VERSION ""

NS_ :

BS_:

BU_:

BO_ 2364626430 ECCP17: 8 Vector__XXX
 SG_ EngineCylinder17Timing1Pressure : 0|16@1+ (0.0009765625,0) [0|62.7490234375] "MPa" Vector__XXX
 SG_ EngineCylinder17Timing2Pressure : 16|16@1+ (0.0009765625,0) [0|62.7490234375] "MPa" Vector__XXX
 SG_ EngineCylinder17Timing3Pressure : 32|16@1+ (0.0009765625,0) [0|62.7490234375] "MPa" Vector__XXX
 SG_ EngineCylinder17Timing4Pressure : 48|16@1+ (0.0009765625,0) [0|62.7490234375] "MPa" Vector__XXX

BO_ 2364626686 ECCP18: 8 Vector__XXX
 SG_ EngineCylinder18Timing1Pressure : 0|16@1+ (0.0009765625,0) [0|62.7490234375] "MPa" Vector__XXX
 SG_ EngineCylinder18Timing2Pressure : 16|16@1+ (0.0009765625,0) [0|62.7490234375] "MPa" Vector__XXX
 SG_ EngineCylinder18Timing3Pressure : 32|16@1+ (0.0009765625,0) [0|62.7490234375] "MPa" Vector__XXX
 SG_ EngineCylinder18Timing4Pressure : 48|16@1+ (0.0009765625,0) [0|62.7490234375] "MPa" Vector__XXX

BO_ 2364626942 ECCP19: 8 Vector__XXX
 SG_ EngineCylinder19Timing1Pressure : 0|16@1+ (0.0009765625,0) [0|62.7490234375] "MPa" Vector__XXX
 SG_ EngineCylinder19Timing2Pressure : 16|16@1+ (0.0009765625,0) [0|62.7490234375] "MPa" Vector__XXX
 SG_ EngineCylinder19Timing3Pressure : 32|16@1+ (0.0009765625,0) [0|62.7490234375] "MPa" Vector__XXX
 SG_ EngineCylinder19Timing4Pressure : 48|16@1+ (0.0009765625,0) [0|62.7490234375] "MPa" Vector__XXX

BO_ 2364627198 ECCP20: 8 Vector__XXX
 SG_ EngineCylinder20Timing1Pressure : 0|16@1+ (0.0009765625,0) [0|62.7490234375] "MPa" Vector__XXX
 SG_ EngineCylinder20Timing2Pressure : 16|16@1+ (0.0009765625,0) [0|62.7490234375] "MPa" Vector__XXX
 SG_ EngineCylinder20Timing3Pressure : 32|16@1+ (0.0009765625,0) [0|62.7490234375] "MPa" Vector__XXX
 SG_ EngineCylinder20Timing4Pressure : 48|16@1+ (0.0009765625,0) [0|62.7490234375] "MPa" Vector__XXX

BO_ 2364627454 ECCT1: 8 Vector__XXX
 SG_ EngnClndr1InstntnsCmstnTmngPnt1 : 32|16@1+ (0.00390625,-125) [-125|125.99609375] "deg" Vector__XXX
 SG_ EngnClndr1InstntnsCmstnTmngPnt2 : 48|16@1+ (0.00390625,-125) [-125|125.99609375] "deg" Vector__XXX
 SG_ ECd1IsttsSttOCstT : 0|16@1+ (0.00390625,-125) [-125|125.99609375] "deg" Vector__XXX
 SG_ ECd1IsttsCtOCstT : 16|16@1+ (0.00390625,-125) [-125|125.99609375] "deg" Vector__XXX

BO_ 2364627710 ECCT2: 8 Vector__XXX
 SG_ EngnClndr2InstntnsCmstnTmngPnt1 : 32|16@1+ (0.00390625,-125) [-125|125.99609375] "deg" Vector__XXX
 SG_ EngnClndr2InstntnsCmstnTmngPnt2 : 48|16@1+ (0.00390625,-125) [-125|125.99609375] "deg" Vector__XXX
 SG_ ECd2IsttsSttOCstT : 0|16@1+ (0.00390625,-125) [-125|125.99609375] "deg" Vector__XXX
 SG_ ECd2IsttsCtOCstT : 16|16@1+ (0.00390625,-125) [-125|125.99609375] "deg" Vector__XXX

BO_ 2364627966 ECCT3: 8 Vector__XXX
 SG_ EngnClndr3InstntnsCmstnTmngPnt1 : 32|16@1+ (0.00390625,-125) [-125|125.99609375] "deg" Vector__XXX
 SG_ EngnClndr3InstntnsCmstnTmngPnt2 : 48|16@1+ (0.00390625,-125) [-125|125.99609375] "deg" Vector__XXX
 SG_ ECd3IsttsSttOCstT : 0|16@1+ (0.00390625,-125) [-125|125.99609375] "deg" Vector__XXX
 SG_ ECd3IsttsCtOCstT : 16|16@1+ (0.00390625,-125) [-125|125.99609375] "deg" Vector__XXX

BO_ 2364628222 ECCT4: 8 Vector__XXX
 SG_ EngnClndr4InstntnsCmstnTmngPnt1 : 32|16@1+ (0.00390625,-125) [-125|125.99609375] "deg" Vector__XXX
 SG_ EngnClndr4InstntnsCmstnTmngPnt2 : 48|16@1+ (0.00390625,-125) [-125|125.99609375] "deg" Vector__XXX
 SG_ ECd4IsttsSttOCstT : 0|16@1+ (0.00390625,-125) [-125|125.99609375] "deg" Vector__XXX
 SG_ ECd4IsttsCtOCstT : 16|16@1+ (0.00390625,-125) [-125|125.99609375] "deg" Vector__XXX

BO_ 2364628478 ECCT5: 8 Vector__XXX
 SG_ EngnClndr5InstntnsCmstnTmngPnt1 : 32|16@1+ (0.00390625,-125) [-125|125.99609375] "deg" Vector__XXX
 SG_ EngnClndr5InstntnsCmstnTmngPnt2 : 48|16@1+ (0.00390625,-125) [-125|125.99609375] "deg" Vector__XXX
 SG_ ECd5IsttsSttOCstT : 0|16@1+ (0.00390625,-125) [-125|125.99609375] "deg" Vector__XXX
 SG_ ECd5IsttsCtOCstT : 16|16@1+ (0.00390625,-125) [-125|125.99609375] "deg" Vector__XXX

BO_ 2364628734 ECCT6: 8 Vector__XXX
 SG_ EngnClndr6InstntnsCmstnTmngPnt1 : 32|16@1+ (0.00390625,-125) [-125|125.99609375] "deg" Vector__XXX
 SG_ EngnClndr6InstntnsCmstnTmngPnt2 : 48|16@1+ (0.00390625,-125) [-125|125.99609375] "deg" Vector__XXX
 SG_ ECd6IsttsSttOCstT : 0|16@1+ (0.00390625,-125) [-125|125.99609375] "deg" Vector__XXX
 SG_ ECd6IsttsCtOCstT : 16|16@1+ (0.00390625,-125) [-125|125.99609375] "deg" Vector__XXX

BO_ 2364628990 ECCT7: 8 Vector__XXX
 SG_ EngnClndr7InstntnsCmstnTmngPnt1 : 32|16@1+ (0.00390625,-125) [-125|125.99609375] "deg" Vector__XXX
 SG_ EngnClndr7InstntnsCmstnTmngPnt2 : 48|16@1+ (0.00390625,-125) [-125|125.99609375] "deg" Vector__XXX
 SG_ ECd7IsttsSttOCstT : 0|16@1+ (0.00390625,-125) [-125|125.99609375] "deg" Vector__XXX
 SG_ ECd7IsttsCtOCstT : 16|16@1+ (0.00390625,-125) [-125|125.99609375] "deg" Vector__XXX

BO_ 2364629246 ECCT8: 8 Vector__XXX
 SG_ EngnClndr8InstntnsCmstnTmngPnt1 : 32|16@1+ (0.00390625,-125) [-125|125.99609375] "deg" Vector__XXX
 SG_ EngnClndr8InstntnsCmstnTmngPnt2 : 48|16@1+ (0.00390625,-125) [-125|125.99609375] "deg" Vector__XXX
 SG_ ECd8IsttsSttOCstT : 0|16@1+ (0.00390625,-125) [-125|125.99609375] "deg" Vector__XXX
 SG_ ECd8IsttsCtOCstT : 16|16@1+ (0.00390625,-125) [-125|125.99609375] "deg" Vector__XXX

BO_ 2364629502 ECCT9: 8 Vector__XXX
 SG_ EngnClndr9InstntnsCmstnTmngPnt1 : 32|16@1+ (0.00390625,-125) [-125|125.99609375] "deg" Vector__XXX
 SG_ EngnClndr9InstntnsCmstnTmngPnt2 : 48|16@1+ (0.00390625,-125) [-125|125.99609375] "deg" Vector__XXX
 SG_ ECd9IsttsSttOCstT : 0|16@1+ (0.00390625,-125) [-125|125.99609375] "deg" Vector__XXX
 SG_ ECd9IsttsCtOCstT : 16|16@1+ (0.00390625,-125) [-125|125.99609375] "deg" Vector__XXX

BO_ 2364629758 ECCT10: 8 Vector__XXX
 SG_ ECd10IsttsCstTPt1 : 32|16@1+ (0.00390625,-125) [-125|125.99609375] "deg" Vector__XXX
 SG_ ECd10IsttsCstTPt2 : 48|16@1+ (0.00390625,-125) [-125|125.99609375] "deg" Vector__XXX
 SG_ ECd10IsttsSttOCstT : 0|16@1+ (0.00390625,-125) [-125|125.99609375] "deg" Vector__XXX
 SG_ ECd10IsttsCtOCstT : 16|16@1+ (0.00390625,-125) [-125|125.99609375] "deg" Vector__XXX

BO_ 2364630014 ECCT11: 8 Vector__XXX
 SG_ ECd11IsttsCstTPt1 : 32|16@1+ (0.00390625,-125) [-125|125.99609375] "deg" Vector__XXX
 SG_ ECd11IsttsCstTPt2 : 48|16@1+ (0.00390625,-125) [-125|125.99609375] "deg" Vector__XXX
 SG_ ECd11IsttsSttOCstT : 0|16@1+ (0.00390625,-125) [-125|125.99609375] "deg" Vector__XXX
 SG_ ECd11IsttsCtOCstT : 16|16@1+ (0.00390625,-125) [-125|125.99609375] "deg" Vector__XXX

BO_ 2364630270 ECCT12: 8 Vector__XXX
 SG_ ECd12IsttsCstTPt1 : 32|16@1+ (0.00390625,-125) [-125|125.99609375] "deg" Vector__XXX
 SG_ ECd12IsttsCstTPt2 : 48|16@1+ (0.00390625,-125) [-125|125.99609375] "deg" Vector__XXX
 SG_ ECd12IsttsSttOCstT : 0|16@1+ (0.00390625,-125) [-125|125.99609375] "deg" Vector__XXX
 SG_ ECd12IsttsCtOCstT : 16|16@1+ (0.00390625,-125) [-125|125.99609375] "deg" Vector__XXX

BO_ 2364630526 ECCT13: 8 Vector__XXX
 SG_ ECd13IsttsCstTPt1 : 32|16@1+ (0.00390625,-125) [-125|125.99609375] "deg" Vector__XXX
 SG_ ECd13IsttsCstTPt2 : 48|16@1+ (0.00390625,-125) [-125|125.99609375] "deg" Vector__XXX
 SG_ ECd13IsttsSttOCstT : 0|16@1+ (0.00390625,-125) [-125|125.99609375] "deg" Vector__XXX
 SG_ ECd13IsttsCtOCstT : 16|16@1+ (0.00390625,-125) [-125|125.99609375] "deg" Vector__XXX

BO_ 2364630782 ECCT14: 8 Vector__XXX
 SG_ ECd14IsttsCstTPt1 : 32|16@1+ (0.00390625,-125) [-125|125.99609375] "deg" Vector__XXX
 SG_ ECd14IsttsCstTPt2 : 48|16@1+ (0.00390625,-125) [-125|125.99609375] "deg" Vector__XXX
 SG_ ECd14IsttsSttOCstT : 0|16@1+ (0.00390625,-125) [-125|125.99609375] "deg" Vector__XXX
 SG_ ECd14IsttsCtOCstT : 16|16@1+ (0.00390625,-125) [-125|125.99609375] "deg" Vector__XXX

BO_ 2364631038 ECCT15: 8 Vector__XXX
 SG_ ECd15IsttsCstTPt1 : 32|16@1+ (0.00390625,-125) [-125|125.99609375] "deg" Vector__XXX
 SG_ ECd15IsttsCstTPt2 : 48|16@1+ (0.00390625,-125) [-125|125.99609375] "deg" Vector__XXX
 SG_ ECd15IsttsSttOCstT : 0|16@1+ (0.00390625,-125) [-125|125.99609375] "deg" Vector__XXX
 SG_ ECd15IsttsCtOCstT : 16|16@1+ (0.00390625,-125) [-125|125.99609375] "deg" Vector__XXX

BO_ 2364631294 ECCT16: 8 Vector__XXX
 SG_ ECd16IsttsCstTPt1 : 32|16@1+ (0.00390625,-125) [-125|125.99609375] "deg" Vector__XXX
 SG_ ECd16IsttsCstTPt2 : 48|16@1+ (0.00390625,-125) [-125|125.99609375] "deg" Vector__XXX
 SG_ ECd16IsttsSttOCstT : 0|16@1+ (0.00390625,-125) [-125|125.99609375] "deg" Vector__XXX
 SG_ ECd16IsttsCtOCstT : 16|16@1+ (0.00390625,-125) [-125|125.99609375] "deg" Vector__XXX

BO_ 2364631550 ECCT17: 8 Vector__XXX
 SG_ ECd17IsttsCstTPt1 : 32|16@1+ (0.00390625,-125) [-125|125.99609375] "deg" Vector__XXX
 SG_ ECd17IsttsCstTPt2 : 48|16@1+ (0.00390625,-125) [-125|125.99609375] "deg" Vector__XXX
 SG_ ECd17IsttsSttOCstT : 0|16@1+ (0.00390625,-125) [-125|125.99609375] "deg" Vector__XXX
 SG_ ECd17IsttsCtOCstT : 16|16@1+ (0.00390625,-125) [-125|125.99609375] "deg" Vector__XXX

BO_ 2364631806 ECCT18: 8 Vector__XXX
 SG_ ECd18IsttsCstTPt1 : 32|16@1+ (0.00390625,-125) [-125|125.99609375] "deg" Vector__XXX
 SG_ ECd18IsttsCstTPt2 : 48|16@1+ (0.00390625,-125) [-125|125.99609375] "deg" Vector__XXX
 SG_ ECd18IsttsSttOCstT : 0|16@1+ (0.00390625,-125) [-125|125.99609375] "deg" Vector__XXX
 SG_ ECd18IsttsCtOCstT : 16|16@1+ (0.00390625,-125) [-125|125.99609375] "deg" Vector__XXX

BO_ 2364632062 ECCT19: 8 Vector__XXX
 SG_ ECd19IsttsCstTPt1 : 32|16@1+ (0.00390625,-125) [-125|125.99609375] "deg" Vector__XXX
 SG_ ECd19IsttsCstTPt2 : 48|16@1+ (0.00390625,-125) [-125|125.99609375] "deg" Vector__XXX
 SG_ ECd19IsttsSttOCstT : 0|16@1+ (0.00390625,-125) [-125|125.99609375] "deg" Vector__XXX
 SG_ ECd19IsttsCtOCstT : 16|16@1+ (0.00390625,-125) [-125|125.99609375] "deg" Vector__XXX

BO_ 2364632318 ECCT20: 8 Vector__XXX
 SG_ ECd20IsttsCstTPt1 : 32|16@1+ (0.00390625,-125) [-125|125.99609375] "deg" Vector__XXX
 SG_ ECd20IsttsCstTPt2 : 48|16@1+ (0.00390625,-125) [-125|125.99609375] "deg" Vector__XXX
 SG_ ECd20IsttsSttOCstT : 0|16@1+ (0.00390625,-125) [-125|125.99609375] "deg" Vector__XXX
 SG_ ECd20IsttsCtOCstT : 16|16@1+ (0.00390625,-125) [-125|125.99609375] "deg" Vector__XXX

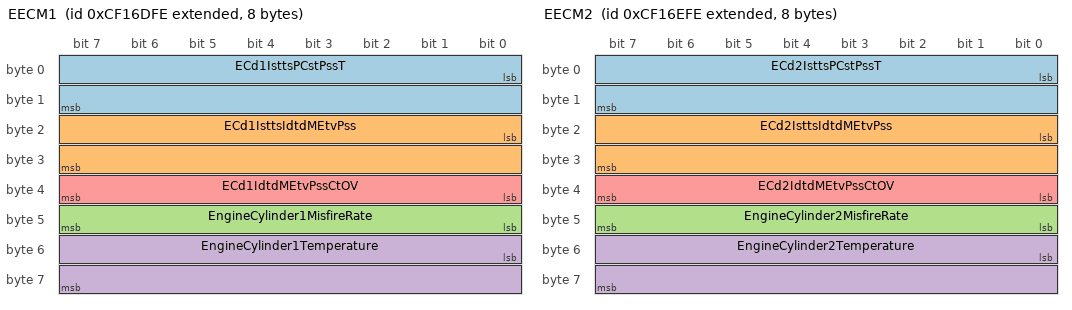
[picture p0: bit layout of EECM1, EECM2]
BO_ 2364632574 EECM1: 8 Vector__XXX
 SG_ ECd1IsttsPCstPssT : 0|16@1+ (0.00390625,-125) [-125|125.99609375] "deg" Vector__XXX
 SG_ ECd1IsttsIdtdMEtvPss : 16|16@1+ (0.0001220703125,-1) [-1|6.8436279296875] "MPa" Vector__XXX
 SG_ EngineCylinder1MisfireRate : 40|8@1+ (0.4,0) [0|100] "%" Vector__XXX
 SG_ EngineCylinder1Temperature : 48|16@1+ (0.03125,-273) [-273|1734.96875] "degC" Vector__XXX
 SG_ ECd1IdtdMEtvPssCtOV : 32|8@1+ (0.04,0) [0|10] "%" Vector__XXX

BO_ 2364632830 EECM2: 8 Vector__XXX
 SG_ ECd2IsttsPCstPssT : 0|16@1+ (0.00390625,-125) [-125|125.99609375] "deg" Vector__XXX
 SG_ ECd2IsttsIdtdMEtvPss : 16|16@1+ (0.0001220703125,-1) [-1|6.8436279296875] "MPa" Vector__XXX
 SG_ EngineCylinder2MisfireRate : 40|8@1+ (0.4,0) [0|100] "%" Vector__XXX
 SG_ EngineCylinder2Temperature : 48|16@1+ (0.03125,-273) [-273|1734.96875] "degC" Vector__XXX
 SG_ ECd2IdtdMEtvPssCtOV : 32|8@1+ (0.04,0) [0|10] "%" Vector__XXX

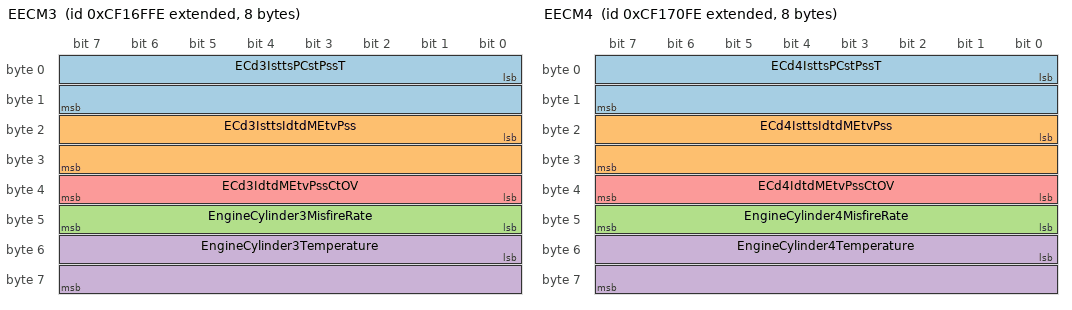
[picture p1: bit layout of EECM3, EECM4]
BO_ 2364633086 EECM3: 8 Vector__XXX
 SG_ ECd3IsttsPCstPssT : 0|16@1+ (0.00390625,-125) [-125|125.99609375] "deg" Vector__XXX
 SG_ ECd3IsttsIdtdMEtvPss : 16|16@1+ (0.0001220703125,-1) [-1|6.8436279296875] "MPa" Vector__XXX
 SG_ EngineCylinder3MisfireRate : 40|8@1+ (0.4,0) [0|100] "%" Vector__XXX
 SG_ EngineCylinder3Temperature : 48|16@1+ (0.03125,-273) [-273|1734.96875] "degC" Vector__XXX
 SG_ ECd3IdtdMEtvPssCtOV : 32|8@1+ (0.04,0) [0|10] "%" Vector__XXX

BO_ 2364633342 EECM4: 8 Vector__XXX
 SG_ ECd4IsttsPCstPssT : 0|16@1+ (0.00390625,-125) [-125|125.99609375] "deg" Vector__XXX
 SG_ ECd4IsttsIdtdMEtvPss : 16|16@1+ (0.0001220703125,-1) [-1|6.8436279296875] "MPa" Vector__XXX
 SG_ EngineCylinder4MisfireRate : 40|8@1+ (0.4,0) [0|100] "%" Vector__XXX
 SG_ EngineCylinder4Temperature : 48|16@1+ (0.03125,-273) [-273|1734.96875] "degC" Vector__XXX
 SG_ ECd4IdtdMEtvPssCtOV : 32|8@1+ (0.04,0) [0|10] "%" Vector__XXX

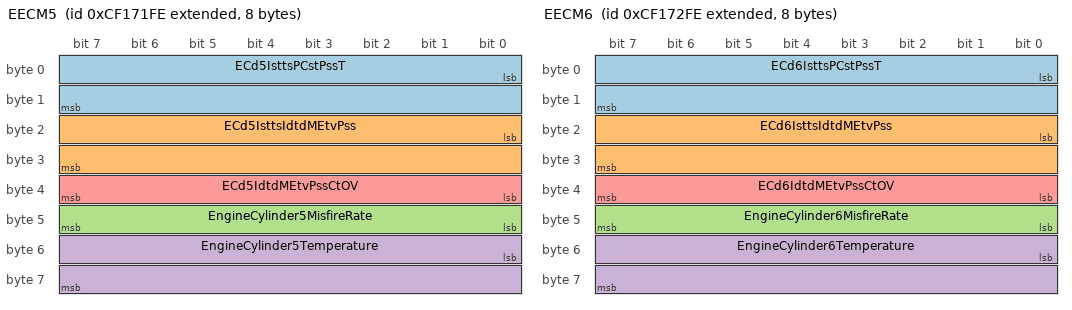
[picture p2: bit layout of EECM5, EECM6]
BO_ 2364633598 EECM5: 8 Vector__XXX
 SG_ ECd5IsttsPCstPssT : 0|16@1+ (0.00390625,-125) [-125|125.99609375] "deg" Vector__XXX
 SG_ ECd5IsttsIdtdMEtvPss : 16|16@1+ (0.0001220703125,-1) [-1|6.8436279296875] "MPa" Vector__XXX
 SG_ EngineCylinder5MisfireRate : 40|8@1+ (0.4,0) [0|100] "%" Vector__XXX
 SG_ EngineCylinder5Temperature : 48|16@1+ (0.03125,-273) [-273|1734.96875] "degC" Vector__XXX
 SG_ ECd5IdtdMEtvPssCtOV : 32|8@1+ (0.04,0) [0|10] "%" Vector__XXX

BO_ 2364633854 EECM6: 8 Vector__XXX
 SG_ ECd6IsttsPCstPssT : 0|16@1+ (0.00390625,-125) [-125|125.99609375] "deg" Vector__XXX
 SG_ ECd6IsttsIdtdMEtvPss : 16|16@1+ (0.0001220703125,-1) [-1|6.8436279296875] "MPa" Vector__XXX
 SG_ EngineCylinder6MisfireRate : 40|8@1+ (0.4,0) [0|100] "%" Vector__XXX
 SG_ EngineCylinder6Temperature : 48|16@1+ (0.03125,-273) [-273|1734.96875] "degC" Vector__XXX
 SG_ ECd6IdtdMEtvPssCtOV : 32|8@1+ (0.04,0) [0|10] "%" Vector__XXX

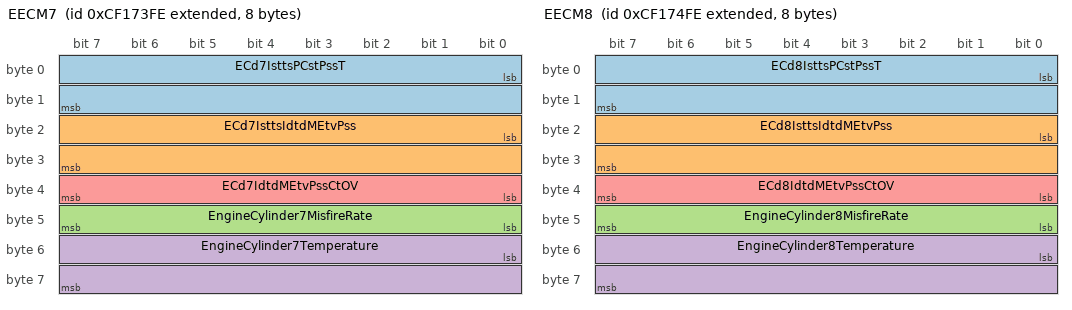
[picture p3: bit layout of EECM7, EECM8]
BO_ 2364634110 EECM7: 8 Vector__XXX
 SG_ ECd7IsttsPCstPssT : 0|16@1+ (0.00390625,-125) [-125|125.99609375] "deg" Vector__XXX
 SG_ ECd7IsttsIdtdMEtvPss : 16|16@1+ (0.0001220703125,-1) [-1|6.8436279296875] "MPa" Vector__XXX
 SG_ EngineCylinder7MisfireRate : 40|8@1+ (0.4,0) [0|100] "%" Vector__XXX
 SG_ EngineCylinder7Temperature : 48|16@1+ (0.03125,-273) [-273|1734.96875] "degC" Vector__XXX
 SG_ ECd7IdtdMEtvPssCtOV : 32|8@1+ (0.04,0) [0|10] "%" Vector__XXX

BO_ 2364634366 EECM8: 8 Vector__XXX
 SG_ ECd8IsttsPCstPssT : 0|16@1+ (0.00390625,-125) [-125|125.99609375] "deg" Vector__XXX
 SG_ ECd8IsttsIdtdMEtvPss : 16|16@1+ (0.0001220703125,-1) [-1|6.8436279296875] "MPa" Vector__XXX
 SG_ EngineCylinder8MisfireRate : 40|8@1+ (0.4,0) [0|100] "%" Vector__XXX
 SG_ EngineCylinder8Temperature : 48|16@1+ (0.03125,-273) [-273|1734.96875] "degC" Vector__XXX
 SG_ ECd8IdtdMEtvPssCtOV : 32|8@1+ (0.04,0) [0|10] "%" Vector__XXX

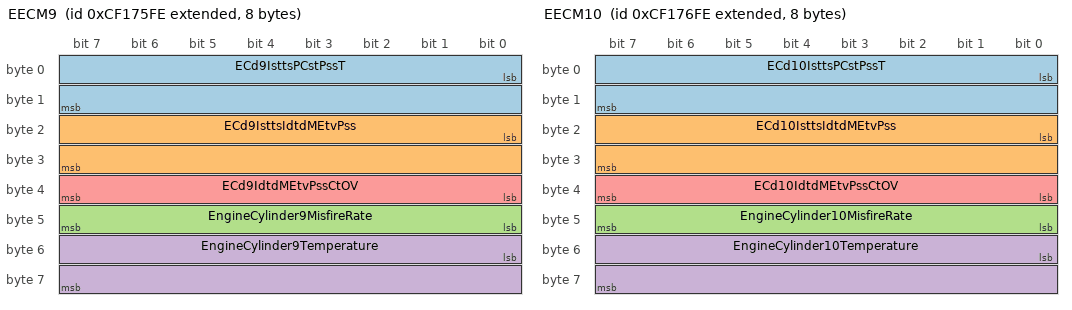
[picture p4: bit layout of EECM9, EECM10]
BO_ 2364634622 EECM9: 8 Vector__XXX
 SG_ ECd9IsttsPCstPssT : 0|16@1+ (0.00390625,-125) [-125|125.99609375] "deg" Vector__XXX
 SG_ ECd9IsttsIdtdMEtvPss : 16|16@1+ (0.0001220703125,-1) [-1|6.8436279296875] "MPa" Vector__XXX
 SG_ EngineCylinder9MisfireRate : 40|8@1+ (0.4,0) [0|100] "%" Vector__XXX
 SG_ EngineCylinder9Temperature : 48|16@1+ (0.03125,-273) [-273|1734.96875] "degC" Vector__XXX
 SG_ ECd9IdtdMEtvPssCtOV : 32|8@1+ (0.04,0) [0|10] "%" Vector__XXX

BO_ 2364634878 EECM10: 8 Vector__XXX
 SG_ ECd10IsttsPCstPssT : 0|16@1+ (0.00390625,-125) [-125|125.99609375] "deg" Vector__XXX
 SG_ ECd10IsttsIdtdMEtvPss : 16|16@1+ (0.0001220703125,-1) [-1|6.8436279296875] "MPa" Vector__XXX
 SG_ EngineCylinder10MisfireRate : 40|8@1+ (0.4,0) [0|100] "%" Vector__XXX
 SG_ EngineCylinder10Temperature : 48|16@1+ (0.03125,-273) [-273|1734.96875] "degC" Vector__XXX
 SG_ ECd10IdtdMEtvPssCtOV : 32|8@1+ (0.04,0) [0|10] "%" Vector__XXX

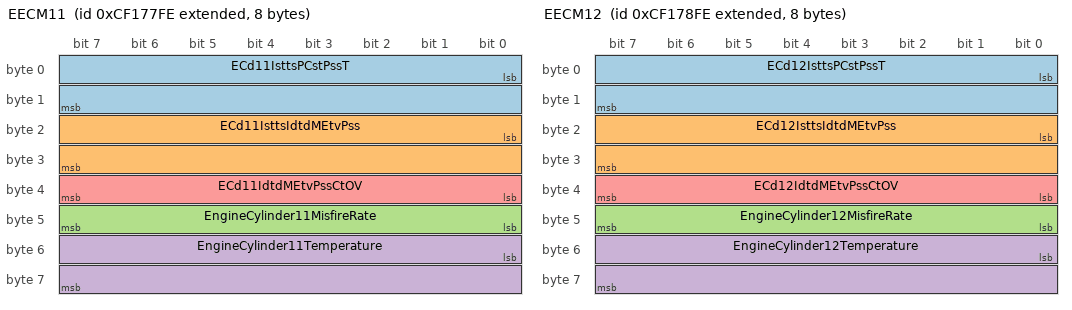
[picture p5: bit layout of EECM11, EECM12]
BO_ 2364635134 EECM11: 8 Vector__XXX
 SG_ ECd11IsttsPCstPssT : 0|16@1+ (0.00390625,-125) [-125|125.99609375] "deg" Vector__XXX
 SG_ ECd11IsttsIdtdMEtvPss : 16|16@1+ (0.0001220703125,-1) [-1|6.8436279296875] "MPa" Vector__XXX
 SG_ EngineCylinder11MisfireRate : 40|8@1+ (0.4,0) [0|100] "%" Vector__XXX
 SG_ EngineCylinder11Temperature : 48|16@1+ (0.03125,-273) [-273|1734.96875] "degC" Vector__XXX
 SG_ ECd11IdtdMEtvPssCtOV : 32|8@1+ (0.04,0) [0|10] "%" Vector__XXX

BO_ 2364635390 EECM12: 8 Vector__XXX
 SG_ ECd12IsttsPCstPssT : 0|16@1+ (0.00390625,-125) [-125|125.99609375] "deg" Vector__XXX
 SG_ ECd12IsttsIdtdMEtvPss : 16|16@1+ (0.0001220703125,-1) [-1|6.8436279296875] "MPa" Vector__XXX
 SG_ EngineCylinder12MisfireRate : 40|8@1+ (0.4,0) [0|100] "%" Vector__XXX
 SG_ EngineCylinder12Temperature : 48|16@1+ (0.03125,-273) [-273|1734.96875] "degC" Vector__XXX
 SG_ ECd12IdtdMEtvPssCtOV : 32|8@1+ (0.04,0) [0|10] "%" Vector__XXX

BO_ 2364635646 EECM13: 8 Vector__XXX
 SG_ ECd13IsttsPCstPssT : 0|16@1+ (0.00390625,-125) [-125|125.99609375] "deg" Vector__XXX
 SG_ ECd13IsttsIdtdMEtvPss : 16|16@1+ (0.0001220703125,-1) [-1|6.8436279296875] "MPa" Vector__XXX
 SG_ EngineCylinder13MisfireRate : 40|8@1+ (0.4,0) [0|100] "%" Vector__XXX
 SG_ EngineCylinder13Temperature : 48|16@1+ (0.03125,-273) [-273|1734.96875] "degC" Vector__XXX
 SG_ ECd13IdtdMEtvPssCtOV : 32|8@1+ (0.04,0) [0|10] "%" Vector__XXX

BO_ 2364635902 EECM14: 8 Vector__XXX
 SG_ ECd14IsttsPCstPssT : 0|16@1+ (0.00390625,-125) [-125|125.99609375] "deg" Vector__XXX
 SG_ ECd14IsttsIdtdMEtvPss : 16|16@1+ (0.0001220703125,-1) [-1|6.8436279296875] "MPa" Vector__XXX
 SG_ EngineCylinder14MisfireRate : 40|8@1+ (0.4,0) [0|100] "%" Vector__XXX
 SG_ EngineCylinder14Temperature : 48|16@1+ (0.03125,-273) [-273|1734.96875] "degC" Vector__XXX
 SG_ ECd14IdtdMEtvPssCtOV : 32|8@1+ (0.04,0) [0|10] "%" Vector__XXX

BO_ 2364636158 EECM15: 8 Vector__XXX
 SG_ ECd15IsttsPCstPssT : 0|16@1+ (0.00390625,-125) [-125|125.99609375] "deg" Vector__XXX
 SG_ ECd15IsttsIdtdMEtvPss : 16|16@1+ (0.0001220703125,-1) [-1|6.8436279296875] "MPa" Vector__XXX
 SG_ EngineCylinder15MisfireRate : 40|8@1+ (0.4,0) [0|100] "%" Vector__XXX
 SG_ EngineCylinder15Temperature : 48|16@1+ (0.03125,-273) [-273|1734.96875] "degC" Vector__XXX
 SG_ ECd15IdtdMEtvPssCtOV : 32|8@1+ (0.04,0) [0|10] "%" Vector__XXX

BO_ 2364636414 EECM16: 8 Vector__XXX
 SG_ ECd16IsttsPCstPssT : 0|16@1+ (0.00390625,-125) [-125|125.99609375] "deg" Vector__XXX
 SG_ ECd16IsttsIdtdMEtvPss : 16|16@1+ (0.0001220703125,-1) [-1|6.8436279296875] "MPa" Vector__XXX
 SG_ EngineCylinder16MisfireRate : 40|8@1+ (0.4,0) [0|100] "%" Vector__XXX
 SG_ EngineCylinder16Temperature : 48|16@1+ (0.03125,-273) [-273|1734.96875] "degC" Vector__XXX
 SG_ ECd16IdtdMEtvPssCtOV : 32|8@1+ (0.04,0) [0|10] "%" Vector__XXX

BO_ 2364636670 EECM17: 8 Vector__XXX
 SG_ ECd17IsttsPCstPssT : 0|16@1+ (0.00390625,-125) [-125|125.99609375] "deg" Vector__XXX
 SG_ ECd17IsttsIdtdMEtvPss : 16|16@1+ (0.0001220703125,-1) [-1|6.8436279296875] "MPa" Vector__XXX
 SG_ EngineCylinder17MisfireRate : 40|8@1+ (0.4,0) [0|100] "%" Vector__XXX
 SG_ EngineCylinder17Temperature : 48|16@1+ (0.03125,-273) [-273|1734.96875] "degC" Vector__XXX
 SG_ ECd17IdtdMEtvPssCtOV : 32|8@1+ (0.04,0) [0|10] "%" Vector__XXX

BO_ 2364636926 EECM18: 8 Vector__XXX
 SG_ ECd18IsttsPCstPssT : 0|16@1+ (0.00390625,-125) [-125|125.99609375] "deg" Vector__XXX
 SG_ ECd18IsttsIdtdMEtvPss : 16|16@1+ (0.0001220703125,-1) [-1|6.8436279296875] "MPa" Vector__XXX
 SG_ EngineCylinder18MisfireRate : 40|8@1+ (0.4,0) [0|100] "%" Vector__XXX
 SG_ EngineCylinder18Temperature : 48|16@1+ (0.03125,-273) [-273|1734.96875] "degC" Vector__XXX
 SG_ ECd18IdtdMEtvPssCtOV : 32|8@1+ (0.04,0) [0|10] "%" Vector__XXX

BO_ 2364637182 EECM19: 8 Vector__XXX
 SG_ ECd19IsttsPCstPssT : 0|16@1+ (0.00390625,-125) [-125|125.99609375] "deg" Vector__XXX
 SG_ ECd19IsttsIdtdMEtvPss : 16|16@1+ (0.0001220703125,-1) [-1|6.8436279296875] "MPa" Vector__XXX
 SG_ EngineCylinder19MisfireRate : 40|8@1+ (0.4,0) [0|100] "%" Vector__XXX
 SG_ EngineCylinder19Temperature : 48|16@1+ (0.03125,-273) [-273|1734.96875] "degC" Vector__XXX
 SG_ ECd19IdtdMEtvPssCtOV : 32|8@1+ (0.04,0) [0|10] "%" Vector__XXX

BO_ 2364637438 EECM20: 8 Vector__XXX
 SG_ ECd20IsttsPCstPssT : 0|16@1+ (0.00390625,-125) [-125|125.99609375] "deg" Vector__XXX
 SG_ ECd20IsttsIdtdMEtvPss : 16|16@1+ (0.0001220703125,-1) [-1|6.8436279296875] "MPa" Vector__XXX
 SG_ EngineCylinder20MisfireRate : 40|8@1+ (0.4,0) [0|100] "%" Vector__XXX
 SG_ EngineCylinder20Temperature : 48|16@1+ (0.03125,-273) [-273|1734.96875] "degC" Vector__XXX
 SG_ ECd20IdtdMEtvPssCtOV : 32|8@1+ (0.04,0) [0|10] "%" Vector__XXX

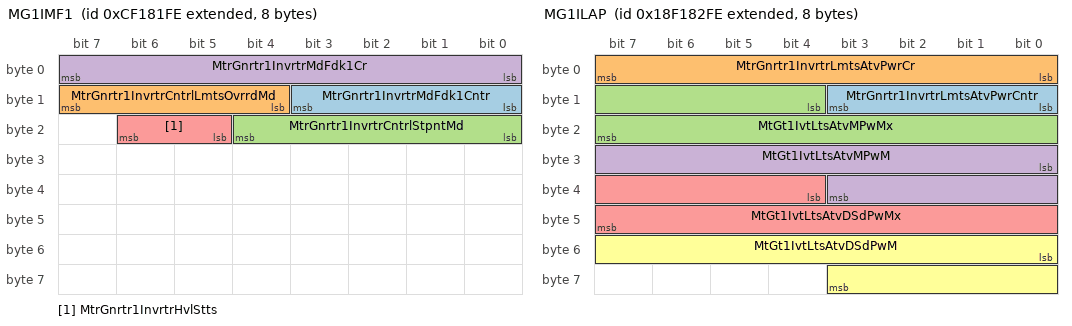
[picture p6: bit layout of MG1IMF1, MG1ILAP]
BO_ 2364637694 MG1IMF1: 8 Vector__XXX
 SG_ MtrGnrtr1InvrtrMdFdk1Cntr : 8|4@1+ (1,0) [0|15] "" Vector__XXX
 SG_ MtrGnrtr1InvrtrCntrlLmtsOvrrdMd : 12|4@1+ (1,0) [0|15] "" Vector__XXX
 SG_ MtrGnrtr1InvrtrCntrlStpntMd : 16|5@1+ (1,0) [0|31] "" Vector__XXX
 SG_ MtrGnrtr1InvrtrMdFdk1Cr : 0|8@1+ (1,0) [0|250] "count" Vector__XXX
 SG_ MtrGnrtr1InvrtrHvlStts : 21|2@1+ (1,0) [0|3] "" Vector__XXX

BO_ 2565964542 MG1ILAP: 8 Vector__XXX
 SG_ MtrGnrtr1InvrtrLmtsAtvPwrCntr : 8|4@1+ (1,0) [0|15] "" Vector__XXX
 SG_ MtrGnrtr1InvrtrLmtsAtvPwrCr : 0|8@1+ (1,0) [0|250] "count" Vector__XXX
 SG_ MtGt1IvtLtsAtvMPwMx : 12|12@1+ (0.0625,-125) [-125|125.9375] "%" Vector__XXX
 SG_ MtGt1IvtLtsAtvMPwM : 24|12@1+ (0.0625,-125) [-125|125.9375] "%" Vector__XXX
 SG_ MtGt1IvtLtsAtvDSdPwMx : 36|12@1+ (0.0625,-125) [-125|125.9375] "%" Vector__XXX
 SG_ MtGt1IvtLtsAtvDSdPwM : 48|12@1+ (0.0625,-125) [-125|125.9375] "%" Vector__XXX

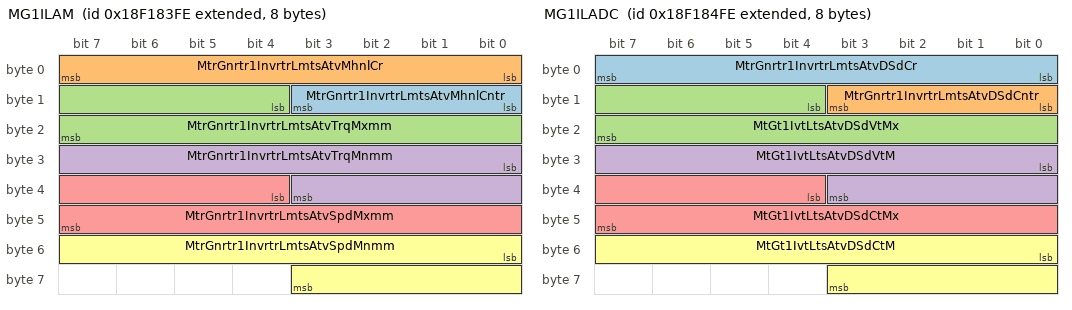
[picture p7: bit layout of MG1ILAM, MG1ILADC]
BO_ 2565964798 MG1ILAM: 8 Vector__XXX
 SG_ MtrGnrtr1InvrtrLmtsAtvMhnlCntr : 8|4@1+ (1,0) [0|15] "" Vector__XXX
 SG_ MtrGnrtr1InvrtrLmtsAtvMhnlCr : 0|8@1+ (1,0) [0|250] "count" Vector__XXX
 SG_ MtrGnrtr1InvrtrLmtsAtvTrqMxmm : 12|12@1+ (0.0625,-125) [-125|125.9375] "%" Vector__XXX
 SG_ MtrGnrtr1InvrtrLmtsAtvTrqMnmm : 24|12@1+ (0.0625,-125) [-125|125.9375] "%" Vector__XXX
 SG_ MtrGnrtr1InvrtrLmtsAtvSpdMxmm : 36|12@1+ (0.0625,-125) [-125|125.9375] "%" Vector__XXX
 SG_ MtrGnrtr1InvrtrLmtsAtvSpdMnmm : 48|12@1+ (0.0625,-125) [-125|125.9375] "%" Vector__XXX

BO_ 2565965054 MG1ILADC: 8 Vector__XXX
 SG_ MtrGnrtr1InvrtrLmtsAtvDSdCr : 0|8@1+ (1,0) [0|250] "count" Vector__XXX
 SG_ MtrGnrtr1InvrtrLmtsAtvDSdCntr : 8|4@1+ (1,0) [0|15] "" Vector__XXX
 SG_ MtGt1IvtLtsAtvDSdVtMx : 12|12@1+ (0.0625,-125) [-125|125.9375] "%" Vector__XXX
 SG_ MtGt1IvtLtsAtvDSdVtM : 24|12@1+ (0.0625,-125) [-125|125.9375] "%" Vector__XXX
 SG_ MtGt1IvtLtsAtvDSdCtMx : 36|12@1+ (0.0625,-125) [-125|125.9375] "%" Vector__XXX
 SG_ MtGt1IvtLtsAtvDSdCtM : 48|12@1+ (0.0625,-125) [-125|125.9375] "%" Vector__XXX

BO_ 2565965310 MG1ILV: 8 Vector__XXX
 SG_ MtrGnrtr1InvrtrSwthdIgntnVltg : 0|16@1+ (0.05,0) [0|3212.75] "V" Vector__XXX
 SG_ MtrGnrtr1InvrtrUnswthdSlVltg : 16|16@1+ (0.05,0) [0|3212.75] "V" Vector__XXX

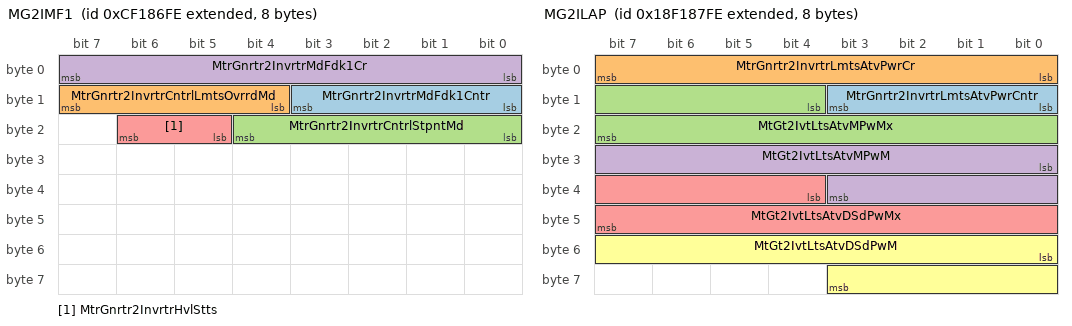
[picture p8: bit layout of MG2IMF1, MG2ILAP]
BO_ 2364638974 MG2IMF1: 8 Vector__XXX
 SG_ MtrGnrtr2InvrtrMdFdk1Cntr : 8|4@1+ (1,0) [0|15] "" Vector__XXX
 SG_ MtrGnrtr2InvrtrCntrlLmtsOvrrdMd : 12|4@1+ (1,0) [0|15] "" Vector__XXX
 SG_ MtrGnrtr2InvrtrCntrlStpntMd : 16|5@1+ (1,0) [0|31] "" Vector__XXX
 SG_ MtrGnrtr2InvrtrMdFdk1Cr : 0|8@1+ (1,0) [0|250] "count" Vector__XXX
 SG_ MtrGnrtr2InvrtrHvlStts : 21|2@1+ (1,0) [0|3] "" Vector__XXX

BO_ 2565965822 MG2ILAP: 8 Vector__XXX
 SG_ MtrGnrtr2InvrtrLmtsAtvPwrCntr : 8|4@1+ (1,0) [0|15] "" Vector__XXX
 SG_ MtrGnrtr2InvrtrLmtsAtvPwrCr : 0|8@1+ (1,0) [0|250] "count" Vector__XXX
 SG_ MtGt2IvtLtsAtvMPwMx : 12|12@1+ (0.0625,-125) [-125|125.9375] "%" Vector__XXX
 SG_ MtGt2IvtLtsAtvMPwM : 24|12@1+ (0.0625,-125) [-125|125.9375] "%" Vector__XXX
 SG_ MtGt2IvtLtsAtvDSdPwMx : 36|12@1+ (0.0625,-125) [-125|125.9375] "%" Vector__XXX
 SG_ MtGt2IvtLtsAtvDSdPwM : 48|12@1+ (0.0625,-125) [-125|125.9375] "%" Vector__XXX

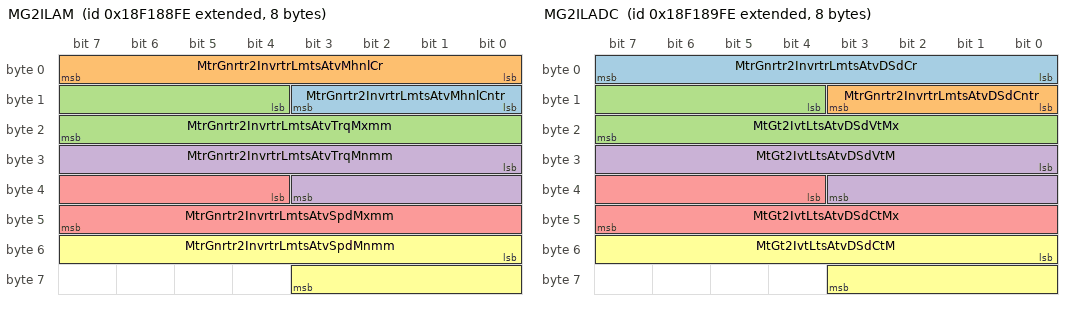
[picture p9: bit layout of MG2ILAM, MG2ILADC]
BO_ 2565966078 MG2ILAM: 8 Vector__XXX
 SG_ MtrGnrtr2InvrtrLmtsAtvMhnlCntr : 8|4@1+ (1,0) [0|15] "" Vector__XXX
 SG_ MtrGnrtr2InvrtrLmtsAtvMhnlCr : 0|8@1+ (1,0) [0|250] "count" Vector__XXX
 SG_ MtrGnrtr2InvrtrLmtsAtvTrqMxmm : 12|12@1+ (0.0625,-125) [-125|125.9375] "%" Vector__XXX
 SG_ MtrGnrtr2InvrtrLmtsAtvTrqMnmm : 24|12@1+ (0.0625,-125) [-125|125.9375] "%" Vector__XXX
 SG_ MtrGnrtr2InvrtrLmtsAtvSpdMxmm : 36|12@1+ (0.0625,-125) [-125|125.9375] "%" Vector__XXX
 SG_ MtrGnrtr2InvrtrLmtsAtvSpdMnmm : 48|12@1+ (0.0625,-125) [-125|125.9375] "%" Vector__XXX

BO_ 2565966334 MG2ILADC: 8 Vector__XXX
 SG_ MtrGnrtr2InvrtrLmtsAtvDSdCr : 0|8@1+ (1,0) [0|250] "count" Vector__XXX
 SG_ MtrGnrtr2InvrtrLmtsAtvDSdCntr : 8|4@1+ (1,0) [0|15] "" Vector__XXX
 SG_ MtGt2IvtLtsAtvDSdVtMx : 12|12@1+ (0.0625,-125) [-125|125.9375] "%" Vector__XXX
 SG_ MtGt2IvtLtsAtvDSdVtM : 24|12@1+ (0.0625,-125) [-125|125.9375] "%" Vector__XXX
 SG_ MtGt2IvtLtsAtvDSdCtMx : 36|12@1+ (0.0625,-125) [-125|125.9375] "%" Vector__XXX
 SG_ MtGt2IvtLtsAtvDSdCtM : 48|12@1+ (0.0625,-125) [-125|125.9375] "%" Vector__XXX

BO_ 2565966590 MG2ILV: 8 Vector__XXX
 SG_ MtrGnrtr2InvrtrSwthdIgntnVltg : 0|16@1+ (0.05,0) [0|3212.75] "V" Vector__XXX
 SG_ MtrGnrtr2InvrtrUnswthdSlVltg : 16|16@1+ (0.05,0) [0|3212.75] "V" Vector__XXX

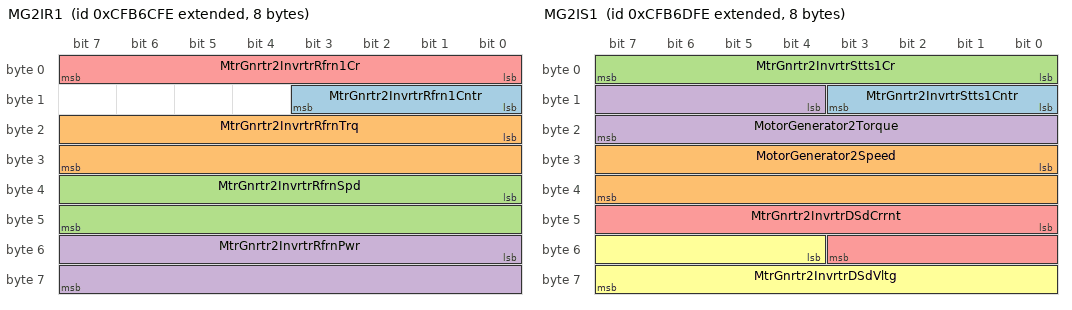
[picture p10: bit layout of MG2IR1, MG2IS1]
BO_ 2365287678 MG2IR1: 8 Vector__XXX
 SG_ MtrGnrtr2InvrtrRfrn1Cntr : 8|4@1+ (1,0) [0|15] "" Vector__XXX
 SG_ MtrGnrtr2InvrtrRfrnTrq : 16|16@1+ (0.5,0) [0|32127.5] "Nm" Vector__XXX
 SG_ MtrGnrtr2InvrtrRfrnSpd : 32|16@1+ (4,0) [0|257020] "rpm" Vector__XXX
 SG_ MtrGnrtr2InvrtrRfrnPwr : 48|16@1+ (0.0625,0) [0|4015.9375] "kW" Vector__XXX
 SG_ MtrGnrtr2InvrtrRfrn1Cr : 0|8@1+ (1,0) [0|250] "count" Vector__XXX

BO_ 2365287934 MG2IS1: 8 Vector__XXX
 SG_ MtrGnrtr2InvrtrStts1Cntr : 8|4@1+ (1,0) [0|15] "" Vector__XXX
 SG_ MotorGenerator2Speed : 24|16@1+ (0.00390625,-125) [-125|125.99609375] "%" Vector__XXX
 SG_ MtrGnrtr2InvrtrStts1Cr : 0|8@1+ (1,0) [0|250] "count" Vector__XXX
 SG_ MotorGenerator2Torque : 12|12@1+ (0.0625,-125) [-125|125.9375] "%" Vector__XXX
 SG_ MtrGnrtr2InvrtrDSdCrrnt : 40|12@1+ (0.0625,-125) [-125|125.9375] "%" Vector__XXX
 SG_ MtrGnrtr2InvrtrDSdVltg : 52|12@1+ (0.0625,-125) [-125|125.9375] "%" Vector__XXX

BO_ 2365288190 MG2IR2: 8 Vector__XXX
 SG_ MtrGnrtr2InvrtrRfrn2Cntr : 8|4@1+ (1,0) [0|15] "" Vector__XXX
 SG_ MtrGnrtr2InvrtrRfrnCrrnt : 32|16@1+ (0.125,0) [0|8031.875] "A" Vector__XXX
 SG_ MtrGnrtr2InvrtrRfrnVltg : 48|16@1+ (0.125,0) [0|8031.875] "V" Vector__XXX
 SG_ MtrGnrtr2InvrtrRfrn2Cr : 0|8@1+ (1,0) [0|250] "count" Vector__XXX

BO_ 2566615038 MG2IT: 8 Vector__XXX
 SG_ MtrGnrtr2InvrtrTmprtr1 : 0|8@1+ (1,-40) [-40|210] "degC" Vector__XXX
 SG_ MtrGnrtr2InvrtrTmprtr2 : 8|8@1+ (1,-40) [-40|210] "degC" Vector__XXX
 SG_ MtrGnrtr2InvrtrTmprtr3 : 16|8@1+ (1,-40) [-40|210] "degC" Vector__XXX
 SG_ MtrGnrtr2InvrtrTmprtr4 : 24|8@1+ (1,-40) [-40|210] "degC" Vector__XXX
 SG_ MtrGnrtr2InvrtrTmprtr5 : 32|8@1+ (1,-40) [-40|210] "degC" Vector__XXX

BO_ 2566615294 MG2IMT: 8 Vector__XXX
 SG_ MotorGenerator2Temperature1 : 0|8@1+ (1,-40) [-40|210] "degC" Vector__XXX
 SG_ MotorGenerator2Temperature2 : 8|8@1+ (1,-40) [-40|210] "degC" Vector__XXX
 SG_ MotorGenerator2Temperature3 : 16|8@1+ (1,-40) [-40|210] "degC" Vector__XXX
 SG_ MotorGenerator2Temperature4 : 24|8@1+ (1,-40) [-40|210] "degC" Vector__XXX

BO_ 2566615550 MG1IMT: 8 Vector__XXX
 SG_ MotorGenerator1Temperature1 : 0|8@1+ (1,-40) [-40|210] "degC" Vector__XXX
 SG_ MotorGenerator1Temperature2 : 8|8@1+ (1,-40) [-40|210] "degC" Vector__XXX
 SG_ MotorGenerator1Temperature3 : 16|8@1+ (1,-40) [-40|210] "degC" Vector__XXX
 SG_ MotorGenerator1Temperature4 : 24|8@1+ (1,-40) [-40|210] "degC" Vector__XXX

BO_ 2566615806 MG1IT: 8 Vector__XXX
 SG_ MtrGnrtr1InvrtrTmprtr1 : 0|8@1+ (1,-40) [-40|210] "degC" Vector__XXX
 SG_ MtrGnrtr1InvrtrTmprtr2 : 8|8@1+ (1,-40) [-40|210] "degC" Vector__XXX
 SG_ MtrGnrtr1InvrtrTmprtr3 : 16|8@1+ (1,-40) [-40|210] "degC" Vector__XXX
 SG_ MtrGnrtr1InvrtrTmprtr4 : 24|8@1+ (1,-40) [-40|210] "degC" Vector__XXX
 SG_ MtrGnrtr1InvrtrTmprtr5 : 32|8@1+ (1,-40) [-40|210] "degC" Vector__XXX

BO_ 2365289470 MG1IR2: 8 Vector__XXX
 SG_ MtrGnrtr1InvrtrRfrn2Cntr : 8|4@1+ (1,0) [0|15] "" Vector__XXX
 SG_ MtrGnrtr1InvrtrRfrnCrrnt : 32|16@1+ (0.125,0) [0|8031.875] "A" Vector__XXX
 SG_ MtrGnrtr1InvrtrRfrnVltg : 48|16@1+ (0.125,0) [0|8031.875] "V" Vector__XXX
 SG_ MtrGnrtr1InvrtrRfrn2Cr : 0|8@1+ (1,0) [0|250] "count" Vector__XXX

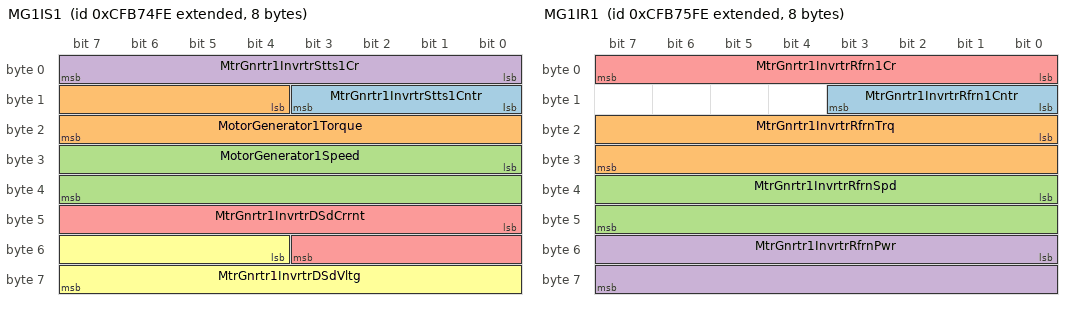
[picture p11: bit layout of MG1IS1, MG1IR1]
BO_ 2365289726 MG1IS1: 8 Vector__XXX
 SG_ MtrGnrtr1InvrtrStts1Cntr : 8|4@1+ (1,0) [0|15] "" Vector__XXX
 SG_ MotorGenerator1Torque : 12|12@1+ (0.0625,-125) [-125|125.9375] "%" Vector__XXX
 SG_ MotorGenerator1Speed : 24|16@1+ (0.00390625,-125) [-125|125.99609375] "%" Vector__XXX
 SG_ MtrGnrtr1InvrtrStts1Cr : 0|8@1+ (1,0) [0|250] "count" Vector__XXX
 SG_ MtrGnrtr1InvrtrDSdCrrnt : 40|12@1+ (0.0625,-125) [-125|125.9375] "%" Vector__XXX
 SG_ MtrGnrtr1InvrtrDSdVltg : 52|12@1+ (0.0625,-125) [-125|125.9375] "%" Vector__XXX

BO_ 2365289982 MG1IR1: 8 Vector__XXX
 SG_ MtrGnrtr1InvrtrRfrn1Cntr : 8|4@1+ (1,0) [0|15] "" Vector__XXX
 SG_ MtrGnrtr1InvrtrRfrnTrq : 16|16@1+ (0.5,0) [0|32127.5] "Nm" Vector__XXX
 SG_ MtrGnrtr1InvrtrRfrnSpd : 32|16@1+ (4,0) [0|257020] "rpm" Vector__XXX
 SG_ MtrGnrtr1InvrtrRfrnPwr : 48|16@1+ (0.0625,0) [0|4015.9375] "kW" Vector__XXX
 SG_ MtrGnrtr1InvrtrRfrn1Cr : 0|8@1+ (1,0) [0|250] "count" Vector__XXX

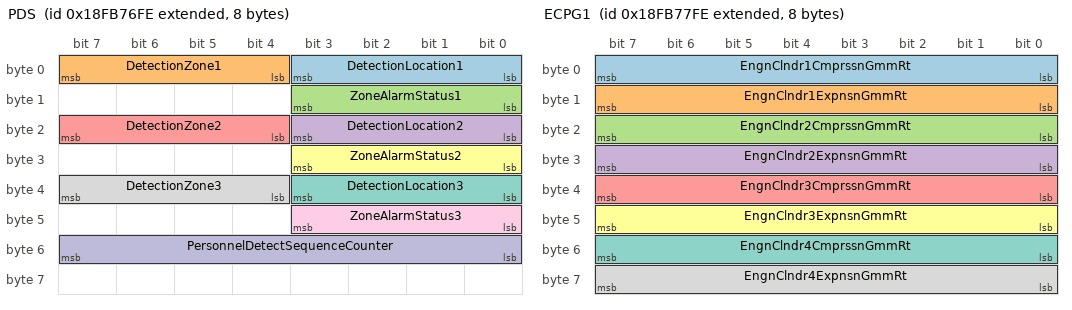
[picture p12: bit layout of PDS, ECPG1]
BO_ 2566616830 PDS: 8 Vector__XXX
 SG_ DetectionLocation1 : 0|4@1+ (1,0) [0|13] "count" Vector__XXX
 SG_ DetectionZone1 : 4|4@1+ (1,0) [0|13] "count" Vector__XXX
 SG_ ZoneAlarmStatus1 : 8|4@1+ (1,0) [0|15] "" Vector__XXX
 SG_ DetectionLocation2 : 16|4@1+ (1,0) [0|13] "count" Vector__XXX
 SG_ DetectionZone2 : 20|4@1+ (1,0) [0|13] "count" Vector__XXX
 SG_ ZoneAlarmStatus2 : 24|4@1+ (1,0) [0|15] "" Vector__XXX
 SG_ DetectionLocation3 : 32|4@1+ (1,0) [0|13] "count" Vector__XXX
 SG_ DetectionZone3 : 36|4@1+ (1,0) [0|13] "count" Vector__XXX
 SG_ ZoneAlarmStatus3 : 40|4@1+ (1,0) [0|15] "" Vector__XXX
 SG_ PersonnelDetectSequenceCounter : 48|8@1+ (1,0) [0|250] "count" Vector__XXX

BO_ 2566617086 ECPG1: 8 Vector__XXX
 SG_ EngnClndr1CmprssnGmmRt : 0|8@1+ (0.004,1) [1|2] "" Vector__XXX
 SG_ EngnClndr1ExpnsnGmmRt : 8|8@1+ (0.004,1) [1|2] "" Vector__XXX
 SG_ EngnClndr2CmprssnGmmRt : 16|8@1+ (0.004,1) [1|2] "" Vector__XXX
 SG_ EngnClndr2ExpnsnGmmRt : 24|8@1+ (0.004,1) [1|2] "" Vector__XXX
 SG_ EngnClndr3CmprssnGmmRt : 32|8@1+ (0.004,1) [1|2] "" Vector__XXX
 SG_ EngnClndr3ExpnsnGmmRt : 40|8@1+ (0.004,1) [1|2] "" Vector__XXX
 SG_ EngnClndr4CmprssnGmmRt : 48|8@1+ (0.004,1) [1|2] "" Vector__XXX
 SG_ EngnClndr4ExpnsnGmmRt : 56|8@1+ (0.004,1) [1|2] "" Vector__XXX

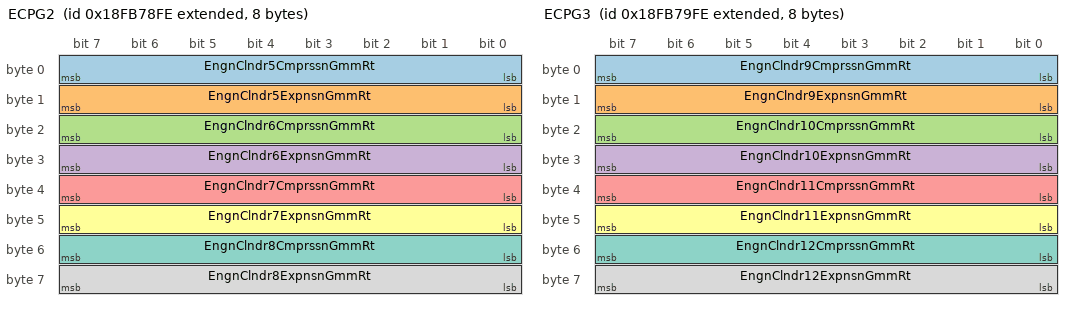
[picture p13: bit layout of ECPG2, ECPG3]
BO_ 2566617342 ECPG2: 8 Vector__XXX
 SG_ EngnClndr5CmprssnGmmRt : 0|8@1+ (0.004,1) [1|2] "" Vector__XXX
 SG_ EngnClndr5ExpnsnGmmRt : 8|8@1+ (0.004,1) [1|2] "" Vector__XXX
 SG_ EngnClndr6CmprssnGmmRt : 16|8@1+ (0.004,1) [1|2] "" Vector__XXX
 SG_ EngnClndr6ExpnsnGmmRt : 24|8@1+ (0.004,1) [1|2] "" Vector__XXX
 SG_ EngnClndr7CmprssnGmmRt : 32|8@1+ (0.004,1) [1|2] "" Vector__XXX
 SG_ EngnClndr7ExpnsnGmmRt : 40|8@1+ (0.004,1) [1|2] "" Vector__XXX
 SG_ EngnClndr8CmprssnGmmRt : 48|8@1+ (0.004,1) [1|2] "" Vector__XXX
 SG_ EngnClndr8ExpnsnGmmRt : 56|8@1+ (0.004,1) [1|2] "" Vector__XXX

BO_ 2566617598 ECPG3: 8 Vector__XXX
 SG_ EngnClndr9CmprssnGmmRt : 0|8@1+ (0.004,1) [1|2] "" Vector__XXX
 SG_ EngnClndr9ExpnsnGmmRt : 8|8@1+ (0.004,1) [1|2] "" Vector__XXX
 SG_ EngnClndr10CmprssnGmmRt : 16|8@1+ (0.004,1) [1|2] "" Vector__XXX
 SG_ EngnClndr10ExpnsnGmmRt : 24|8@1+ (0.004,1) [1|2] "" Vector__XXX
 SG_ EngnClndr11CmprssnGmmRt : 32|8@1+ (0.004,1) [1|2] "" Vector__XXX
 SG_ EngnClndr11ExpnsnGmmRt : 40|8@1+ (0.004,1) [1|2] "" Vector__XXX
 SG_ EngnClndr12CmprssnGmmRt : 48|8@1+ (0.004,1) [1|2] "" Vector__XXX
 SG_ EngnClndr12ExpnsnGmmRt : 56|8@1+ (0.004,1) [1|2] "" Vector__XXX

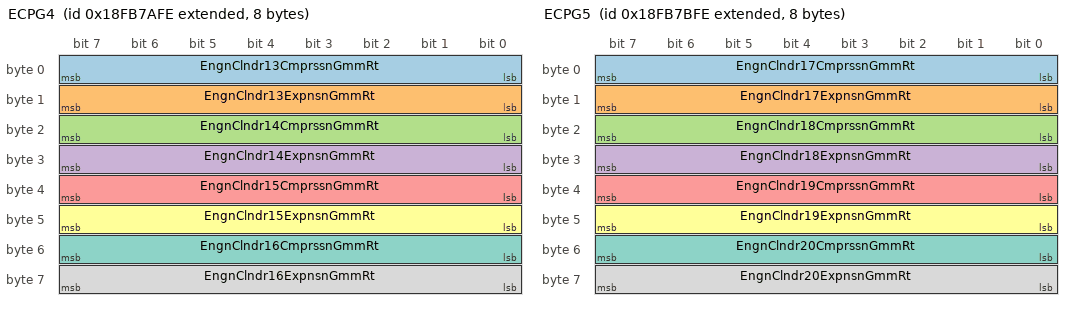
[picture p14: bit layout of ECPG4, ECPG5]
BO_ 2566617854 ECPG4: 8 Vector__XXX
 SG_ EngnClndr13CmprssnGmmRt : 0|8@1+ (0.004,1) [1|2] "" Vector__XXX
 SG_ EngnClndr13ExpnsnGmmRt : 8|8@1+ (0.004,1) [1|2] "" Vector__XXX
 SG_ EngnClndr14CmprssnGmmRt : 16|8@1+ (0.004,1) [1|2] "" Vector__XXX
 SG_ EngnClndr14ExpnsnGmmRt : 24|8@1+ (0.004,1) [1|2] "" Vector__XXX
 SG_ EngnClndr15CmprssnGmmRt : 32|8@1+ (0.004,1) [1|2] "" Vector__XXX
 SG_ EngnClndr15ExpnsnGmmRt : 40|8@1+ (0.004,1) [1|2] "" Vector__XXX
 SG_ EngnClndr16CmprssnGmmRt : 48|8@1+ (0.004,1) [1|2] "" Vector__XXX
 SG_ EngnClndr16ExpnsnGmmRt : 56|8@1+ (0.004,1) [1|2] "" Vector__XXX

BO_ 2566618110 ECPG5: 8 Vector__XXX
 SG_ EngnClndr17CmprssnGmmRt : 0|8@1+ (0.004,1) [1|2] "" Vector__XXX
 SG_ EngnClndr17ExpnsnGmmRt : 8|8@1+ (0.004,1) [1|2] "" Vector__XXX
 SG_ EngnClndr18CmprssnGmmRt : 16|8@1+ (0.004,1) [1|2] "" Vector__XXX
 SG_ EngnClndr18ExpnsnGmmRt : 24|8@1+ (0.004,1) [1|2] "" Vector__XXX
 SG_ EngnClndr19CmprssnGmmRt : 32|8@1+ (0.004,1) [1|2] "" Vector__XXX
 SG_ EngnClndr19ExpnsnGmmRt : 40|8@1+ (0.004,1) [1|2] "" Vector__XXX
 SG_ EngnClndr20CmprssnGmmRt : 48|8@1+ (0.004,1) [1|2] "" Vector__XXX
 SG_ EngnClndr20ExpnsnGmmRt : 56|8@1+ (0.004,1) [1|2] "" Vector__XXX

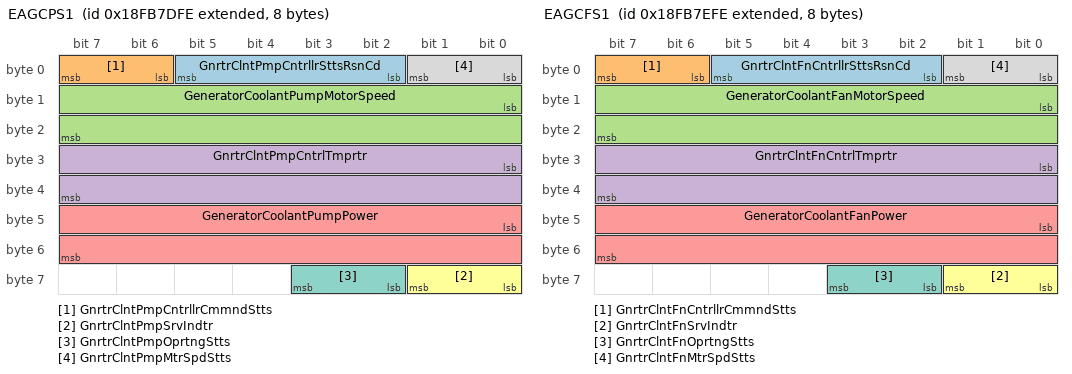
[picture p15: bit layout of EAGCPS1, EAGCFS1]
BO_ 2566618622 EAGCPS1: 8 Vector__XXX
 SG_ GnrtrClntPmpCntrllrSttsRsnCd : 2|4@1+ (1,0) [0|15] "" Vector__XXX
 SG_ GnrtrClntPmpCntrllrCmmndStts : 6|2@1+ (1,0) [0|3] "" Vector__XXX
 SG_ GeneratorCoolantPumpMotorSpeed : 8|16@1+ (0.5,0) [0|32127.5] "rpm" Vector__XXX
 SG_ GnrtrClntPmpCntrlTmprtr : 24|16@1+ (0.03125,-273) [-273|1734.96875] "degC" Vector__XXX
 SG_ GeneratorCoolantPumpPower : 40|16@1+ (0.5,0) [0|32127.5] "W" Vector__XXX
 SG_ GnrtrClntPmpSrvIndtr : 56|2@1+ (1,0) [0|3] "" Vector__XXX
 SG_ GnrtrClntPmpOprtngStts : 58|2@1+ (1,0) [0|3] "" Vector__XXX
 SG_ GnrtrClntPmpMtrSpdStts : 0|2@1+ (1,0) [0|3] "" Vector__XXX

BO_ 2566618878 EAGCFS1: 8 Vector__XXX
 SG_ GnrtrClntFnCntrllrSttsRsnCd : 2|4@1+ (1,0) [0|15] "" Vector__XXX
 SG_ GnrtrClntFnCntrllrCmmndStts : 6|2@1+ (1,0) [0|3] "" Vector__XXX
 SG_ GeneratorCoolantFanMotorSpeed : 8|16@1+ (0.5,0) [0|32127.5] "rpm" Vector__XXX
 SG_ GnrtrClntFnCntrlTmprtr : 24|16@1+ (0.03125,-273) [-273|1734.96875] "degC" Vector__XXX
 SG_ GeneratorCoolantFanPower : 40|16@1+ (0.5,0) [0|32127.5] "W" Vector__XXX
 SG_ GnrtrClntFnSrvIndtr : 56|2@1+ (1,0) [0|3] "" Vector__XXX
 SG_ GnrtrClntFnOprtngStts : 58|2@1+ (1,0) [0|3] "" Vector__XXX
 SG_ GnrtrClntFnMtrSpdStts : 0|2@1+ (1,0) [0|3] "" Vector__XXX

BO_ 2566619134 WSPF: 8 Vector__XXX
 SG_ WllStmltnPmpOlFltrDffrntlPrssr : 0|8@1+ (4,0) [0|1000] "kPa" Vector__XXX
 SG_ WllStmltnPmpOlFltrBpssSwthStts : 24|2@1+ (1,0) [0|3] "" Vector__XXX
 SG_ WllStmltnPmpGrBxOtltOlPrssr : 8|16@1+ (0.1,0) [0|6425.5] "kPa" Vector__XXX

BO_ 2566619390 PTOGC: 22 Vector__XXX
 SG_ MinimumPtoGovernorSetSpeed : 128|16@1+ (0.125,0) [0|8031.875] "rpm" Vector__XXX
 SG_ MaximumPtoGovernorSetSpeed : 144|16@1+ (0.125,0) [0|8031.875] "rpm" Vector__XXX
 SG_ PrprgrmmdPtGvrnrStSpd1 : 0|16@1+ (0.125,0) [0|8031.875] "rpm" Vector__XXX
 SG_ PrprgrmmdPtGvrnrStSpd2 : 16|16@1+ (0.125,0) [0|8031.875] "rpm" Vector__XXX
 SG_ PrprgrmmdPtGvrnrStSpd3 : 32|16@1+ (0.125,0) [0|8031.875] "rpm" Vector__XXX
 SG_ PrprgrmmdPtGvrnrStSpd4 : 48|16@1+ (0.125,0) [0|8031.875] "rpm" Vector__XXX
 SG_ PrprgrmmdPtGvrnrStSpd5 : 64|16@1+ (0.125,0) [0|8031.875] "rpm" Vector__XXX
 SG_ PrprgrmmdPtGvrnrStSpd6 : 80|16@1+ (0.125,0) [0|8031.875] "rpm" Vector__XXX
 SG_ PrprgrmmdPtGvrnrStSpd7 : 96|16@1+ (0.125,0) [0|8031.875] "rpm" Vector__XXX
 SG_ PrprgrmmdPtGvrnrStSpd8 : 112|16@1+ (0.125,0) [0|8031.875] "rpm" Vector__XXX
 SG_ PtGvrnrAlrtrOvrrdMxmmSpd : 160|16@1+ (0.125,0) [0|8031.875] "rpm" Vector__XXX

BO_ 2566619646 OBP2: 8 Vector__XXX
 SG_ OnBrdPrgrmmngInttRqst : 8|2@1+ (1,0) [0|3] "" Vector__XXX
 SG_ OnBrdPrgrmmngInttInht : 10|2@1+ (1,0) [0|3] "" Vector__XXX
 SG_ OnBrdPrgrmmngInttEAddrss : 0|8@1+ (1,0) [0|250] "sourceadr" Vector__XXX

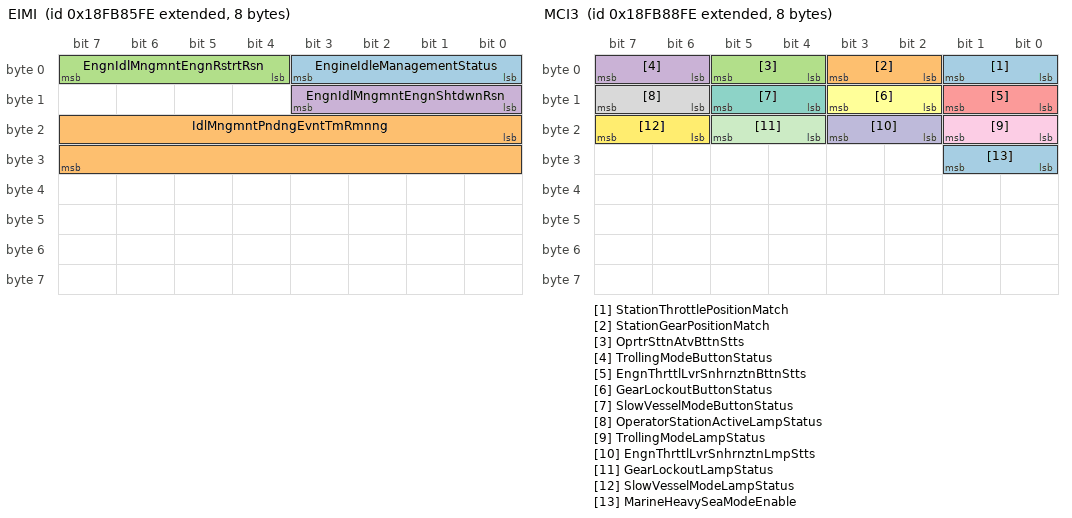
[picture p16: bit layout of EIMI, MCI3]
BO_ 2566620670 EIMI: 8 Vector__XXX
 SG_ EngineIdleManagementStatus : 0|4@1+ (1,0) [0|15] "" Vector__XXX
 SG_ IdlMngmntPndngEvntTmRmnng : 16|16@1+ (1,0) [0|64255] "s" Vector__XXX
 SG_ EngnIdlMngmntEngnRstrtRsn : 4|4@1+ (1,0) [0|15] "" Vector__XXX
 SG_ EngnIdlMngmntEngnShtdwnRsn : 8|4@1+ (1,0) [0|15] "" Vector__XXX

BO_ 2566621438 MCI3: 8 Vector__XXX
 SG_ StationThrottlePositionMatch : 0|2@1+ (1,0) [0|3] "" Vector__XXX
 SG_ StationGearPositionMatch : 2|2@1+ (1,0) [0|3] "" Vector__XXX
 SG_ OprtrSttnAtvBttnStts : 4|2@1+ (1,0) [0|3] "" Vector__XXX
 SG_ TrollingModeButtonStatus : 6|2@1+ (1,0) [0|3] "" Vector__XXX
 SG_ EngnThrttlLvrSnhrnztnBttnStts : 8|2@1+ (1,0) [0|3] "" Vector__XXX
 SG_ GearLockoutButtonStatus : 10|2@1+ (1,0) [0|3] "" Vector__XXX
 SG_ SlowVesselModeButtonStatus : 12|2@1+ (1,0) [0|3] "" Vector__XXX
 SG_ OperatorStationActiveLampStatus : 14|2@1+ (1,0) [0|3] "" Vector__XXX
 SG_ TrollingModeLampStatus : 16|2@1+ (1,0) [0|3] "" Vector__XXX
 SG_ EngnThrttlLvrSnhrnztnLmpStts : 18|2@1+ (1,0) [0|3] "" Vector__XXX
 SG_ GearLockoutLampStatus : 20|2@1+ (1,0) [0|3] "" Vector__XXX
 SG_ SlowVesselModeLampStatus : 22|2@1+ (1,0) [0|3] "" Vector__XXX
 SG_ MarineHeavySeaModeEnable : 24|2@1+ (1,0) [0|3] "" Vector__XXX

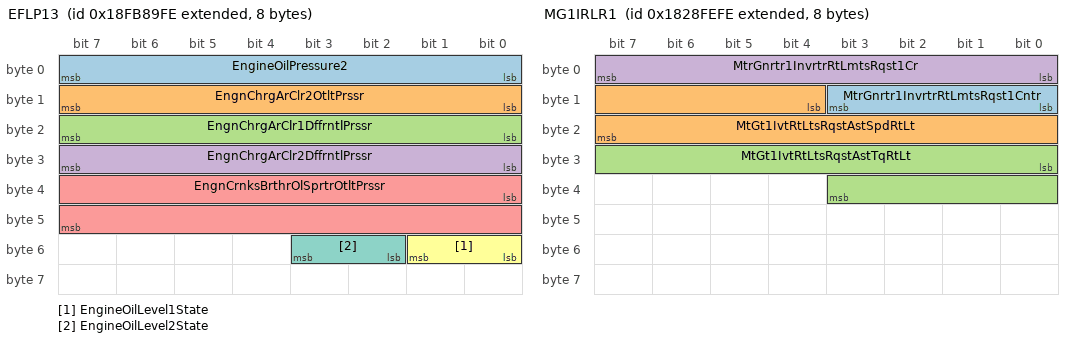
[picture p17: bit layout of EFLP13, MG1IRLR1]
BO_ 2566621694 EFLP13: 8 Vector__XXX
 SG_ EngineOilPressure2 : 0|8@1+ (4,0) [0|1000] "kPa" Vector__XXX
 SG_ EngnChrgArClr2OtltPrssr : 8|8@1+ (2,0) [0|500] "kPa" Vector__XXX
 SG_ EngnChrgArClr1DffrntlPrssr : 16|8@1+ (0.5,0) [0|125] "kPa" Vector__XXX
 SG_ EngnChrgArClr2DffrntlPrssr : 24|8@1+ (0.5,0) [0|125] "kPa" Vector__XXX
 SG_ EngnCrnksBrthrOlSprtrOtltPrssr : 32|16@1+ (0.0078125,-250) [-250|251.9921875] "kPa" Vector__XXX
 SG_ EngineOilLevel1State : 48|2@1+ (1,0) [0|3] "" Vector__XXX
 SG_ EngineOilLevel2State : 50|2@1+ (1,0) [0|3] "" Vector__XXX

BO_ 2365295358 HVESSD11: 8 Vector__XXX
 SG_ HvessActualChargeRate : 32|16@1+ (0.05,0) [0|3212.75] "kW" Vector__XXX
 SG_ HvssBsVltgNgtvTChsssGrndVltg : 0|16@1+ (0.05,0) [0|3212.75] "V" Vector__XXX
 SG_ HvssVltgLvlNgtvTChsssGrndVltg : 16|16@1+ (0.05,0) [0|3212.75] "V" Vector__XXX
 SG_ HvssTtlStrdEnrgSrLvl : 48|8@1+ (0.4,0) [0|100] "%" Vector__XXX
 SG_ HvssPwrMdlEltrnsTmprtr : 56|8@1+ (1,-40) [-40|210] "degC" Vector__XXX

BO_ 2566622206 EMIH: 8 Vector__XXX
 SG_ EconomyModeTotalHoursInactive : 0|32@1+ (0.05,0) [0|210554060.75] "h" Vector__XXX
 SG_ EconomyModeTripHoursInactive : 32|32@1+ (0.05,0) [0|210554060.75] "h" Vector__XXX

BO_ 2566622462 EMEIFSR: 8 Vector__XXX
 SG_ EnmMdEstmtdInstntnsFlSvngsRt : 0|16@1+ (0.05,0) [0|3212.75] "l/h" Vector__XXX
 SG_ EMdEsttdIsttsFSvsRtPt : 16|16@1+ (0.0025,0) [0|160.6375] "%" Vector__XXX

BO_ 2566622718 EMAH: 8 Vector__XXX
 SG_ EconomyModeTotalHoursActive : 0|32@1+ (0.05,0) [0|210554060.75] "h" Vector__XXX
 SG_ EconomyModeTripHoursActive : 32|32@1+ (0.05,0) [0|210554060.75] "h" Vector__XXX

BO_ 2566622974 EMFU: 8 Vector__XXX
 SG_ EconomyModeTotalFuelUsed : 0|32@1+ (0.5,0) [0|2105540607.5] "l" Vector__XXX
 SG_ EconomyModeTripFuelUsed : 32|32@1+ (0.5,0) [0|2105540607.5] "l" Vector__XXX

BO_ 2566623230 EMEFS: 8 Vector__XXX
 SG_ EnmMdTtlEstmtdFlSvd : 0|32@1+ (0.5,0) [0|2105540607.5] "l" Vector__XXX
 SG_ EnmMdTrpEstmtdFlSvd : 32|32@1+ (0.5,0) [0|2105540607.5] "l" Vector__XXX

BO_ 2552823550 MG1IRLR1: 8 Vector__XXX
 SG_ MtrGnrtr1InvrtrRtLmtsRqst1Cntr : 8|4@1+ (1,0) [0|15] "" Vector__XXX
 SG_ MtGt1IvtRtLtsRqstAstSpdRtLt : 12|12@1+ (0.25,0) [0|1003.75] "%/s" Vector__XXX
 SG_ MtGt1IvtRtLtsRqstAstTqRtLt : 24|12@1+ (2,0) [0|8030] "%/s" Vector__XXX
 SG_ MtrGnrtr1InvrtrRtLmtsRqst1Cr : 0|8@1+ (1,0) [0|250] "count" Vector__XXX

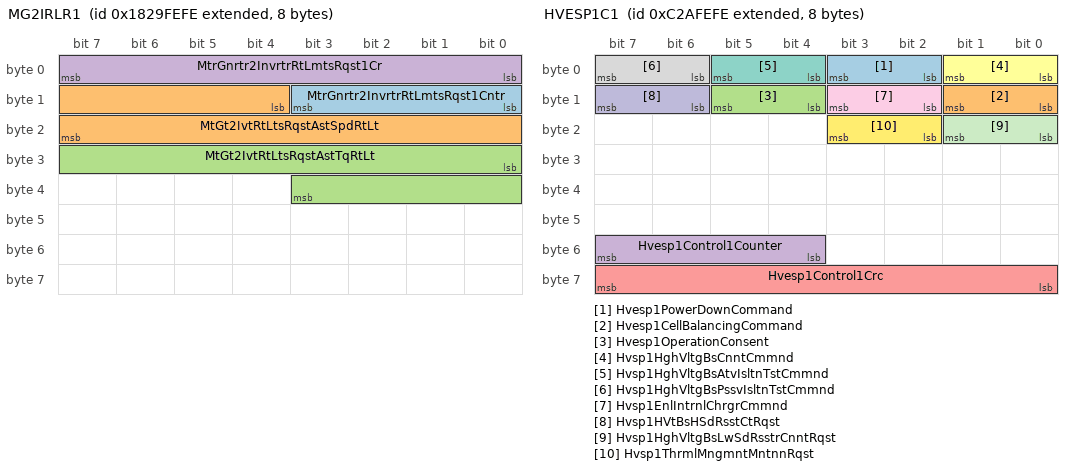
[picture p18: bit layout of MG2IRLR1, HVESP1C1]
BO_ 2552889086 MG2IRLR1: 8 Vector__XXX
 SG_ MtrGnrtr2InvrtrRtLmtsRqst1Cntr : 8|4@1+ (1,0) [0|15] "" Vector__XXX
 SG_ MtGt2IvtRtLtsRqstAstSpdRtLt : 12|12@1+ (0.25,0) [0|1003.75] "%/s" Vector__XXX
 SG_ MtGt2IvtRtLtsRqstAstTqRtLt : 24|12@1+ (2,0) [0|8030] "%/s" Vector__XXX
 SG_ MtrGnrtr2InvrtrRtLmtsRqst1Cr : 0|8@1+ (1,0) [0|250] "count" Vector__XXX

BO_ 2351628030 HVESP1C1: 8 Vector__XXX
 SG_ Hvesp1PowerDownCommand : 2|2@1+ (1,0) [0|3] "" Vector__XXX
 SG_ Hvesp1CellBalancingCommand : 8|2@1+ (1,0) [0|3] "" Vector__XXX
 SG_ Hvesp1OperationConsent : 12|2@1+ (1,0) [0|3] "" Vector__XXX
 SG_ Hvesp1Control1Counter : 52|4@1+ (1,0) [0|15] "" Vector__XXX
 SG_ Hvesp1Control1Crc : 56|8@1+ (1,0) [0|250] "count" Vector__XXX
 SG_ Hvsp1HghVltgBsCnntCmmnd : 0|2@1+ (1,0) [0|3] "" Vector__XXX
 SG_ Hvsp1HghVltgBsAtvIsltnTstCmmnd : 4|2@1+ (1,0) [0|3] "" Vector__XXX
 SG_ Hvsp1HghVltgBsPssvIsltnTstCmmnd : 6|2@1+ (1,0) [0|3] "" Vector__XXX
 SG_ Hvsp1EnlIntrnlChrgrCmmnd : 10|2@1+ (1,0) [0|3] "" Vector__XXX
 SG_ Hvsp1HVtBsHSdRsstCtRqst : 14|2@1+ (1,0) [0|3] "" Vector__XXX
 SG_ Hvsp1HghVltgBsLwSdRsstrCnntRqst : 16|2@1+ (1,0) [0|3] "" Vector__XXX
 SG_ Hvsp1ThrmlMngmntMntnnRqst : 18|2@1+ (1,0) [0|3] "" Vector__XXX

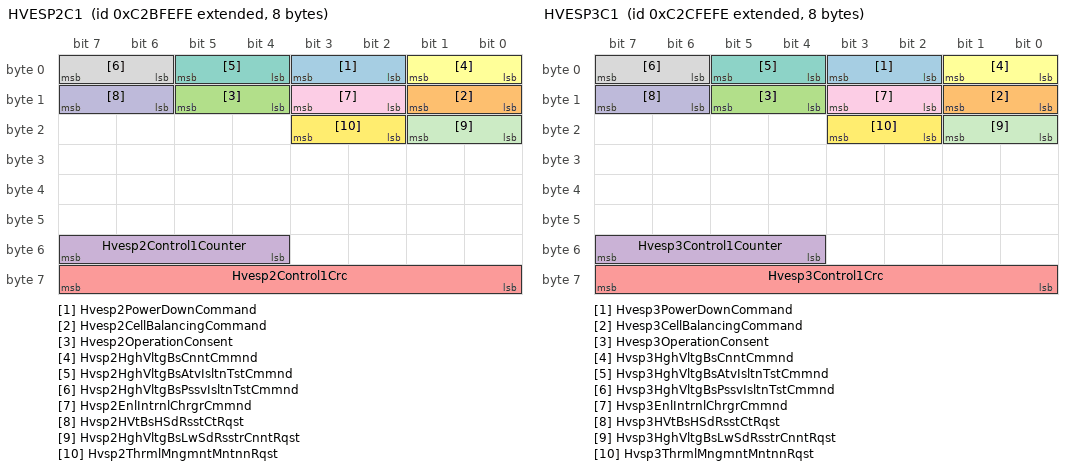
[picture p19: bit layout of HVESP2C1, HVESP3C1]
BO_ 2351693566 HVESP2C1: 8 Vector__XXX
 SG_ Hvesp2PowerDownCommand : 2|2@1+ (1,0) [0|3] "" Vector__XXX
 SG_ Hvesp2CellBalancingCommand : 8|2@1+ (1,0) [0|3] "" Vector__XXX
 SG_ Hvesp2OperationConsent : 12|2@1+ (1,0) [0|3] "" Vector__XXX
 SG_ Hvesp2Control1Counter : 52|4@1+ (1,0) [0|15] "" Vector__XXX
 SG_ Hvesp2Control1Crc : 56|8@1+ (1,0) [0|250] "count" Vector__XXX
 SG_ Hvsp2HghVltgBsCnntCmmnd : 0|2@1+ (1,0) [0|3] "" Vector__XXX
 SG_ Hvsp2HghVltgBsAtvIsltnTstCmmnd : 4|2@1+ (1,0) [0|3] "" Vector__XXX
 SG_ Hvsp2HghVltgBsPssvIsltnTstCmmnd : 6|2@1+ (1,0) [0|3] "" Vector__XXX
 SG_ Hvsp2EnlIntrnlChrgrCmmnd : 10|2@1+ (1,0) [0|3] "" Vector__XXX
 SG_ Hvsp2HVtBsHSdRsstCtRqst : 14|2@1+ (1,0) [0|3] "" Vector__XXX
 SG_ Hvsp2HghVltgBsLwSdRsstrCnntRqst : 16|2@1+ (1,0) [0|3] "" Vector__XXX
 SG_ Hvsp2ThrmlMngmntMntnnRqst : 18|2@1+ (1,0) [0|3] "" Vector__XXX

BO_ 2351759102 HVESP3C1: 8 Vector__XXX
 SG_ Hvesp3PowerDownCommand : 2|2@1+ (1,0) [0|3] "" Vector__XXX
 SG_ Hvesp3CellBalancingCommand : 8|2@1+ (1,0) [0|3] "" Vector__XXX
 SG_ Hvesp3OperationConsent : 12|2@1+ (1,0) [0|3] "" Vector__XXX
 SG_ Hvesp3Control1Counter : 52|4@1+ (1,0) [0|15] "" Vector__XXX
 SG_ Hvesp3Control1Crc : 56|8@1+ (1,0) [0|250] "count" Vector__XXX
 SG_ Hvsp3HghVltgBsCnntCmmnd : 0|2@1+ (1,0) [0|3] "" Vector__XXX
 SG_ Hvsp3HghVltgBsAtvIsltnTstCmmnd : 4|2@1+ (1,0) [0|3] "" Vector__XXX
 SG_ Hvsp3HghVltgBsPssvIsltnTstCmmnd : 6|2@1+ (1,0) [0|3] "" Vector__XXX
 SG_ Hvsp3EnlIntrnlChrgrCmmnd : 10|2@1+ (1,0) [0|3] "" Vector__XXX
 SG_ Hvsp3HVtBsHSdRsstCtRqst : 14|2@1+ (1,0) [0|3] "" Vector__XXX
 SG_ Hvsp3HghVltgBsLwSdRsstrCnntRqst : 16|2@1+ (1,0) [0|3] "" Vector__XXX
 SG_ Hvsp3ThrmlMngmntMntnnRqst : 18|2@1+ (1,0) [0|3] "" Vector__XXX

CM_ BO_ 2364626430 "Engine Cylinder 17 Combustion Pressures";
CM_ SG_ 2364626430 EngineCylinder17Timing1Pressure "Engine Cylinder 17 Timing 1 Pressure: In-cylinder pressure for Cylinder #17 at user-defined timing location #1 as per SPN 9845.  Will report FB00h (64256) when engine is not running.";
CM_ SG_ 2364626430 EngineCylinder17Timing2Pressure "Engine Cylinder 17 Timing 2 Pressure: In-cylinder pressure for Cylinder #17 at user-defined timing location #2 as per SPN 9846.  Will report FB00h (64256) when engine is not running.";
CM_ SG_ 2364626430 EngineCylinder17Timing3Pressure "Engine Cylinder 17 Timing 3 Pressure: In-cylinder pressure for Cylinder #17 at user-defined timing location #3 as per SPN 9847.  Will report FB00h (64256) when engine is not running.";
CM_ SG_ 2364626430 EngineCylinder17Timing4Pressure "Engine Cylinder 17 Timing 4 Pressure: In-cylinder pressure for Cylinder #17 at user-defined timing location #4 as per SPN 9848.  Will report FB00h (64256) when engine is not running.";
CM_ BO_ 2364626686 "Engine Cylinder 18 Combustion Pressures";
CM_ SG_ 2364626686 EngineCylinder18Timing1Pressure "Engine Cylinder 18 Timing 1 Pressure: In-cylinder pressure for Cylinder #18 at user-defined timing location #1 as per SPN 9845.  Will report FB00h (64256) when engine is not running.";
CM_ SG_ 2364626686 EngineCylinder18Timing2Pressure "Engine Cylinder 18 Timing 2 Pressure: In-cylinder pressure for Cylinder #18 at user-defined timing location #2 as per SPN 9846.  Will report FB00h (64256) when engine is not running.";
CM_ SG_ 2364626686 EngineCylinder18Timing3Pressure "Engine Cylinder 18 Timing 3 Pressure: In-cylinder pressure for Cylinder #18 at user-defined timing location #3 as per SPN 9847.  Will report FB00h (64256) when engine is not running.";
CM_ SG_ 2364626686 EngineCylinder18Timing4Pressure "Engine Cylinder 18 Timing 4 Pressure: In-cylinder pressure for Cylinder #18 at user-defined timing location #4 as per SPN 9848.  Will report FB00h (64256) when engine is not running.";
CM_ BO_ 2364626942 "Engine Cylinder 19 Combustion Pressures";
CM_ SG_ 2364626942 EngineCylinder19Timing1Pressure "Engine Cylinder 19 Timing 1 Pressure: In-cylinder pressure for Cylinder #19 at user-defined timing location #1 as per SPN 9845.  Will report FB00h (64256) when engine is not running.";
CM_ SG_ 2364626942 EngineCylinder19Timing2Pressure "Engine Cylinder 19 Timing 2 Pressure: In-cylinder pressure for Cylinder #19 at user-defined timing location #2 as per SPN 9846.  Will report FB00h (64256) when engine is not running.";
CM_ SG_ 2364626942 EngineCylinder19Timing3Pressure "Engine Cylinder 19 Timing 3 Pressure: In-cylinder pressure for Cylinder #19 at user-defined timing location #3 as per SPN 9847.  Will report FB00h (64256) when engine is not running.";
CM_ SG_ 2364626942 EngineCylinder19Timing4Pressure "Engine Cylinder 19 Timing 4 Pressure: In-cylinder pressure for Cylinder #19 at user-defined timing location #4 as per SPN 9848.  Will report FB00h (64256) when engine is not running.";
CM_ BO_ 2364627198 "Engine Cylinder 20 Combustion Pressures";
CM_ SG_ 2364627198 EngineCylinder20Timing1Pressure "Engine Cylinder 20 Timing 1 Pressure: In-cylinder pressure for Cylinder #20 at user-defined timing location #1 as per SPN 9845.  Will report FB00h (64256) when engine is not running.";
CM_ SG_ 2364627198 EngineCylinder20Timing2Pressure "Engine Cylinder 20 Timing 2 Pressure: In-cylinder pressure for Cylinder #20 at user-defined timing location #2 as per SPN 9846.  Will report FB00h (64256) when engine is not running.";
CM_ SG_ 2364627198 EngineCylinder20Timing3Pressure "Engine Cylinder 20 Timing 3 Pressure: In-cylinder pressure for Cylinder #20 at user-defined timing location #3 as per SPN 9847.  Will report FB00h (64256) when engine is not running.";
CM_ SG_ 2364627198 EngineCylinder20Timing4Pressure "Engine Cylinder 20 Timing 4 Pressure: In-cylinder pressure for Cylinder #20 at user-defined timing location #4 as per SPN 9848.  Will report FB00h (64256) when engine is not running.";
CM_ BO_ 2364627454 "Engine Cylinder 1 Combustion Timing";
CM_ SG_ 2364627454 EngnClndr1InstntnsCmstnTmngPnt1 "Engine Cylinder 1 Instantaneous Combustion Timing, Point 1: Engine Cylinder 1 Instantaneous Combustion Timing, Point 1 is defined as the crank angle for which x% of the fuel mass has been burned by Cylinder 1 in the present engine cycle.  x% is defin...";
CM_ SG_ 2364627454 EngnClndr1InstntnsCmstnTmngPnt2 "Engine Cylinder 1 Instantaneous Combustion Timing, Point 2: Engine Cylinder 1 Instantaneous Combustion Timing, Point 2 is defined as the crank angle for which y% of the fuel mass has been burned by Cylinder 1 in the present engine cycle.  y% is defin...";
CM_ SG_ 2364627454 ECd1IsttsSttOCstT "Engine Cylinder 1 Instantaneous Start of Combustion Timing: Instantaneous Start of Combustion timing is defined as the crank angle for which less than 5% of the fuel mass has been burned in the present engine cycle.  The data will report FB00h (64256...";
CM_ SG_ 2364627454 ECd1IsttsCtOCstT "Engine Cylinder 1 Instantaneous Center of Combustion Timing: Instantaneous Center of Combustion timing is defined as the crank angle for which 50% of the fuel mass has been burned in the present engine cycle.  The data will report FB00h (64256) when ...";
CM_ BO_ 2364627710 "Engine Cylinder 2 Combustion Timing";
CM_ SG_ 2364627710 EngnClndr2InstntnsCmstnTmngPnt1 "Engine Cylinder 2 Instantaneous Combustion Timing, Point 1: Engine Cylinder 2 Instantaneous Combustion Timing, Point 1 is defined as the crank angle for which x% of the fuel mass has been burned by Cylinder 2 in the present engine cycle.  x% is defin...";
CM_ SG_ 2364627710 EngnClndr2InstntnsCmstnTmngPnt2 "Engine Cylinder 2 Instantaneous Combustion Timing, Point 2: Engine Cylinder 2 Instantaneous Combustion Timing, Point 2 is defined as the crank angle for which y% of the fuel mass has been burned by Cylinder 2 in the present engine cycle.  y% is defin...";
CM_ SG_ 2364627710 ECd2IsttsSttOCstT "Engine Cylinder 2 Instantaneous Start of Combustion Timing: Instantaneous Start of Combustion timing is defined as the crank angle for which less than 5% of the fuel mass has been burned in the present engine cycle.  The data will report FB00h (64256...";
CM_ SG_ 2364627710 ECd2IsttsCtOCstT "Engine Cylinder 2 Instantaneous Center of Combustion Timing: Instantaneous Center of Combustion timing is defined as the crank angle for which 50% of the fuel mass has been burned in the present engine cycle.  The data will report FB00h (64256) when ...";
CM_ BO_ 2364627966 "Engine Cylinder 3 Combustion Timing";
CM_ SG_ 2364627966 EngnClndr3InstntnsCmstnTmngPnt1 "Engine Cylinder 3 Instantaneous Combustion Timing, Point 1: Engine Cylinder 3 Instantaneous Combustion Timing, Point 1 is defined as the crank angle for which x% of the fuel mass has been burned by Cylinder 3 in the present engine cycle.  x% is defin...";
CM_ SG_ 2364627966 EngnClndr3InstntnsCmstnTmngPnt2 "Engine Cylinder 3 Instantaneous Combustion Timing, Point 2: Engine Cylinder 3 Instantaneous Combustion Timing, Point 2 is defined as the crank angle for which y% of the fuel mass has been burned by Cylinder 3 in the present engine cycle.  y% is defin...";
CM_ SG_ 2364627966 ECd3IsttsSttOCstT "Engine Cylinder 3 Instantaneous Start of Combustion Timing: Instantaneous Start of Combustion timing is defined as the crank angle for which less than 5% of the fuel mass has been burned in the present engine cycle.  The data will report FB00h (64256...";
CM_ SG_ 2364627966 ECd3IsttsCtOCstT "Engine Cylinder 3 Instantaneous Center of Combustion Timing: Instantaneous Center of Combustion timing is defined as the crank angle for which 50% of the fuel mass has been burned in the present engine cycle.  The data will report FB00h (64256) when ...";
CM_ BO_ 2364628222 "Engine Cylinder 4 Combustion Timing";
CM_ SG_ 2364628222 EngnClndr4InstntnsCmstnTmngPnt1 "Engine Cylinder 4 Instantaneous Combustion Timing, Point 1: Engine Cylinder 4 Instantaneous Combustion Timing, Point 1 is defined as the crank angle for which x% of the fuel mass has been burned by Cylinder 4 in the present engine cycle.  x% is defin...";
CM_ SG_ 2364628222 EngnClndr4InstntnsCmstnTmngPnt2 "Engine Cylinder 4 Instantaneous Combustion Timing, Point 2: Engine Cylinder 4 Instantaneous Combustion Timing, Point 2 is defined as the crank angle for which y% of the fuel mass has been burned by Cylinder 4 in the present engine cycle.  y% is defin...";
CM_ SG_ 2364628222 ECd4IsttsSttOCstT "Engine Cylinder 4 Instantaneous Start of Combustion Timing: Instantaneous Start of Combustion timing is defined as the crank angle for which less than 5% of the fuel mass has been burned in the present engine cycle.  The data will report FB00h (64256...";
CM_ SG_ 2364628222 ECd4IsttsCtOCstT "Engine Cylinder 4 Instantaneous Center of Combustion Timing: Instantaneous Center of Combustion timing is defined as the crank angle for which 50% of the fuel mass has been burned in the present engine cycle.  The data will report FB00h (64256) when ...";
CM_ BO_ 2364628478 "Engine Cylinder 5 Combustion Timing";
CM_ SG_ 2364628478 EngnClndr5InstntnsCmstnTmngPnt1 "Engine Cylinder 5 Instantaneous Combustion Timing, Point 1: Engine Cylinder 5 Instantaneous Combustion Timing, Point 1 is defined as the crank angle for which x% of the fuel mass has been burned by Cylinder 5 in the present engine cycle.  x% is defin...";
CM_ SG_ 2364628478 EngnClndr5InstntnsCmstnTmngPnt2 "Engine Cylinder 5 Instantaneous Combustion Timing, Point 2: Engine Cylinder 5 Instantaneous Combustion Timing, Point 2 is defined as the crank angle for which y% of the fuel mass has been burned by Cylinder 5 in the present engine cycle.  y% is defin...";
CM_ SG_ 2364628478 ECd5IsttsSttOCstT "Engine Cylinder 5 Instantaneous Start of Combustion Timing: Instantaneous Start of Combustion timing is defined as the crank angle for which less than 5% of the fuel mass has been burned in the present engine cycle.  The data will report FB00h (64256...";
CM_ SG_ 2364628478 ECd5IsttsCtOCstT "Engine Cylinder 5 Instantaneous Center of Combustion Timing: Instantaneous Center of Combustion timing is defined as the crank angle for which 50% of the fuel mass has been burned in the present engine cycle.  The data will report FB00h (64256) when ...";
CM_ BO_ 2364628734 "Engine Cylinder 6 Combustion Timing";
CM_ SG_ 2364628734 EngnClndr6InstntnsCmstnTmngPnt1 "Engine Cylinder 6 Instantaneous Combustion Timing, Point 1: Engine Cylinder 6 Instantaneous Combustion Timing, Point 1 is defined as the crank angle for which x% of the fuel mass has been burned by Cylinder 6 in the present engine cycle.  x% is defin...";
CM_ SG_ 2364628734 EngnClndr6InstntnsCmstnTmngPnt2 "Engine Cylinder 6 Instantaneous Combustion Timing, Point 2: Engine Cylinder 6 Instantaneous Combustion Timing, Point 2 is defined as the crank angle for which y% of the fuel mass has been burned by Cylinder 6 in the present engine cycle.  y% is defin...";
CM_ SG_ 2364628734 ECd6IsttsSttOCstT "Engine Cylinder 6 Instantaneous Start of Combustion Timing: Instantaneous Start of Combustion timing is defined as the crank angle for which less than 5% of the fuel mass has been burned in the present engine cycle.  The data will report FB00h (64256...";
CM_ SG_ 2364628734 ECd6IsttsCtOCstT "Engine Cylinder 6 Instantaneous Center of Combustion Timing: Instantaneous Center of Combustion timing is defined as the crank angle for which 50% of the fuel mass has been burned in the present engine cycle.  The data will report FB00h (64256) when ...";
CM_ BO_ 2364628990 "Engine Cylinder 7 Combustion Timing";
CM_ SG_ 2364628990 EngnClndr7InstntnsCmstnTmngPnt1 "Engine Cylinder 7 Instantaneous Combustion Timing, Point 1: Engine Cylinder 7 Instantaneous Combustion Timing, Point 1 is defined as the crank angle for which x% of the fuel mass has been burned by Cylinder 7 in the present engine cycle.  x% is defin...";
CM_ SG_ 2364628990 EngnClndr7InstntnsCmstnTmngPnt2 "Engine Cylinder 7 Instantaneous Combustion Timing, Point 2: Engine Cylinder 7 Instantaneous Combustion Timing, Point 2 is defined as the crank angle for which y% of the fuel mass has been burned by Cylinder 7 in the present engine cycle.  y% is defin...";
CM_ SG_ 2364628990 ECd7IsttsSttOCstT "Engine Cylinder 7 Instantaneous Start of Combustion Timing: Instantaneous Start of Combustion timing is defined as the crank angle for which less than 5% of the fuel mass has been burned in the present engine cycle.  The data will report FB00h (64256...";
CM_ SG_ 2364628990 ECd7IsttsCtOCstT "Engine Cylinder 7 Instantaneous Center of Combustion Timing: Instantaneous Center of Combustion timing is defined as the crank angle for which 50% of the fuel mass has been burned in the present engine cycle.  The data will report FB00h (64256) when ...";
CM_ BO_ 2364629246 "Engine Cylinder 8 Combustion Timing";
CM_ SG_ 2364629246 EngnClndr8InstntnsCmstnTmngPnt1 "Engine Cylinder 8 Instantaneous Combustion Timing, Point 1: Engine Cylinder 8 Instantaneous Combustion Timing, Point 1 is defined as the crank angle for which x% of the fuel mass has been burned by Cylinder 8 in the present engine cycle.  x% is defin...";
CM_ SG_ 2364629246 EngnClndr8InstntnsCmstnTmngPnt2 "Engine Cylinder 8 Instantaneous Combustion Timing, Point 2: Engine Cylinder 8 Instantaneous Combustion Timing, Point 2 is defined as the crank angle for which y% of the fuel mass has been burned by Cylinder 8 in the present engine cycle.  y% is defin...";
CM_ SG_ 2364629246 ECd8IsttsSttOCstT "Engine Cylinder 8 Instantaneous Start of Combustion Timing: Instantaneous Start of Combustion timing is defined as the crank angle for which less than 5% of the fuel mass has been burned in the present engine cycle.  The data will report FB00h (64256...";
CM_ SG_ 2364629246 ECd8IsttsCtOCstT "Engine Cylinder 8 Instantaneous Center of Combustion Timing: Instantaneous Center of Combustion timing is defined as the crank angle for which 50% of the fuel mass has been burned in the present engine cycle.  The data will report FB00h (64256) when ...";
CM_ BO_ 2364629502 "Engine Cylinder 9 Combustion Timing";
CM_ SG_ 2364629502 EngnClndr9InstntnsCmstnTmngPnt1 "Engine Cylinder 9 Instantaneous Combustion Timing, Point 1: Engine Cylinder 9 Instantaneous Combustion Timing, Point 1 is defined as the crank angle for which x% of the fuel mass has been burned by Cylinder 9 in the present engine cycle.  x% is defin...";
CM_ SG_ 2364629502 EngnClndr9InstntnsCmstnTmngPnt2 "Engine Cylinder 9 Instantaneous Combustion Timing, Point 2: Engine Cylinder 9 Instantaneous Combustion Timing, Point 2 is defined as the crank angle for which y% of the fuel mass has been burned by Cylinder 9 in the present engine cycle.  y% is defin...";
CM_ SG_ 2364629502 ECd9IsttsSttOCstT "Engine Cylinder 9 Instantaneous Start of Combustion Timing: Instantaneous Start of Combustion timing is defined as the crank angle for which less than 5% of the fuel mass has been burned in the present engine cycle.  The data will report FB00h (64256...";
CM_ SG_ 2364629502 ECd9IsttsCtOCstT "Engine Cylinder 9 Instantaneous Center of Combustion Timing: Instantaneous Center of Combustion timing is defined as the crank angle for which 50% of the fuel mass has been burned in the present engine cycle.  The data will report FB00h (64256) when ...";
CM_ BO_ 2364629758 "Engine Cylinder 10 Combustion Timing";
CM_ SG_ 2364629758 ECd10IsttsCstTPt1 "Engine Cylinder 10 Instantaneous Combustion Timing, Point 1: Engine Cylinder 10 Instantaneous Combustion Timing, Point 1 is defined as the crank angle for which x% of the fuel mass has been burned by Cylinder 10 in the present engine cycle.  x% is de...";
CM_ SG_ 2364629758 ECd10IsttsCstTPt2 "Engine Cylinder 10 Instantaneous Combustion Timing, Point 2: Engine Cylinder 10 Instantaneous Combustion Timing, Point 2 is defined as the crank angle for which y% of the fuel mass has been burned by Cylinder 10 in the present engine cycle.  y% is de...";
CM_ SG_ 2364629758 ECd10IsttsSttOCstT "Engine Cylinder 10 Instantaneous Start of Combustion Timing: Instantaneous Start of Combustion timing is defined as the crank angle for which less than 5% of the fuel mass has been burned in the present engine cycle.  The data will report FB00h (6425...";
CM_ SG_ 2364629758 ECd10IsttsCtOCstT "Engine Cylinder 10 Instantaneous Center of Combustion Timing: Instantaneous Center of Combustion timing is defined as the crank angle for which 50% of the fuel mass has been burned in the present engine cycle.  The data will report FB00h (64256) when...";
CM_ BO_ 2364630014 "Engine Cylinder 11 Combustion Timing";
CM_ SG_ 2364630014 ECd11IsttsCstTPt1 "Engine Cylinder 11 Instantaneous Combustion Timing, Point 1: Engine Cylinder 11 Instantaneous Combustion Timing, Point 1 is defined as the crank angle for which x% of the fuel mass has been burned by Cylinder 11 in the present engine cycle.  x% is de...";
CM_ SG_ 2364630014 ECd11IsttsCstTPt2 "Engine Cylinder 11 Instantaneous Combustion Timing, Point 2: Engine Cylinder 11 Instantaneous Combustion Timing, Point 2 is defined as the crank angle for which y% of the fuel mass has been burned by Cylinder 11 in the present engine cycle.  y% is de...";
CM_ SG_ 2364630014 ECd11IsttsSttOCstT "Engine Cylinder 11 Instantaneous Start of Combustion Timing: Instantaneous Start of Combustion timing is defined as the crank angle for which less than 5% of the fuel mass has been burned in the present engine cycle.  The data will report FB00h (6425...";
CM_ SG_ 2364630014 ECd11IsttsCtOCstT "Engine Cylinder 11 Instantaneous Center of Combustion Timing: Instantaneous Center of Combustion timing is defined as the crank angle for which 50% of the fuel mass has been burned in the present engine cycle.  The data will report FB00h (64256) when...";
CM_ BO_ 2364630270 "Engine Cylinder 12 Combustion Timing";
CM_ SG_ 2364630270 ECd12IsttsCstTPt1 "Engine Cylinder 12 Instantaneous Combustion Timing, Point 1: Engine Cylinder 12 Instantaneous Combustion Timing, Point 1 is defined as the crank angle for which x% of the fuel mass has been burned by Cylinder 12 in the present engine cycle.  x% is de...";
CM_ SG_ 2364630270 ECd12IsttsCstTPt2 "Engine Cylinder 12 Instantaneous Combustion Timing, Point 2: Engine Cylinder 12 Instantaneous Combustion Timing, Point 2 is defined as the crank angle for which y% of the fuel mass has been burned by Cylinder 12 in the present engine cycle.  y% is de...";
CM_ SG_ 2364630270 ECd12IsttsSttOCstT "Engine Cylinder 12 Instantaneous Start of Combustion Timing: Instantaneous Start of Combustion timing is defined as the crank angle for which less than 5% of the fuel mass has been burned in the present engine cycle.  The data will report FB00h (6425...";
CM_ SG_ 2364630270 ECd12IsttsCtOCstT "Engine Cylinder 12 Instantaneous Center of Combustion Timing: Instantaneous Center of Combustion timing is defined as the crank angle for which 50% of the fuel mass has been burned in the present engine cycle.  The data will report FB00h (64256) when...";
CM_ BO_ 2364630526 "Engine Cylinder 13 Combustion Timing";
CM_ SG_ 2364630526 ECd13IsttsCstTPt1 "Engine Cylinder 13 Instantaneous Combustion Timing, Point 1: Engine Cylinder 13 Instantaneous Combustion Timing, Point 1 is defined as the crank angle for which x% of the fuel mass has been burned by Cylinder 13 in the present engine cycle.  x% is de...";
CM_ SG_ 2364630526 ECd13IsttsCstTPt2 "Engine Cylinder 13 Instantaneous Combustion Timing, Point 2: Engine Cylinder 13 Instantaneous Combustion Timing, Point 2 is defined as the crank angle for which y% of the fuel mass has been burned by Cylinder 13 in the present engine cycle.  y% is de...";
CM_ SG_ 2364630526 ECd13IsttsSttOCstT "Engine Cylinder 13 Instantaneous Start of Combustion Timing: Instantaneous Start of Combustion timing is defined as the crank angle for which less than 5% of the fuel mass has been burned in the present engine cycle.  The data will report FB00h (6425...";
CM_ SG_ 2364630526 ECd13IsttsCtOCstT "Engine Cylinder 13 Instantaneous Center of Combustion Timing: Instantaneous Center of Combustion timing is defined as the crank angle for which 50% of the fuel mass has been burned in the present engine cycle.  The data will report FB00h (64256) when...";
CM_ BO_ 2364630782 "Engine Cylinder 14 Combustion Timing";
CM_ SG_ 2364630782 ECd14IsttsCstTPt1 "Engine Cylinder 14 Instantaneous Combustion Timing, Point 1: Engine Cylinder 14 Instantaneous Combustion Timing, Point 1 is defined as the crank angle for which x% of the fuel mass has been burned by Cylinder 14 in the present engine cycle.  x% is de...";
CM_ SG_ 2364630782 ECd14IsttsCstTPt2 "Engine Cylinder 14 Instantaneous Combustion Timing, Point 2: Engine Cylinder 14 Instantaneous Combustion Timing, Point 2 is defined as the crank angle for which y% of the fuel mass has been burned by Cylinder 14 in the present engine cycle.  y% is de...";
CM_ SG_ 2364630782 ECd14IsttsSttOCstT "Engine Cylinder 14 Instantaneous Start of Combustion Timing: Instantaneous Start of Combustion timing is defined as the crank angle for which less than 5% of the fuel mass has been burned in the present engine cycle.  The data will report FB00h (6425...";
CM_ SG_ 2364630782 ECd14IsttsCtOCstT "Engine Cylinder 14 Instantaneous Center of Combustion Timing: Instantaneous Center of Combustion timing is defined as the crank angle for which 50% of the fuel mass has been burned in the present engine cycle.  The data will report FB00h (64256) when...";
CM_ BO_ 2364631038 "Engine Cylinder 15 Combustion Timing";
CM_ SG_ 2364631038 ECd15IsttsCstTPt1 "Engine Cylinder 15 Instantaneous Combustion Timing, Point 1: Engine Cylinder 15 Instantaneous Combustion Timing, Point 1 is defined as the crank angle for which x% of the fuel mass has been burned by Cylinder 15 in the present engine cycle.  x% is de...";
CM_ SG_ 2364631038 ECd15IsttsCstTPt2 "Engine Cylinder 15 Instantaneous Combustion Timing, Point 2: Engine Cylinder 15 Instantaneous Combustion Timing, Point 2 is defined as the crank angle for which y% of the fuel mass has been burned by Cylinder 15 in the present engine cycle.  y% is de...";
CM_ SG_ 2364631038 ECd15IsttsSttOCstT "Engine Cylinder 15 Instantaneous Start of Combustion Timing: Instantaneous Start of Combustion timing is defined as the crank angle for which less than 5% of the fuel mass has been burned in the present engine cycle.  The data will report FB00h (6425...";
CM_ SG_ 2364631038 ECd15IsttsCtOCstT "Engine Cylinder 15 Instantaneous Center of Combustion Timing: Instantaneous Center of Combustion timing is defined as the crank angle for which 50% of the fuel mass has been burned in the present engine cycle.  The data will report FB00h (64256) when...";
CM_ BO_ 2364631294 "Engine Cylinder 16 Combustion Timing";
CM_ SG_ 2364631294 ECd16IsttsCstTPt1 "Engine Cylinder 16 Instantaneous Combustion Timing, Point 1: Engine Cylinder 16 Instantaneous Combustion Timing, Point 1 is defined as the crank angle for which x% of the fuel mass has been burned by Cylinder 16 in the present engine cycle.  x% is de...";
CM_ SG_ 2364631294 ECd16IsttsCstTPt2 "Engine Cylinder 16 Instantaneous Combustion Timing, Point 2: Engine Cylinder 16 Instantaneous Combustion Timing, Point 2 is defined as the crank angle for which y% of the fuel mass has been burned by Cylinder 16 in the present engine cycle.  y% is de...";
CM_ SG_ 2364631294 ECd16IsttsSttOCstT "Engine Cylinder 16 Instantaneous Start of Combustion Timing: Instantaneous Start of Combustion timing is defined as the crank angle for which less than 5% of the fuel mass has been burned in the present engine cycle.  The data will report FB00h (6425...";
CM_ SG_ 2364631294 ECd16IsttsCtOCstT "Engine Cylinder 16 Instantaneous Center of Combustion Timing: Instantaneous Center of Combustion timing is defined as the crank angle for which 50% of the fuel mass has been burned in the present engine cycle.  The data will report FB00h (64256) when...";
CM_ BO_ 2364631550 "Engine Cylinder 17 Combustion Timing";
CM_ SG_ 2364631550 ECd17IsttsCstTPt1 "Engine Cylinder 17 Instantaneous Combustion Timing, Point 1: Engine Cylinder 17 Instantaneous Combustion Timing, Point 1 is defined as the crank angle for which x% of the fuel mass has been burned by Cylinder 17 in the present engine cycle.  x% is de...";
CM_ SG_ 2364631550 ECd17IsttsCstTPt2 "Engine Cylinder 17 Instantaneous Combustion Timing, Point 2: Engine Cylinder 17 Instantaneous Combustion Timing, Point 2 is defined as the crank angle for which y% of the fuel mass has been burned by Cylinder 17 in the present engine cycle.  y% is de...";
CM_ SG_ 2364631550 ECd17IsttsSttOCstT "Engine Cylinder 17 Instantaneous Start of Combustion Timing: Instantaneous Start of Combustion timing is defined as the crank angle for which less than 5% of the fuel mass has been burned in the present engine cycle.  The data will report FB00h (6425...";
CM_ SG_ 2364631550 ECd17IsttsCtOCstT "Engine Cylinder 17 Instantaneous Center of Combustion Timing: Instantaneous Center of Combustion timing is defined as the crank angle for which 50% of the fuel mass has been burned in the present engine cycle.  The data will report FB00h (64256) when...";
CM_ BO_ 2364631806 "Engine Cylinder 18 Combustion Timing";
CM_ SG_ 2364631806 ECd18IsttsCstTPt1 "Engine Cylinder 18 Instantaneous Combustion Timing, Point 1: Engine Cylinder 18 Instantaneous Combustion Timing, Point 1 is defined as the crank angle for which x% of the fuel mass has been burned by Cylinder 18 in the present engine cycle.  x% is de...";
CM_ SG_ 2364631806 ECd18IsttsCstTPt2 "Engine Cylinder 18 Instantaneous Combustion Timing, Point 2: Engine Cylinder 18 Instantaneous Combustion Timing, Point 2 is defined as the crank angle for which y% of the fuel mass has been burned by Cylinder 18 in the present engine cycle.  y% is de...";
CM_ SG_ 2364631806 ECd18IsttsSttOCstT "Engine Cylinder 18 Instantaneous Start of Combustion Timing: Instantaneous Start of Combustion timing is defined as the crank angle for which less than 5% of the fuel mass has been burned in the present engine cycle.  The data will report FB00h (6425...";
CM_ SG_ 2364631806 ECd18IsttsCtOCstT "Engine Cylinder 18 Instantaneous Center of Combustion Timing: Instantaneous Center of Combustion timing is defined as the crank angle for which 50% of the fuel mass has been burned in the present engine cycle.  The data will report FB00h (64256) when...";
CM_ BO_ 2364632062 "Engine Cylinder 19 Combustion Timing";
CM_ SG_ 2364632062 ECd19IsttsCstTPt1 "Engine Cylinder 19 Instantaneous Combustion Timing, Point 1: Engine Cylinder 19 Instantaneous Combustion Timing, Point 1 is defined as the crank angle for which x% of the fuel mass has been burned by Cylinder 19 in the present engine cycle.  x% is de...";
CM_ SG_ 2364632062 ECd19IsttsCstTPt2 "Engine Cylinder 19 Instantaneous Combustion Timing, Point 2: Engine Cylinder 19 Instantaneous Combustion Timing, Point 2 is defined as the crank angle for which y% of the fuel mass has been burned by Cylinder 19 in the present engine cycle.  y% is de...";
CM_ SG_ 2364632062 ECd19IsttsSttOCstT "Engine Cylinder 19 Instantaneous Start of Combustion Timing: Instantaneous Start of Combustion timing is defined as the crank angle for which less than 5% of the fuel mass has been burned in the present engine cycle.  The data will report FB00h (6425...";
CM_ SG_ 2364632062 ECd19IsttsCtOCstT "Engine Cylinder 19 Instantaneous Center of Combustion Timing: Instantaneous Center of Combustion timing is defined as the crank angle for which 50% of the fuel mass has been burned in the present engine cycle.  The data will report FB00h (64256) when...";
CM_ BO_ 2364632318 "Engine Cylinder 20 Combustion Timing";
CM_ SG_ 2364632318 ECd20IsttsCstTPt1 "Engine Cylinder 20 Instantaneous Combustion Timing, Point 1: Engine Cylinder 20 Instantaneous Combustion Timing, Point 1 is defined as the crank angle for which x% of the fuel mass has been burned by Cylinder 20 in the present engine cycle.  x% is de...";
CM_ SG_ 2364632318 ECd20IsttsCstTPt2 "Engine Cylinder 20 Instantaneous Combustion Timing, Point 2: Engine Cylinder 20 Instantaneous Combustion Timing, Point 2 is defined as the crank angle for which y% of the fuel mass has been burned by Cylinder 20 in the present engine cycle.  y% is de...";
CM_ SG_ 2364632318 ECd20IsttsSttOCstT "Engine Cylinder 20 Instantaneous Start of Combustion Timing: Instantaneous Start of Combustion timing is defined as the crank angle for which less than 5% of the fuel mass has been burned in the present engine cycle.  The data will report FB00h (6425...";
CM_ SG_ 2364632318 ECd20IsttsCtOCstT "Engine Cylinder 20 Instantaneous Center of Combustion Timing: Instantaneous Center of Combustion timing is defined as the crank angle for which 50% of the fuel mass has been burned in the present engine cycle.  The data will report FB00h (64256) when...";
CM_ BO_ 2364632574 "Engine Cylinder 1 Combustion Metrics";
CM_ SG_ 2364632574 ECd1IsttsPCstPssT "Engine Cylinder 1 Instantaneous Peak Combustion Pressure Timing: The timing in crank angle degrees of the observed peak pressure during the current combustion cycle.  When the combustion happens after the TDC (Top Dead Center) of this cylinder, the t...";
CM_ SG_ 2364632574 ECd1IsttsIdtdMEtvPss "Engine Cylinder 1 Instantaneous Indicated Mean Effective Pressure: The indicated mean effective pressure (IMEP) is the work delivered to the piston over the entire cycle, per unit displaced volume.  This SP reports for the current engine cycle.  See ...";
CM_ SG_ 2364632574 EngineCylinder1MisfireRate "Engine Cylinder 1 Misfire Rate: The misfire rate of engine cylinder 1 over the number of engine cycles in SPN6394 represented as a percentage.";
CM_ SG_ 2364632574 EngineCylinder1Temperature "Engine Cylinder 1 Temperature: Gas temperature in cylinder measured at the cylinder head of cylinder 1.";
CM_ SG_ 2364632574 ECd1IdtdMEtvPssCtOV "Engine Cylinder 1 Indicated Mean Effective Pressure Coefficient of Variance : The indicated mean effective pressure coefficient of variance is the variability seen in IMEP over the number of engine cycles in SPN6394 represented as a percentage.";
CM_ BO_ 2364632830 "Engine Cylinder 2 Combustion Metrics";
CM_ SG_ 2364632830 ECd2IsttsPCstPssT "Engine Cylinder 2 Instantaneous Peak Combustion Pressure Timing: The timing in crank angle degrees of the observed peak pressure during the current combustion cycle.  When the combustion happens after the TDC (Top Dead Center) of this cylinder, the t...";
CM_ SG_ 2364632830 ECd2IsttsIdtdMEtvPss "Engine Cylinder 2 Instantaneous Indicated Mean Effective Pressure: The indicated mean effective pressure (IMEP) is the work delivered to the piston over the entire cycle, per unit displaced volume.  This SP reports for the current engine cycle.  See ...";
CM_ SG_ 2364632830 EngineCylinder2MisfireRate "Engine Cylinder 2 Misfire Rate: The misfire rate of engine Cylinder 2 over the number of engine cycles in SPN6394 represented as a percentage.";
CM_ SG_ 2364632830 EngineCylinder2Temperature "Engine Cylinder 2 Temperature: Gas temperature in cylinder measured at the cylinder head of cylinder 2.";
CM_ SG_ 2364632830 ECd2IdtdMEtvPssCtOV "Engine Cylinder 2 Indicated Mean Effective Pressure Coefficient of Variance : The indicated mean effective pressure coefficient of variance is the variability seen in IMEP over the number of engine cycles in SPN6394 represented as a percentage.";
CM_ BO_ 2364633086 "Engine Cylinder 3 Combustion Metrics";
CM_ SG_ 2364633086 ECd3IsttsPCstPssT "Engine Cylinder 3 Instantaneous Peak Combustion Pressure Timing: The timing in crank angle degrees of the observed peak pressure during the current combustion cycle.  When the combustion happens after the TDC (Top Dead Center) of this cylinder, the t...";
CM_ SG_ 2364633086 ECd3IsttsIdtdMEtvPss "Engine Cylinder 3 Instantaneous Indicated Mean Effective Pressure: The indicated mean effective pressure (IMEP) is the work delivered to the piston over the entire cycle, per unit displaced volume.  This SP reports for the current engine cycle.  See ...";
CM_ SG_ 2364633086 EngineCylinder3MisfireRate "Engine Cylinder 3 Misfire Rate: The misfire rate of engine Cylinder 3 over the number of engine cycles in SPN6394 represented as a percentage.";
CM_ SG_ 2364633086 EngineCylinder3Temperature "Engine Cylinder 3 Temperature: Gas temperature in cylinder measured at the cylinder head of cylinder 3.";
CM_ SG_ 2364633086 ECd3IdtdMEtvPssCtOV "Engine Cylinder 3 Indicated Mean Effective Pressure Coefficient of Variance : The indicated mean effective pressure coefficient of variance is the variability seen in IMEP over the number of engine cycles in SPN6394 represented as a percentage.";
CM_ BO_ 2364633342 "Engine Cylinder 4 Combustion Metrics";
CM_ SG_ 2364633342 ECd4IsttsPCstPssT "Engine Cylinder 4 Instantaneous Peak Combustion Pressure Timing: The timing in crank angle degrees of the observed peak pressure during the current combustion cycle.  When the combustion happens after the TDC (Top Dead Center) of this cylinder, the t...";
CM_ SG_ 2364633342 ECd4IsttsIdtdMEtvPss "Engine Cylinder 4 Instantaneous Indicated Mean Effective Pressure: The indicated mean effective pressure (IMEP) is the work delivered to the piston over the entire cycle, per unit displaced volume.  This SP reports for the current engine cycle.  See ...";
CM_ SG_ 2364633342 EngineCylinder4MisfireRate "Engine Cylinder 4 Misfire Rate: The misfire rate of engine Cylinder 4 over the number of engine cycles in SPN6394 represented as a percentage.";
CM_ SG_ 2364633342 EngineCylinder4Temperature "Engine Cylinder 4 Temperature: Gas temperature in cylinder measured at the cylinder head of cylinder 4.";
CM_ SG_ 2364633342 ECd4IdtdMEtvPssCtOV "Engine Cylinder 4 Indicated Mean Effective Pressure Coefficient of Variance : The indicated mean effective pressure coefficient of variance is the variability seen in IMEP over the number of engine cycles in SPN6394 represented as a percentage.";
CM_ BO_ 2364633598 "Engine Cylinder 5 Combustion Metrics";
CM_ SG_ 2364633598 ECd5IsttsPCstPssT "Engine Cylinder 5 Instantaneous Peak Combustion Pressure Timing: The timing in crank angle degrees of the observed peak pressure during the current combustion cycle.  When the combustion happens after the TDC (Top Dead Center) of this cylinder, the t...";
CM_ SG_ 2364633598 ECd5IsttsIdtdMEtvPss "Engine Cylinder 5 Instantaneous Indicated Mean Effective Pressure: The indicated mean effective pressure (IMEP) is the work delivered to the piston over the entire cycle, per unit displaced volume.  This SP reports for the current engine cycle.  See ...";
CM_ SG_ 2364633598 EngineCylinder5MisfireRate "Engine Cylinder 5 Misfire Rate: The misfire rate of engine Cylinder 5 over the number of engine cycles in SPN6394 represented as a percentage.";
CM_ SG_ 2364633598 EngineCylinder5Temperature "Engine Cylinder 5 Temperature: Gas temperature in cylinder measured at the cylinder head of cylinder 5.";
CM_ SG_ 2364633598 ECd5IdtdMEtvPssCtOV "Engine Cylinder 5 Indicated Mean Effective Pressure Coefficient of Variance : The indicated mean effective pressure coefficient of variance is the variability seen in IMEP over the number of engine cycles in SPN6394 represented as a percentage.";
CM_ BO_ 2364633854 "Engine Cylinder 6 Combustion Metrics";
CM_ SG_ 2364633854 ECd6IsttsPCstPssT "Engine Cylinder 6 Instantaneous Peak Combustion Pressure Timing: The timing in crank angle degrees of the observed peak pressure during the current combustion cycle.  When the combustion happens after the TDC (Top Dead Center) of this cylinder, the t...";
CM_ SG_ 2364633854 ECd6IsttsIdtdMEtvPss "Engine Cylinder 6 Instantaneous Indicated Mean Effective Pressure: The indicated mean effective pressure (IMEP) is the work delivered to the piston over the entire cycle, per unit displaced volume.  This SP reports for the current engine cycle.  See ...";
CM_ SG_ 2364633854 EngineCylinder6MisfireRate "Engine Cylinder 6 Misfire Rate: The misfire rate of engine Cylinder 6 over the number of engine cycles in SPN6394 represented as a percentage.";
CM_ SG_ 2364633854 EngineCylinder6Temperature "Engine Cylinder 6 Temperature: Gas temperature in cylinder measured at the cylinder head of cylinder 6.";
CM_ SG_ 2364633854 ECd6IdtdMEtvPssCtOV "Engine Cylinder 6 Indicated Mean Effective Pressure Coefficient of Variance : The indicated mean effective pressure coefficient of variance is the variability seen in IMEP over the number of engine cycles in SPN6394 represented as a percentage.";
CM_ BO_ 2364634110 "Engine Cylinder 7 Combustion Metrics";
CM_ SG_ 2364634110 ECd7IsttsPCstPssT "Engine Cylinder 7 Instantaneous Peak Combustion Pressure Timing: The timing in crank angle degrees of the observed peak pressure during the current combustion cycle.  When the combustion happens after the TDC (Top Dead Center) of this cylinder, the t...";
CM_ SG_ 2364634110 ECd7IsttsIdtdMEtvPss "Engine Cylinder 7 Instantaneous Indicated Mean Effective Pressure: The indicated mean effective pressure (IMEP) is the work delivered to the piston over the entire cycle, per unit displaced volume.  This SP reports for the current engine cycle.  See ...";
CM_ SG_ 2364634110 EngineCylinder7MisfireRate "Engine Cylinder 7 Misfire Rate: The misfire rate of engine Cylinder 7 over the number of engine cycles in SPN6394 represented as a percentage.";
CM_ SG_ 2364634110 EngineCylinder7Temperature "Engine Cylinder 7 Temperature: Gas temperature in cylinder measured at the cylinder head of cylinder 7.";
CM_ SG_ 2364634110 ECd7IdtdMEtvPssCtOV "Engine Cylinder 7 Indicated Mean Effective Pressure Coefficient of Variance : The indicated mean effective pressure coefficient of variance is the variability seen in IMEP over the number of engine cycles in SPN6394 represented as a percentage.";
CM_ BO_ 2364634366 "Engine Cylinder 8 Combustion Metrics";
CM_ SG_ 2364634366 ECd8IsttsPCstPssT "Engine Cylinder 8 Instantaneous Peak Combustion Pressure Timing: The timing in crank angle degrees of the observed peak pressure during the current combustion cycle.  When the combustion happens after the TDC (Top Dead Center) of this cylinder, the t...";
CM_ SG_ 2364634366 ECd8IsttsIdtdMEtvPss "Engine Cylinder 8 Instantaneous Indicated Mean Effective Pressure: The indicated mean effective pressure (IMEP) is the work delivered to the piston over the entire cycle, per unit displaced volume.  This SP reports for the current engine cycle.  See ...";
CM_ SG_ 2364634366 EngineCylinder8MisfireRate "Engine Cylinder 8 Misfire Rate: The misfire rate of engine Cylinder 8 over the number of engine cycles in SPN6394 represented as a percentage.";
CM_ SG_ 2364634366 EngineCylinder8Temperature "Engine Cylinder 8 Temperature: Gas temperature in cylinder measured at the cylinder head of cylinder 8.";
CM_ SG_ 2364634366 ECd8IdtdMEtvPssCtOV "Engine Cylinder 8 Indicated Mean Effective Pressure Coefficient of Variance : The indicated mean effective pressure coefficient of variance is the variability seen in IMEP over the number of engine cycles in SPN6394 represented as a percentage.";
CM_ BO_ 2364634622 "Engine Cylinder 9 Combustion Metrics";
CM_ SG_ 2364634622 ECd9IsttsPCstPssT "Engine Cylinder 9 Instantaneous Peak Combustion Pressure Timing: The timing in crank angle degrees of the observed peak pressure during the current combustion cycle.  When the combustion happens after the TDC (Top Dead Center) of this cylinder, the t...";
CM_ SG_ 2364634622 ECd9IsttsIdtdMEtvPss "Engine Cylinder 9 Instantaneous Indicated Mean Effective Pressure: The indicated mean effective pressure (IMEP) is the work delivered to the piston over the entire cycle, per unit displaced volume.  This SP reports for the current engine cycle.  See ...";
CM_ SG_ 2364634622 EngineCylinder9MisfireRate "Engine Cylinder 9 Misfire Rate: The misfire rate of engine Cylinder 9 over the number of engine cycles in SPN6394 represented as a percentage.";
CM_ SG_ 2364634622 EngineCylinder9Temperature "Engine Cylinder 9 Temperature: Gas temperature in cylinder measured at the cylinder head of cylinder 9.";
CM_ SG_ 2364634622 ECd9IdtdMEtvPssCtOV "Engine Cylinder 9 Indicated Mean Effective Pressure Coefficient of Variance : The indicated mean effective pressure coefficient of variance is the variability seen in IMEP over the number of engine cycles in SPN6394 represented as a percentage.";
CM_ BO_ 2364634878 "Engine Cylinder 10 Combustion Metrics";
CM_ SG_ 2364634878 ECd10IsttsPCstPssT "Engine Cylinder 10 Instantaneous Peak Combustion Pressure Timing: The timing in crank angle degrees of the observed peak pressure during the current combustion cycle.  When the combustion happens after the TDC (Top Dead Center) of this cylinder, the ...";
CM_ SG_ 2364634878 ECd10IsttsIdtdMEtvPss "Engine Cylinder 10 Instantaneous Indicated Mean Effective Pressure: The indicated mean effective pressure (IMEP) is the work delivered to the piston over the entire cycle, per unit displaced volume.  This SP reports for the current engine cycle.  See...";
CM_ SG_ 2364634878 EngineCylinder10MisfireRate "Engine Cylinder 10 Misfire Rate: The misfire rate of engine Cylinder 10 over the number of engine cycles in SPN6394 represented as a percentage.";
CM_ SG_ 2364634878 EngineCylinder10Temperature "Engine Cylinder 10 Temperature: Gas temperature in cylinder measured at the cylinder head of cylinder 10.";
CM_ SG_ 2364634878 ECd10IdtdMEtvPssCtOV "Engine Cylinder 10 Indicated Mean Effective Pressure Coefficient of Variance : The indicated mean effective pressure coefficient of variance is the variability seen in IMEP over the number of engine cycles in SPN6394 represented as a percentage.";
CM_ BO_ 2364635134 "Engine Cylinder 11 Combustion Metrics";
CM_ SG_ 2364635134 ECd11IsttsPCstPssT "Engine Cylinder 11 Instantaneous Peak Combustion Pressure Timing: The timing in crank angle degrees of the observed peak pressure during the current combustion cycle.  When the combustion happens after the TDC (Top Dead Center) of this cylinder, the ...";
CM_ SG_ 2364635134 ECd11IsttsIdtdMEtvPss "Engine Cylinder 11 Instantaneous Indicated Mean Effective Pressure: The indicated mean effective pressure (IMEP) is the work delivered to the piston over the entire cycle, per unit displaced volume.  This SP reports for the current engine cycle.  See...";
CM_ SG_ 2364635134 EngineCylinder11MisfireRate "Engine Cylinder 11 Misfire Rate: The misfire rate of engine Cylinder 11 over the number of engine cycles in SPN6394 represented as a percentage.";
CM_ SG_ 2364635134 EngineCylinder11Temperature "Engine Cylinder 11 Temperature: Gas temperature in cylinder measured at the cylinder head of cylinder 11.";
CM_ SG_ 2364635134 ECd11IdtdMEtvPssCtOV "Engine Cylinder 11 Indicated Mean Effective Pressure Coefficient of Variance : The indicated mean effective pressure coefficient of variance is the variability seen in IMEP over the number of engine cycles in SPN6394 represented as a percentage.";
CM_ BO_ 2364635390 "Engine Cylinder 12 Combustion Metrics";
CM_ SG_ 2364635390 ECd12IsttsPCstPssT "Engine Cylinder 12 Instantaneous Peak Combustion Pressure Timing: The timing in crank angle degrees of the observed peak pressure during the current combustion cycle.  When the combustion happens after the TDC (Top Dead Center) of this cylinder, the ...";
CM_ SG_ 2364635390 ECd12IsttsIdtdMEtvPss "Engine Cylinder 12 Instantaneous Indicated Mean Effective Pressure: The indicated mean effective pressure (IMEP) is the work delivered to the piston over the entire cycle, per unit displaced volume.  This SP reports for the current engine cycle.  See...";
CM_ SG_ 2364635390 EngineCylinder12MisfireRate "Engine Cylinder 12 Misfire Rate: The misfire rate of engine Cylinder 12 over the number of engine cycles in SPN6394 represented as a percentage.";
CM_ SG_ 2364635390 EngineCylinder12Temperature "Engine Cylinder 12 Temperature: Gas temperature in cylinder measured at the cylinder head of cylinder 12.";
CM_ SG_ 2364635390 ECd12IdtdMEtvPssCtOV "Engine Cylinder 12 Indicated Mean Effective Pressure Coefficient of Variance : The indicated mean effective pressure coefficient of variance is the variability seen in IMEP over the number of engine cycles in SPN6394 represented as a percentage.";
CM_ BO_ 2364635646 "Engine Cylinder 13 Combustion Metrics";
CM_ SG_ 2364635646 ECd13IsttsPCstPssT "Engine Cylinder 13 Instantaneous Peak Combustion Pressure Timing: The timing in crank angle degrees of the observed peak pressure during the current combustion cycle.  When the combustion happens after the TDC (Top Dead Center) of this cylinder, the ...";
CM_ SG_ 2364635646 ECd13IsttsIdtdMEtvPss "Engine Cylinder 13 Instantaneous Indicated Mean Effective Pressure: The indicated mean effective pressure (IMEP) is the work delivered to the piston over the entire cycle, per unit displaced volume.  This SP reports for the current engine cycle.  See...";
CM_ SG_ 2364635646 EngineCylinder13MisfireRate "Engine Cylinder 13 Misfire Rate: The misfire rate of engine Cylinder 13 over the number of engine cycles in SPN6394 represented as a percentage.";
CM_ SG_ 2364635646 EngineCylinder13Temperature "Engine Cylinder 13 Temperature: Gas temperature in cylinder measured at the cylinder head of cylinder 13.";
CM_ SG_ 2364635646 ECd13IdtdMEtvPssCtOV "Engine Cylinder 13 Indicated Mean Effective Pressure Coefficient of Variance : The indicated mean effective pressure coefficient of variance is the variability seen in IMEP over the number of engine cycles in SPN6394 represented as a percentage.";
CM_ BO_ 2364635902 "Engine Cylinder 14 Combustion Metrics";
CM_ SG_ 2364635902 ECd14IsttsPCstPssT "Engine Cylinder 14 Instantaneous Peak Combustion Pressure Timing: The timing in crank angle degrees of the observed peak pressure during the current combustion cycle.  When the combustion happens after the TDC (Top Dead Center) of this cylinder, the ...";
CM_ SG_ 2364635902 ECd14IsttsIdtdMEtvPss "Engine Cylinder 14 Instantaneous Indicated Mean Effective Pressure: The indicated mean effective pressure (IMEP) is the work delivered to the piston over the entire cycle, per unit displaced volume.  This SP reports for the current engine cycle.  See...";
CM_ SG_ 2364635902 EngineCylinder14MisfireRate "Engine Cylinder 14 Misfire Rate: The misfire rate of engine Cylinder 14 over the number of engine cycles in SPN6394 represented as a percentage.";
CM_ SG_ 2364635902 EngineCylinder14Temperature "Engine Cylinder 14 Temperature: Gas temperature in cylinder measured at the cylinder head of cylinder 14.";
CM_ SG_ 2364635902 ECd14IdtdMEtvPssCtOV "Engine Cylinder 14 Indicated Mean Effective Pressure Coefficient of Variance : The indicated mean effective pressure coefficient of variance is the variability seen in IMEP over the number of engine cycles in SPN6394 represented as a percentage.";
CM_ BO_ 2364636158 "Engine Cylinder 15 Combustion Metrics";
CM_ SG_ 2364636158 ECd15IsttsPCstPssT "Engine Cylinder 15 Instantaneous Peak Combustion Pressure Timing: The timing in crank angle degrees of the observed peak pressure during the current combustion cycle.  When the combustion happens after the TDC (Top Dead Center) of this cylinder, the ...";
CM_ SG_ 2364636158 ECd15IsttsIdtdMEtvPss "Engine Cylinder 15 Instantaneous Indicated Mean Effective Pressure: The indicated mean effective pressure (IMEP) is the work delivered to the piston over the entire cycle, per unit displaced volume.  This SP reports for the current engine cycle.  See...";
CM_ SG_ 2364636158 EngineCylinder15MisfireRate "Engine Cylinder 15 Misfire Rate: The misfire rate of engine Cylinder 15 over the number of engine cycles in SPN6394 represented as a percentage.";
CM_ SG_ 2364636158 EngineCylinder15Temperature "Engine Cylinder 15 Temperature: Gas temperature in cylinder measured at the cylinder head of cylinder 15.";
CM_ SG_ 2364636158 ECd15IdtdMEtvPssCtOV "Engine Cylinder 15 Indicated Mean Effective Pressure Coefficient of Variance : The indicated mean effective pressure coefficient of variance is the variability seen in IMEP over the number of engine cycles in SPN6394 represented as a percentage.";
CM_ BO_ 2364636414 "Engine Cylinder 16 Combustion Metrics";
CM_ SG_ 2364636414 ECd16IsttsPCstPssT "Engine Cylinder 16 Instantaneous Peak Combustion Pressure Timing: The timing in crank angle degrees of the observed peak pressure during the current combustion cycle.  When the combustion happens after the TDC (Top Dead Center) of this cylinder, the ...";
CM_ SG_ 2364636414 ECd16IsttsIdtdMEtvPss "Engine Cylinder 16 Instantaneous Indicated Mean Effective Pressure: The indicated mean effective pressure (IMEP) is the work delivered to the piston over the entire cycle, per unit displaced volume.  This SP reports for the current engine cycle.  See...";
CM_ SG_ 2364636414 EngineCylinder16MisfireRate "Engine Cylinder 16 Misfire Rate: The misfire rate of engine Cylinder 16 over the number of engine cycles in SPN6394 represented as a percentage.";
CM_ SG_ 2364636414 EngineCylinder16Temperature "Engine Cylinder 16 Temperature: Gas temperature in cylinder measured at the cylinder head of cylinder 16.";
CM_ SG_ 2364636414 ECd16IdtdMEtvPssCtOV "Engine Cylinder 16 Indicated Mean Effective Pressure Coefficient of Variance : The indicated mean effective pressure coefficient of variance is the variability seen in IMEP over the number of engine cycles in SPN6394 represented as a percentage.";
CM_ BO_ 2364636670 "Engine Cylinder 17 Combustion Metrics";
CM_ SG_ 2364636670 ECd17IsttsPCstPssT "Engine Cylinder 17 Instantaneous Peak Combustion Pressure Timing: The timing in crank angle degrees of the observed peak pressure during the current combustion cycle.  When the combustion happens after the TDC (Top Dead Center) of this cylinder, the ...";
CM_ SG_ 2364636670 ECd17IsttsIdtdMEtvPss "Engine Cylinder 17 Instantaneous Indicated Mean Effective Pressure: The indicated mean effective pressure (IMEP) is the work delivered to the piston over the entire cycle, per unit displaced volume.  This SP reports for the current engine cycle.  See...";
CM_ SG_ 2364636670 EngineCylinder17MisfireRate "Engine Cylinder 17 Misfire Rate: The misfire rate of engine Cylinder 17 over the number of engine cycles in SPN6394 represented as a percentage.";
CM_ SG_ 2364636670 EngineCylinder17Temperature "Engine Cylinder 17 Temperature: Gas temperature in cylinder measured at the cylinder head of cylinder 17.";
CM_ SG_ 2364636670 ECd17IdtdMEtvPssCtOV "Engine Cylinder 17 Indicated Mean Effective Pressure Coefficient of Variance : The indicated mean effective pressure coefficient of variance is the variability seen in IMEP over the number of engine cycles in SPN6394 represented as a percentage.";
CM_ BO_ 2364636926 "Engine Cylinder 18 Combustion Metrics";
CM_ SG_ 2364636926 ECd18IsttsPCstPssT "Engine Cylinder 18 Instantaneous Peak Combustion Pressure Timing: The timing in crank angle degrees of the observed peak pressure during the current combustion cycle.  When the combustion happens after the TDC (Top Dead Center) of this cylinder, the ...";
CM_ SG_ 2364636926 ECd18IsttsIdtdMEtvPss "Engine Cylinder 18 Instantaneous Indicated Mean Effective Pressure: The indicated mean effective pressure (IMEP) is the work delivered to the piston over the entire cycle, per unit displaced volume.  This SP reports for the current engine cycle.  See...";
CM_ SG_ 2364636926 EngineCylinder18MisfireRate "Engine Cylinder 18 Misfire Rate: The misfire rate of engine Cylinder 18 over the number of engine cycles in SPN6394 represented as a percentage.";
CM_ SG_ 2364636926 EngineCylinder18Temperature "Engine Cylinder 18 Temperature: Gas temperature in cylinder measured at the cylinder head of cylinder 18.";
CM_ SG_ 2364636926 ECd18IdtdMEtvPssCtOV "Engine Cylinder 18 Indicated Mean Effective Pressure Coefficient of Variance : The indicated mean effective pressure coefficient of variance is the variability seen in IMEP over the number of engine cycles in SPN6394 represented as a percentage.";
CM_ BO_ 2364637182 "Engine Cylinder 19 Combustion Metrics";
CM_ SG_ 2364637182 ECd19IsttsPCstPssT "Engine Cylinder 19 Instantaneous Peak Combustion Pressure Timing: The timing in crank angle degrees of the observed peak pressure during the current combustion cycle.  When the combustion happens after the TDC (Top Dead Center) of this cylinder, the ...";
CM_ SG_ 2364637182 ECd19IsttsIdtdMEtvPss "Engine Cylinder 19 Instantaneous Indicated Mean Effective Pressure: The indicated mean effective pressure (IMEP) is the work delivered to the piston over the entire cycle, per unit displaced volume.  This SP reports for the current engine cycle.  See...";
CM_ SG_ 2364637182 EngineCylinder19MisfireRate "Engine Cylinder 19 Misfire Rate: The misfire rate of engine Cylinder 19 over the number of engine cycles in SPN6394 represented as a percentage.";
CM_ SG_ 2364637182 EngineCylinder19Temperature "Engine Cylinder 19 Temperature: Gas temperature in cylinder measured at the cylinder head of cylinder 19.";
CM_ SG_ 2364637182 ECd19IdtdMEtvPssCtOV "Engine Cylinder 19 Indicated Mean Effective Pressure Coefficient of Variance : The indicated mean effective pressure coefficient of variance is the variability seen in IMEP over the number of engine cycles in SPN6394 represented as a percentage.";
CM_ BO_ 2364637438 "Engine Cylinder 20 Combustion Metrics";
CM_ SG_ 2364637438 ECd20IsttsPCstPssT "Engine Cylinder 20 Instantaneous Peak Combustion Pressure Timing: The timing in crank angle degrees of the observed peak pressure during the current combustion cycle.  When the combustion happens after the TDC (Top Dead Center) of this cylinder, the ...";
CM_ SG_ 2364637438 ECd20IsttsIdtdMEtvPss "Engine Cylinder 20 Instantaneous Indicated Mean Effective Pressure: The indicated mean effective pressure (IMEP) is the work delivered to the piston over the entire cycle, per unit displaced volume.  This SP reports for the current engine cycle.  See...";
CM_ SG_ 2364637438 EngineCylinder20MisfireRate "Engine Cylinder 20 Misfire Rate: The misfire rate of engine Cylinder 20 over the number of engine cycles in SPN6394 represented as a percentage.";
CM_ SG_ 2364637438 EngineCylinder20Temperature "Engine Cylinder 20 Temperature: Gas temperature in cylinder measured at the cylinder head of cylinder 20.";
CM_ SG_ 2364637438 ECd20IdtdMEtvPssCtOV "Engine Cylinder 20 Indicated Mean Effective Pressure Coefficient of Variance : The indicated mean effective pressure coefficient of variance is the variability seen in IMEP over the number of engine cycles in SPN6394 represented as a percentage.";
CM_ BO_ 2364637694 "Motor/Generator 1 Inverter Mode Feedback 1";
CM_ SG_ 2364637694 MtrGnrtr1InvrtrMdFdk1Cntr "Motor/Generator 1 Inverter Mode Feedback 1 Counter: The message counter is used to detect situations where the transmitting ECU malfunction repeats the same frame all the time. The receiver of the information may use the counter parameter to detect t...";
CM_ SG_ 2364637694 MtrGnrtr1InvrtrCntrlLmtsOvrrdMd "Motor/Generator 1 Inverter Control Limits Override Mode: During normal operation this will have the same value as SPN 10159 [Control Limits Request Override Mode].  0 = Operating limits are not overridden.  If a limit was previously active, then it h...";
CM_ SG_ 2364637694 MtrGnrtr1InvrtrCntrlStpntMd "Motor/Generator 1 Inverter Control Setpoint Mode: Reports the inverter mode (See SPN 10162 [Control Setpoint Mode Request] for requested mode).Passive modes:  0 = Powered On - the inverter is commanded to be powered on and able to communicate, but th...";
CM_ SG_ 2364637694 MtrGnrtr1InvrtrMdFdk1Cr "Motor/Generator 1 Inverter Mode Feedback 1 CRC: The CRC is defined as follows: - Length: 8 bits- Polynomial: x^8+x^5+x^3+x^2+x+1- Initial Value: FFh- Input Data Reflection: Not reflected- Result Data Reflection: Not reflected- XOR value: FFh SAE make...";
CM_ SG_ 2364637694 MtrGnrtr1InvrtrHvlStts "Motor/Generator 1 Inverter HVIL Status: Reports the High Voltage Interlock Loop (HVIL) state.00b = HVIL Closed01b = HVIL Open10b = Error11b = Not Available";
CM_ BO_ 2565964542 "Motor/Generator 1 Inverter Limits Active Power";
CM_ SG_ 2565964542 MtrGnrtr1InvrtrLmtsAtvPwrCntr "Motor/Generator 1 Inverter Limits Active Power Counter: The message counter is used to detect situations where the transmitting ECU malfunction repeats the same frame all the time. The receiver of the information may use the counter parameter to dete...";
CM_ SG_ 2565964542 MtrGnrtr1InvrtrLmtsAtvPwrCr "Motor/Generator 1 Inverter Limits Active Power CRC: The CRC is defined as follows: - Length: 8 bits- Polynomial: x^8+x^5+x^3+x^2+x+1- Initial Value: FFh- Input Data Reflection: Not reflected- Result Data Reflection: Not reflected- XOR value: FFh SAE ...";
CM_ SG_ 2565964542 MtGt1IvtLtsAtvMPwMx "Motor/Generator 1 Inverter Limits Active Mechanical Power Maximum: The inverter keeps the mechanical motor power below this value.   This limit may be set in response to a Limits Request or determined by the inverter based on operating conditions.Ref...";
CM_ SG_ 2565964542 MtGt1IvtLtsAtvMPwM "Motor/Generator 1 Inverter Limits Active Mechanical Power Minimum: The inverter keeps the mechanical motor power above this value.   This limit may be set in response to a Limits Request or determined by the inverter based on operating conditions.Ref...";
CM_ SG_ 2565964542 MtGt1IvtLtsAtvDSdPwMx "Motor/Generator 1 Inverter Limits Active DC Side Power Maximum: The inverter keeps the DC Side power below this value.   This limit may be set in response to a Limits Request or determined by the inverter based on operating conditions.Refer to SPN 10...";
CM_ SG_ 2565964542 MtGt1IvtLtsAtvDSdPwM "Motor/Generator 1 Inverter Limits Active DC Side Power Minimum: The inverter keeps the DC side power above this value.   This limit may be set in response to a Limits Request or determined by the inverter based on operating conditions.Refer to SPN 10...";
CM_ BO_ 2565964798 "Motor/Generator 1 Inverter Limits Active Mechanical";
CM_ SG_ 2565964798 MtrGnrtr1InvrtrLmtsAtvMhnlCntr "Motor/Generator 1 Inverter Limits Active Mechanical Counter: The message counter is used to detect situations where the transmitting ECU malfunction repeats the same frame all the time. The receiver of the information may use the counter parameter to...";
CM_ SG_ 2565964798 MtrGnrtr1InvrtrLmtsAtvMhnlCr "Motor/Generator 1 Inverter Limits Active Mechanical CRC: The CRC is defined as follows: - Length: 8 bits- Polynomial: x^8+x^5+x^3+x^2+x+1- Initial Value: FFh- Input Data Reflection: Not reflected- Result Data Reflection: Not reflected- XOR value: FFh...";
CM_ SG_ 2565964798 MtrGnrtr1InvrtrLmtsAtvTrqMxmm "Motor/Generator 1 Inverter Limits Active Torque Maximum: The inverter keeps the motor torque below this value.  This limit may be set in response to a Limits Request or determined by the inverter based on operating conditions.Refer to SPN 10170 [Refe...";
CM_ SG_ 2565964798 MtrGnrtr1InvrtrLmtsAtvTrqMnmm "Motor/Generator 1 Inverter Limits Active Torque Minimum: The inverter keeps the motor torque above this value.  This limit may be set in response to a Limits Request or determined by the inverter based on operating conditions.Refer to SPN 10170 [Refe...";
CM_ SG_ 2565964798 MtrGnrtr1InvrtrLmtsAtvSpdMxmm "Motor/Generator 1 Inverter Limits Active Speed Maximum: The inverter keeps the motor speed below this value.  This limit may be set in response to a Limits Request or determined by the inverter based on operating conditions.Refer to SPN 10171 [Refere...";
CM_ SG_ 2565964798 MtrGnrtr1InvrtrLmtsAtvSpdMnmm "Motor/Generator 1 Inverter Limits Active Speed Minimum: The inverter keeps the motor Speed above this value.  This limit may be set in response to a Limits Request or determined by the inverter based on operating conditions.Refer to SPN 10171 [Refere...";
CM_ BO_ 2565965054 "Motor/Generator 1 Inverter Limits Active DC Side";
CM_ SG_ 2565965054 MtrGnrtr1InvrtrLmtsAtvDSdCr "Motor/Generator 1 Inverter Limits Active DC Side CRC: The CRC is defined as follows: - Length: 8 bits- Polynomial: x^8+x^5+x^3+x^2+x+1- Initial Value: FFh- Input Data Reflection: Not reflected- Result Data Reflection: Not reflected- XOR value: FFh SA...";
CM_ SG_ 2565965054 MtrGnrtr1InvrtrLmtsAtvDSdCntr "Motor/Generator 1 Inverter Limits Active DC Side Counter: The message counter is used to detect situations where the transmitting ECU malfunction repeats the same frame all the time. The receiver of the information may use the counter parameter to de...";
CM_ SG_ 2565965054 MtGt1IvtLtsAtvDSdVtMx "Motor/Generator 1 Inverter Limits Active DC Side Voltage Maximum: The inverter keeps the DC side voltage below this value.  This limit may be set in response to a Limits Request or determined by the inverter based on operating conditions.Refer to SPN...";
CM_ SG_ 2565965054 MtGt1IvtLtsAtvDSdVtM "Motor/Generator 1 Inverter Limits Active DC Side Voltage Minimum: The inverter keeps the DC side voltage above this value.  This limit may be set in response to a Limits Request or determined by the inverter based on operating conditions.Refer to SPN...";
CM_ SG_ 2565965054 MtGt1IvtLtsAtvDSdCtMx "Motor/Generator 1 Inverter Limits Active DC Side Current Maximum: The inverter keeps the DC side current below this value.  This limit may be set in response to a Limits Request or determined by the inverter based on operating conditions. Refer to SP...";
CM_ SG_ 2565965054 MtGt1IvtLtsAtvDSdCtM "Motor/Generator 1 Inverter Limits Active DC Side Current Minimum: The inverter keeps the DC side current above this value.  This limit may be set in response to a Limits Request or determined by the inverter based on operating conditions.Refer to SPN...";
CM_ BO_ 2565965310 "Motor/Generator 1 Inverter Low Voltage";
CM_ SG_ 2565965310 MtrGnrtr1InvrtrSwthdIgntnVltg "Motor/Generator 1 Inverter Switched Ignition Voltage: Switched Ignition voltage supplied to this instance of the inverter controller.";
CM_ SG_ 2565965310 MtrGnrtr1InvrtrUnswthdSlVltg "Motor/Generator 1 Inverter Unswitched SLI Voltage: Continuously supplied SLI power to this instance of the inverter controller.";
CM_ BO_ 2364638974 "Motor/Generator 2 Inverter Mode Feedback 1";
CM_ SG_ 2364638974 MtrGnrtr2InvrtrMdFdk1Cntr "Motor/Generator 2 Inverter Mode Feedback 1 Counter: The message counter is used to detect situations where the transmitting ECU malfunction repeats the same frame all the time. The receiver of the information may use the counter parameter to detect t...";
CM_ SG_ 2364638974 MtrGnrtr2InvrtrCntrlLmtsOvrrdMd "Motor/Generator 2 Inverter Control Limits Override Mode: During normal operation this will have the same value as SPN 10225 [Control Limits Request Override Mode].0 = Operating limits are not overridden.  If a limit was previously active, then it has...";
CM_ SG_ 2364638974 MtrGnrtr2InvrtrCntrlStpntMd "Motor/Generator 2 Inverter Control Setpoint Mode: Reports the inverter mode (See SPN 10228 [Control Setpoint Mode Request] for requested mode).Passive modes:  0 = Powered On - the inverter is commanded to be powered on and able to communicate, but th...";
CM_ SG_ 2364638974 MtrGnrtr2InvrtrMdFdk1Cr "Motor/Generator 2 Inverter Mode Feedback 1 CRC: The CRC is defined as follows: - Length: 8 bits- Polynomial: x^8+x^5+x^3+x^2+x+1- Initial Value: FFh- Input Data Reflection: Not reflected- Result Data Reflection: Not reflected- XOR value: FFh SAE make...";
CM_ SG_ 2364638974 MtrGnrtr2InvrtrHvlStts "Motor/Generator 2 Inverter HVIL Status: Reports the High Voltage Interlock Loop (HVIL) state.00b = HVIL Closed01b = HVIL Open10b = Error11b = Not Available";
CM_ BO_ 2565965822 "Motor/Generator 2 Inverter Limits Active Power";
CM_ SG_ 2565965822 MtrGnrtr2InvrtrLmtsAtvPwrCntr "Motor/Generator 2 Inverter Limits Active Power Counter: The message counter is used to detect situations where the transmitting ECU malfunction repeats the same frame all the time. The receiver of the information may use the counter parameter to dete...";
CM_ SG_ 2565965822 MtrGnrtr2InvrtrLmtsAtvPwrCr "Motor/Generator 2 Inverter Limits Active Power CRC: The CRC is defined as follows: - Length: 8 bits- Polynomial: x^8+x^5+x^3+x^2+x+1- Initial Value: FFh- Input Data Reflection: Not reflected- Result Data Reflection: Not reflected- XOR value: FFh SAE ...";
CM_ SG_ 2565965822 MtGt2IvtLtsAtvMPwMx "Motor/Generator 2 Inverter Limits Active Mechanical Power Maximum: The inverter keeps the mechanical motor power below this value.   This limit may be set in response to a Limits Request or determined by the inverter based on operating conditions.Ref...";
CM_ SG_ 2565965822 MtGt2IvtLtsAtvMPwM "Motor/Generator 2 Inverter Limits Active Mechanical Power Minimum: The inverter keeps the mechanical motor power above this value.   This limit may be set in response to a Limits Request or determined by the inverter based on operating conditions.Ref...";
CM_ SG_ 2565965822 MtGt2IvtLtsAtvDSdPwMx "Motor/Generator 2 Inverter Limits Active DC Side Power Maximum: The inverter keeps the DC Side power below this value.   This limit may be set in response to a Limits Request or determined by the inverter based on operating conditions.Refer to SPN 10...";
CM_ SG_ 2565965822 MtGt2IvtLtsAtvDSdPwM "Motor/Generator 2 Inverter Limits Active DC Side Power Minimum: The inverter keeps the DC side power above this value.   This limit may be set in response to a Limits Request or determined by the inverter based on operating conditions.Refer to SPN 10...";
CM_ BO_ 2565966078 "Motor/Generator 2 Inverter Limits Active Mechanical";
CM_ SG_ 2565966078 MtrGnrtr2InvrtrLmtsAtvMhnlCntr "Motor/Generator 2 Inverter Limits Active Mechanical Counter: The message counter is used to detect situations where the transmitting ECU malfunction repeats the same frame all the time. The receiver of the information may use the counter parameter to...";
CM_ SG_ 2565966078 MtrGnrtr2InvrtrLmtsAtvMhnlCr "Motor/Generator 2 Inverter Limits Active Mechanical CRC: The CRC is defined as follows: - Length: 8 bits- Polynomial: x^8+x^5+x^3+x^2+x+1- Initial Value: FFh- Input Data Reflection: Not reflected- Result Data Reflection: Not reflected- XOR value: FFh...";
CM_ SG_ 2565966078 MtrGnrtr2InvrtrLmtsAtvTrqMxmm "Motor/Generator 2 Inverter Limits Active Torque Maximum: The inverter keeps the motor torque below this value.  This limit may be set in response to a Limits Request or determined by the inverter based on operating conditions.Refer to SPN 10236 [Refe...";
CM_ SG_ 2565966078 MtrGnrtr2InvrtrLmtsAtvTrqMnmm "Motor/Generator 2 Inverter Limits Active Torque Minimum: The inverter keeps the motor torque above this value.  This limit may be set in response to a Limits Request or determined by the inverter based on operating conditions.Refer to SPN 10236 [Refe...";
CM_ SG_ 2565966078 MtrGnrtr2InvrtrLmtsAtvSpdMxmm "Motor/Generator 2 Inverter Limits Active Speed Maximum: The inverter keeps the motor speed below this value.  This limit may be set in response to a Limits Request or determined by the inverter based on operating conditions.Refer to SPN 10237 [Refere...";
CM_ SG_ 2565966078 MtrGnrtr2InvrtrLmtsAtvSpdMnmm "Motor/Generator 2 Inverter Limits Active Speed Minimum: The inverter keeps the motor Speed above this value.  This limit may be set in response to a Limits Request or determined by the inverter based on operating conditions.Refer to SPN 10237 [Refere...";
CM_ BO_ 2565966334 "Motor/Generator 2 Inverter Limits Active DC Side";
CM_ SG_ 2565966334 MtrGnrtr2InvrtrLmtsAtvDSdCr "Motor/Generator 2 Inverter Limits Active DC Side CRC: The CRC is defined as follows: - Length: 8 bits- Polynomial: x^8+x^5+x^3+x^2+x+1- Initial Value: FFh- Input Data Reflection: Not reflected- Result Data Reflection: Not reflected- XOR value: FFh SA...";
CM_ SG_ 2565966334 MtrGnrtr2InvrtrLmtsAtvDSdCntr "Motor/Generator 2 Inverter Limits Active DC Side Counter: The message counter is used to detect situations where the transmitting ECU malfunction repeats the same frame all the time. The receiver of the information may use the counter parameter to de...";
CM_ SG_ 2565966334 MtGt2IvtLtsAtvDSdVtMx "Motor/Generator 2 Inverter Limits Active DC Side Voltage Maximum: The inverter keeps the DC side voltage below this value.  This limit may be set in response to a Limits Request or determined by the inverter based on operating conditions.Refer to SPN...";
CM_ SG_ 2565966334 MtGt2IvtLtsAtvDSdVtM "Motor/Generator 2 Inverter Limits Active DC Side Voltage Minimum: The inverter keeps the DC side voltage above this value.  This limit may be set in response to a Limits Request or determined by the inverter based on operating conditions.Refer to SPN...";
CM_ SG_ 2565966334 MtGt2IvtLtsAtvDSdCtMx "Motor/Generator 2 Inverter Limits Active DC Side Current Maximum: The inverter keeps the DC side current below this value.  This limit may be set in response to a Limits Request or determined by the inverter based on operating conditions. Refer to SP...";
CM_ SG_ 2565966334 MtGt2IvtLtsAtvDSdCtM "Motor/Generator 2 Inverter Limits Active DC Side Current Minimum: The inverter keeps the DC side current above this value.  This limit may be set in response to a Limits Request or determined by the inverter based on operating conditions.Refer to SPN...";
CM_ BO_ 2565966590 "Motor/Generator 2 Inverter Low Voltage";
CM_ SG_ 2565966590 MtrGnrtr2InvrtrSwthdIgntnVltg "Motor/Generator 2 Inverter Switched Ignition Voltage: Switched Ignition voltage supplied to this instance of the inverter controller.";
CM_ SG_ 2565966590 MtrGnrtr2InvrtrUnswthdSlVltg "Motor/Generator 2 Inverter Unswitched SLI Voltage: Continuously supplied SLI power to this instance of the inverter controller.";
CM_ BO_ 2365287678 "Motor/Generator 2 Inverter Reference 1";
CM_ SG_ 2365287678 MtrGnrtr2InvrtrRfrn1Cntr "Motor/Generator 2 Inverter Reference 1 Counter: The message counter is used to detect situations where the transmitting ECU malfunction repeats the same frame all the time. The receiver of the information may use the counter parameter to detect this ...";
CM_ SG_ 2365287678 MtrGnrtr2InvrtrRfrnTrq "Motor/Generator 2 Inverter Reference Torque: This value is used for converting torque in percent to units of Nm.Value in Nm = (Percent Value)/(100%) * (Reference Torque)For example, if this parameter has a value of 400 Nm and the percent value is equ...";
CM_ SG_ 2365287678 MtrGnrtr2InvrtrRfrnSpd "Motor/Generator 2 Inverter Reference Speed: This value is used for converting Speed in percent to units of rpm.Value in rpm = (Percent Value)/(100%) * (Reference Speed)For example, if this parameter has a value of 8192 rpm and the percent value is eq...";
CM_ SG_ 2365287678 MtrGnrtr2InvrtrRfrnPwr "Motor/Generator 2 Inverter Reference Power: This value is used for converting power in percent to units of kW.  It is applicable to both mechanical and electrical power.(Value in kW) = (Percent Value)/(100%) * (Reference Power)For example, if this pa...";
CM_ SG_ 2365287678 MtrGnrtr2InvrtrRfrn1Cr "Motor/Generator 2 Inverter Reference 1 CRC: The CRC is defined as follows: - Length: 8 bits- Polynomial: x^8+x^5+x^3+x^2+x+1- Initial Value: FFh- Input Data Reflection: Not reflected- Result Data Reflection: Not reflected- XOR value: FFh SAE makes no...";
CM_ BO_ 2365287934 "Motor/Generator 2 Inverter Status 1";
CM_ SG_ 2365287934 MtrGnrtr2InvrtrStts1Cntr "Motor/Generator 2 Inverter Status 1 Counter: The message counter is used to detect situations where the transmitting ECU malfunction repeats the same frame all the time. The receiver of the information may use the counter parameter to detect this sit...";
CM_ SG_ 2365287934 MotorGenerator2Speed "Motor/Generator 2 Speed: The measured or estimated motor speed.  This refers to the motor rotor output and excludes any gearbox that may be attached to the motor.   Refer to SPN 10237 [Reference Speed] to convert % to rpm.The motor is generating when...";
CM_ SG_ 2365287934 MtrGnrtr2InvrtrStts1Cr "Motor/Generator 2 Inverter Status 1 CRC: The CRC is defined as follows: - Length: 8 bits- Polynomial: x^8+x^5+x^3+x^2+x+1- Initial Value: FFh- Input Data Reflection: Not reflected- Result Data Reflection: Not reflected- XOR value: FFh SAE makes no cl...";
CM_ SG_ 2365287934 MotorGenerator2Torque "Motor/Generator 2 Torque: The measured or estimated motor torque.  This refers to the motor rotor output and excludes any gearbox that may be attached to the motor.  Refer to SPN 10236 [Reference Torque] to convert % to Nm.The motor is generating whe...";
CM_ SG_ 2365287934 MtrGnrtr2InvrtrDSdCrrnt "Motor/Generator 2 Inverter DC Side Current: This is the DC side current of the inverter.Refer to SPN 10268 [Reference Current] to convert % to Amps.While motoring, the current is defined as positive.  For example, in a hybrid or EV propulsion system,...";
CM_ SG_ 2365287934 MtrGnrtr2InvrtrDSdVltg "Motor/Generator 2 Inverter DC Side Voltage: The measured or estimated DC side voltage.  Refer to SPN 10269 [Reference Voltage] to convert % to Volts.";
CM_ BO_ 2365288190 "Motor/Generator 2 Inverter Reference 2";
CM_ SG_ 2365288190 MtrGnrtr2InvrtrRfrn2Cntr "Motor/Generator 2 Inverter Reference 2 Counter: The message counter is used to detect situations where the transmitting ECU malfunction repeats the same frame all the time. The receiver of the information may use the counter parameter to detect this ...";
CM_ SG_ 2365288190 MtrGnrtr2InvrtrRfrnCrrnt "Motor/Generator 2 Inverter Reference Current: This value is used for converting inverter current in percent to units of Amps (RMS or DC).(Value in Amps) = (Percent Value)/(100%) * (Reference Current)For example, if this parameter has a value of 200 A...";
CM_ SG_ 2365288190 MtrGnrtr2InvrtrRfrnVltg "Motor/Generator 2 Inverter Reference Voltage: This value is used for converting inverter voltage in percent to units of Volts (RMS or DC).(Value in Volts) = (Percent Value)/(100%) * (Reference Voltage)For example, if this parameter has a value of 400...";
CM_ SG_ 2365288190 MtrGnrtr2InvrtrRfrn2Cr "Motor/Generator 2 Inverter Reference 2 CRC: The CRC is defined as follows: - Length: 8 bits- Polynomial: x^8+x^5+x^3+x^2+x+1- Initial Value: FFh- Input Data Reflection: Not reflected- Result Data Reflection: Not reflected- XOR value: FFh SAE makes no...";
CM_ BO_ 2566615038 "Motor/Generator 2 Inverter Temperature";
CM_ SG_ 2566615038 MtrGnrtr2InvrtrTmprtr1 "Motor/Generator 2 Inverter Temperature 1: The exact location of this temperature can be defined by the manufacturer.  It is intended to be located somewhere on the inverter. ";
CM_ SG_ 2566615038 MtrGnrtr2InvrtrTmprtr2 "Motor/Generator 2 Inverter Temperature 2: The exact location of this temperature can be defined by the manufacturer.  It is intended to be located somewhere on the inverter. ";
CM_ SG_ 2566615038 MtrGnrtr2InvrtrTmprtr3 "Motor/Generator 2 Inverter Temperature 3: The exact location of this temperature can be defined by the manufacturer.  It is intended to be located somewhere on the inverter. ";
CM_ SG_ 2566615038 MtrGnrtr2InvrtrTmprtr4 "Motor/Generator 2 Inverter Temperature 4: The exact location of this temperature can be defined by the manufacturer.  It is intended to be located somewhere on the inverter. ";
CM_ SG_ 2566615038 MtrGnrtr2InvrtrTmprtr5 "Motor/Generator 2 Inverter Temperature 5: The exact location of this temperature can be defined by the manufacturer. It is intended to be located somewhere on the inverter.";
CM_ BO_ 2566615294 "Motor/Generator 2 Inverter Motor Temperature";
CM_ SG_ 2566615294 MotorGenerator2Temperature1 "Motor/Generator 2 Temperature 1: The exact location of this temperature can be defined by the manufacturer.  It is intended to located somewhere on the motor.";
CM_ SG_ 2566615294 MotorGenerator2Temperature2 "Motor/Generator 2 Temperature 2: The exact location of this temperature can be defined by the manufacturer.  It is intended to located somewhere on the motor. ";
CM_ SG_ 2566615294 MotorGenerator2Temperature3 "Motor/Generator 2 Temperature 3: The exact location of this temperature can be defined by the manufacturer.  It is intended to located somewhere on the motor. ";
CM_ SG_ 2566615294 MotorGenerator2Temperature4 "Motor/Generator 2 Temperature 4: The exact location of this temperature can be defined by the manufacturer.  It is intended to located somewhere on the motor. ";
CM_ BO_ 2566615550 "Motor/Generator 1 Inverter Motor Temperature";
CM_ SG_ 2566615550 MotorGenerator1Temperature1 "Motor/Generator 1 Temperature 1: The exact location of this temperature can be defined by the manufacturer.  It is intended to located somewhere on the motor.";
CM_ SG_ 2566615550 MotorGenerator1Temperature2 "Motor/Generator 1 Temperature 2: The exact location of this temperature can be defined by the manufacturer.  It is intended to located somewhere on the motor. ";
CM_ SG_ 2566615550 MotorGenerator1Temperature3 "Motor/Generator 1 Temperature 3: The exact location of this temperature can be defined by the manufacturer.  It is intended to located somewhere on the motor. ";
CM_ SG_ 2566615550 MotorGenerator1Temperature4 "Motor/Generator 1 Temperature 4: The exact location of this temperature can be defined by the manufacturer.  It is intended to located somewhere on the motor. ";
CM_ BO_ 2566615806 "Motor/Generator 1 Inverter Temperature";
CM_ SG_ 2566615806 MtrGnrtr1InvrtrTmprtr1 "Motor/Generator 1 Inverter Temperature 1: The exact location of this temperature can be defined by the manufacturer.  It is intended to be located somewhere on the inverter. ";
CM_ SG_ 2566615806 MtrGnrtr1InvrtrTmprtr2 "Motor/Generator 1 Inverter Temperature 2: The exact location of this temperature can be defined by the manufacturer.  It is intended to be located somewhere on the inverter. ";
CM_ SG_ 2566615806 MtrGnrtr1InvrtrTmprtr3 "Motor/Generator 1 Inverter Temperature 3: The exact location of this temperature can be defined by the manufacturer.  It is intended to be located somewhere on the inverter. ";
CM_ SG_ 2566615806 MtrGnrtr1InvrtrTmprtr4 "Motor/Generator 1 Inverter Temperature 4: The exact location of this temperature can be defined by the manufacturer.  It is intended to be located somewhere on the inverter. ";
CM_ SG_ 2566615806 MtrGnrtr1InvrtrTmprtr5 "Motor/Generator 1 Inverter Temperature 5: The exact location of this temperature can be defined by the manufacturer. It is intended to be located somewhere on the inverter.";
CM_ BO_ 2365289470 "Motor/Generator 1 Inverter Reference 2";
CM_ SG_ 2365289470 MtrGnrtr1InvrtrRfrn2Cntr "Motor/Generator 1 Inverter Reference 2 Counter: The message counter is used to detect situations where the transmitting ECU malfunction repeats the same frame all the time. The receiver of the information may use the counter parameter to detect this ...";
CM_ SG_ 2365289470 MtrGnrtr1InvrtrRfrnCrrnt "Motor/Generator 1 Inverter Reference Current: This value is used for converting inverter current in percent to units of Amps (RMS or DC).(Value in Amps) = (Percent Value)/(100%) * (Reference Current)For example, if this parameter has a value of 200 A...";
CM_ SG_ 2365289470 MtrGnrtr1InvrtrRfrnVltg "Motor/Generator 1 Inverter Reference Voltage: This value is used for converting inverter voltage in percent to units of Volts (RMS or DC).(Value in Volts) = (Percent Value)/(100%) * (Reference Voltage)For example, if this parameter has a value of 400...";
CM_ SG_ 2365289470 MtrGnrtr1InvrtrRfrn2Cr "Motor/Generator 1 Inverter Reference 2 CRC: The CRC is defined as follows: - Length: 8 bits- Polynomial: x^8+x^5+x^3+x^2+x+1- Initial Value: FFh- Input Data Reflection: Not reflected- Result Data Reflection: Not reflected- XOR value: FFh SAE makes no...";
CM_ BO_ 2365289726 "Motor/Generator 1 Inverter Status 1";
CM_ SG_ 2365289726 MtrGnrtr1InvrtrStts1Cntr "Motor/Generator 1 Inverter Status 1 Counter: The message counter is used to detect situations where the transmitting ECU malfunction repeats the same frame all the time. The receiver of the information may use the counter parameter to detect this sit...";
CM_ SG_ 2365289726 MotorGenerator1Torque "Motor/Generator 1 Torque: The measured or estimated motor torque.  This refers to the motor rotor output and excludes any gearbox that may be attached to the motor.Refer to SPN 10170 [Reference Torque] to convert % to Nm.The motor is generating when ...";
CM_ SG_ 2365289726 MotorGenerator1Speed "Motor/Generator 1 Speed: The measured or estimated motor speed.  This refers to the motor rotor output and excludes any gearbox that may be attached to the motor.   Refer to SPN 10171 [Reference Speed] to convert % to rpm.";
CM_ SG_ 2365289726 MtrGnrtr1InvrtrStts1Cr "Motor/Generator 1 Inverter Status 1 CRC: The CRC is defined as follows: - Length: 8 bits- Polynomial: x^8+x^5+x^3+x^2+x+1- Initial Value: FFh- Input Data Reflection: Not reflected- Result Data Reflection: Not reflected- XOR value: FFh SAE makes no cl...";
CM_ SG_ 2365289726 MtrGnrtr1InvrtrDSdCrrnt "Motor/Generator 1 Inverter DC Side Current: This is the DC side current of the inverter.Refer to SPN 10202 [Reference Current] to convert % to Amps.While motoring, the current is defined as positive.  For example, in a hybrid or EV propulsion system,...";
CM_ SG_ 2365289726 MtrGnrtr1InvrtrDSdVltg "Motor/Generator 1 Inverter DC Side Voltage: The measured or estimated DC side voltage.  Refer to SPN 10203 [Reference Voltage] to convert % to Volts.";
CM_ BO_ 2365289982 "Motor/Generator 1 Inverter Reference 1";
CM_ SG_ 2365289982 MtrGnrtr1InvrtrRfrn1Cntr "Motor/Generator 1 Inverter Reference 1 Counter: The message counter is used to detect situations where the transmitting ECU malfunction repeats the same frame all the time. The receiver of the information may use the counter parameter to detect this ...";
CM_ SG_ 2365289982 MtrGnrtr1InvrtrRfrnTrq "Motor/Generator 1 Inverter Reference Torque: This value is used for converting torque in percent to units of Nm.Value in Nm = (Percent Value)/(100%) * (Reference Torque)For example, if this parameter has a value of 400 Nm and the percent value is equ...";
CM_ SG_ 2365289982 MtrGnrtr1InvrtrRfrnSpd "Motor/Generator 1 Inverter Reference Speed: This value is used for converting Speed in percent to units of rpm.Value in rpm = (Percent Value)/(100%) * (Reference Speed)For example, if this parameter has a value of 8192 rpm and the percent value is eq...";
CM_ SG_ 2365289982 MtrGnrtr1InvrtrRfrnPwr "Motor/Generator 1 Inverter Reference Power: This value is used for converting power in percent to units of kW.  It is applicable to both mechanical and electrical power.(Value in kW) = (Percent Value)/(100%) * (Reference Power)For example, if this pa...";
CM_ SG_ 2365289982 MtrGnrtr1InvrtrRfrn1Cr "Motor/Generator 1 Inverter Reference 1 CRC: The CRC is defined as follows: - Length: 8 bits- Polynomial: x^8+x^5+x^3+x^2+x+1- Initial Value: FFh- Input Data Reflection: Not reflected- Result Data Reflection: Not reflected- XOR value: FFh SAE makes no...";
CM_ BO_ 2566616830 "Personnel Detect Status";
CM_ SG_ 2566616830 DetectionLocation1 "Detection Location 1: Identifies the location of the detection area associated with Zone Alarm Status 1 (SPN 10134) reported in the message. The detection location identifies a directional area of detection from the vehicle. When the PG contains Zone...";
CM_ SG_ 2566616830 DetectionZone1 "Detection Zone 1: Identifies the detection zone associated with Zone Alarm Status 1 (SPN 10134) reported in the message. A detection zone identifies spatial area within the detection location specified by Detection Location 1 (SPN 13133). When the PG...";
CM_ SG_ 2566616830 ZoneAlarmStatus1 "Zone Alarm Status 1: Indicates the alarm status for detection of personnel within the detection zone identified by Detection Zone 1 (SPN 10132) and Detection Location 1 (SPN 10133).0000b = No Alarm Active0001b = Alarm Active0010b = Reserved for SAE a...";
CM_ SG_ 2566616830 DetectionLocation2 "Detection Location 2: Identifies the location of the detection area associated with Zone Alarm Status 2 (SPN 10137) reported in the message. The detection location identifies a directional area of detection from the vehicle. When the PG contains Zone...";
CM_ SG_ 2566616830 DetectionZone2 "Detection Zone 2: Identifies the detection zone associated with Zone Alarm Status 2 (SPN 10137) reported in the message. A detection zone identifies spatial area within the detection location specified by Detection Location 2 (SPN 10136). When the PG...";
CM_ SG_ 2566616830 ZoneAlarmStatus2 "Zone Alarm Status 2: Indicates the alarm status for detection of personnel within the detection zone identified by Detection Zone 2 (SPN 10135) and Detection Location 2 (SPN 10136).0000b = No Alarm Active0001b = Alarm Active0010b = Reserved for SAE a...";
CM_ SG_ 2566616830 DetectionLocation3 "Detection Location 3: Identifies the location of the detection area associated with Zone Alarm Status 3 (SPN 10140) reported in the message. The detection location identifies a directional area of detection from the vehicle. When the PG contains Zone...";
CM_ SG_ 2566616830 DetectionZone3 "Detection Zone 3: Identifies the detection zone associated with Zone Alarm Status 3 (SPN 10140) reported in the message. A detection zone identifies spatial area within the detection location specified by Detection Location 3 (SPN 10139). When the PG...";
CM_ SG_ 2566616830 ZoneAlarmStatus3 "Zone Alarm Status 3: Indicates the alarm status for detection of personnel within the detection zone identified by Detection Zone 3 (SPN 10138) and Detection Location 3 (SPN 10139).0000b = No Alarm Active0001b = Alarm Active0010b = Reserved for SAE a...";
CM_ SG_ 2566616830 PersonnelDetectSequenceCounter "Personnel Detect Sequence Counter: A counter value which increments per each transmission of data. If Personnel Detect Status consists of multiple messages then each message in the group shall share the same Sequence Counter value.NOTE - The counter ...";
CM_ BO_ 2566617086 "Engine Cylinder Pressure Gamma 1";
CM_ SG_ 2566617086 EngnClndr1CmprssnGmmRt "Engine Cylinder 1 Compression Gamma Ratio: The compression gamma ratio is defined as Log(pressure)/Log(volume) of the cylinder pressure curve during the compression stroke of the current engine cycle for engine cylinder 1.  The SP will report FB00h (...";
CM_ SG_ 2566617086 EngnClndr1ExpnsnGmmRt "Engine Cylinder 1 Expansion Gamma Ratio: The expansion gamma ratio is defined as Log(pressure)/Log(volume) of the cylinder pressure curve during the expansion stroke of the current engine cycle for engine cylinder 1.  The SP will report FB00h (64256)...";
CM_ SG_ 2566617086 EngnClndr2CmprssnGmmRt "Engine Cylinder 2 Compression Gamma Ratio: The compression gamma ratio is defined as Log(pressure)/Log(volume) of the cylinder pressure curve during the compression stroke of the current engine cycle for engine cylinder 2.  The SP will report FB00h (...";
CM_ SG_ 2566617086 EngnClndr2ExpnsnGmmRt "Engine Cylinder 2 Expansion Gamma Ratio: The expansion gamma ratio is defined as Log(pressure)/Log(volume) of the cylinder pressure curve during the expansion stroke of the current engine cycle for engine cylinder 2.  The SP will report FB00h (64256)...";
CM_ SG_ 2566617086 EngnClndr3CmprssnGmmRt "Engine Cylinder 3 Compression Gamma Ratio: The compression gamma ratio is defined as Log(pressure)/Log(volume) of the cylinder pressure curve during the compression stroke of the current engine cycle for engine cylinder 3.  The SP will report FB00h (...";
CM_ SG_ 2566617086 EngnClndr3ExpnsnGmmRt "Engine Cylinder 3 Expansion Gamma Ratio: The expansion gamma ratio is defined as Log(pressure)/Log(volume) of the cylinder pressure curve during the expansion stroke of the current engine cycle for engine cylinder 3.  The SP will report FB00h (64256)...";
CM_ SG_ 2566617086 EngnClndr4CmprssnGmmRt "Engine Cylinder 4 Compression Gamma Ratio: The compression gamma ratio is defined as Log(pressure)/Log(volume) of the cylinder pressure curve during the compression stroke of the current engine cycle for engine cylinder 4.  The SP will report FB00h (...";
CM_ SG_ 2566617086 EngnClndr4ExpnsnGmmRt "Engine Cylinder 4 Expansion Gamma Ratio: The expansion gamma ratio is defined as Log(pressure)/Log(volume) of the cylinder pressure curve during the expansion stroke of the current engine cycle for engine cylinder 4.  The SP will report FB00h (64256)...";
CM_ BO_ 2566617342 "Engine Cylinder Pressure Gamma 2";
CM_ SG_ 2566617342 EngnClndr5CmprssnGmmRt "Engine Cylinder 5 Compression Gamma Ratio: The compression gamma ratio is defined as Log(pressure)/Log(volume) of the cylinder pressure curve during the compression stroke of the current engine cycle for engine Cylinder 5.  The SP will report FB00h (...";
CM_ SG_ 2566617342 EngnClndr5ExpnsnGmmRt "Engine Cylinder 5 Expansion Gamma Ratio: The expansion gamma ratio is defined as Log(pressure)/Log(volume) of the cylinder pressure curve during the expansion stroke of the current engine cycle for engine Cylinder 5.  The SP will report FB00h (64256)...";
CM_ SG_ 2566617342 EngnClndr6CmprssnGmmRt "Engine Cylinder 6 Compression Gamma Ratio: The compression gamma ratio is defined as Log(pressure)/Log(volume) of the cylinder pressure curve during the compression stroke of the current engine cycle for engine Cylinder 6.  The SP will report FB00h (...";
CM_ SG_ 2566617342 EngnClndr6ExpnsnGmmRt "Engine Cylinder 6 Expansion Gamma Ratio: The expansion gamma ratio is defined as Log(pressure)/Log(volume) of the cylinder pressure curve during the expansion stroke of the current engine cycle for engine Cylinder 6.  The SP will report FB00h (64256)...";
CM_ SG_ 2566617342 EngnClndr7CmprssnGmmRt "Engine Cylinder 7 Compression Gamma Ratio: The compression gamma ratio is defined as Log(pressure)/Log(volume) of the cylinder pressure curve during the compression stroke of the current engine cycle for engine Cylinder 7.  The SP will report FB00h (...";
CM_ SG_ 2566617342 EngnClndr7ExpnsnGmmRt "Engine Cylinder 7 Expansion Gamma Ratio: The expansion gamma ratio is defined as Log(pressure)/Log(volume) of the cylinder pressure curve during the expansion stroke of the current engine cycle for engine Cylinder 7.  The SP will report FB00h (64256)...";
CM_ SG_ 2566617342 EngnClndr8CmprssnGmmRt "Engine Cylinder 8 Compression Gamma Ratio: The compression gamma ratio is defined as Log(pressure)/Log(volume) of the cylinder pressure curve during the compression stroke of the current engine cycle for engine Cylinder 8.  The SP will report FB00h (...";
CM_ SG_ 2566617342 EngnClndr8ExpnsnGmmRt "Engine Cylinder 8 Expansion Gamma Ratio: The expansion gamma ratio is defined as Log(pressure)/Log(volume) of the cylinder pressure curve during the expansion stroke of the current engine cycle for engine Cylinder 8.  The SP will report FB00h (64256)...";
CM_ BO_ 2566617598 "Engine Cylinder Pressure Gamma 3";
CM_ SG_ 2566617598 EngnClndr9CmprssnGmmRt "Engine Cylinder 9 Compression Gamma Ratio: The compression gamma ratio is defined as Log(pressure)/Log(volume) of the cylinder pressure curve during the compression stroke of the current engine cycle for engine Cylinder 9.  The SP will report FB00h (...";
CM_ SG_ 2566617598 EngnClndr9ExpnsnGmmRt "Engine Cylinder 9 Expansion Gamma Ratio: The expansion gamma ratio is defined as Log(pressure)/Log(volume) of the cylinder pressure curve during the expansion stroke of the current engine cycle for engine Cylinder 9.  The SP will report FB00h (64256)...";
CM_ SG_ 2566617598 EngnClndr10CmprssnGmmRt "Engine Cylinder 10 Compression Gamma Ratio: The compression gamma ratio is defined as Log(pressure)/Log(volume) of the cylinder pressure curve during the compression stroke of the current engine cycle for engine Cylinder 10.  The SP will report FB00h...";
CM_ SG_ 2566617598 EngnClndr10ExpnsnGmmRt "Engine Cylinder 10 Expansion Gamma Ratio: The expansion gamma ratio is defined as Log(pressure)/Log(volume) of the cylinder pressure curve during the expansion stroke of the current engine cycle for engine Cylinder 10.  The SP will report FB00h (6425...";
CM_ SG_ 2566617598 EngnClndr11CmprssnGmmRt "Engine Cylinder 11 Compression Gamma Ratio: The compression gamma ratio is defined as Log(pressure)/Log(volume) of the cylinder pressure curve during the compression stroke of the current engine cycle for engine Cylinder 11.  The SP will report FB00h...";
CM_ SG_ 2566617598 EngnClndr11ExpnsnGmmRt "Engine Cylinder 11 Expansion Gamma Ratio: The expansion gamma ratio is defined as Log(pressure)/Log(volume) of the cylinder pressure curve during the expansion stroke of the current engine cycle for engine Cylinder 11.  The SP will report FB00h (6425...";
CM_ SG_ 2566617598 EngnClndr12CmprssnGmmRt "Engine Cylinder 12 Compression Gamma Ratio: The compression gamma ratio is defined as Log(pressure)/Log(volume) of the cylinder pressure curve during the compression stroke of the current engine cycle for engine Cylinder 12.  The SP will report FB00h...";
CM_ SG_ 2566617598 EngnClndr12ExpnsnGmmRt "Engine Cylinder 12 Expansion Gamma Ratio: The expansion gamma ratio is defined as Log(pressure)/Log(volume) of the cylinder pressure curve during the expansion stroke of the current engine cycle for engine Cylinder 12.  The SP will report FB00h (6425...";
CM_ BO_ 2566617854 "Engine Cylinder Pressure Gamma 4";
CM_ SG_ 2566617854 EngnClndr13CmprssnGmmRt "Engine Cylinder 13 Compression Gamma Ratio: The compression gamma ratio is defined as Log(pressure)/Log(volume) of the cylinder pressure curve during the compression stroke of the current engine cycle for engine Cylinder 13.  The SP will report FB00h...";
CM_ SG_ 2566617854 EngnClndr13ExpnsnGmmRt "Engine Cylinder 13 Expansion Gamma Ratio: The expansion gamma ratio is defined as Log(pressure)/Log(volume) of the cylinder pressure curve during the expansion stroke of the current engine cycle for engine Cylinder 13.  The SP will report FB00h (6425...";
CM_ SG_ 2566617854 EngnClndr14CmprssnGmmRt "Engine Cylinder 14 Compression Gamma Ratio: The compression gamma ratio is defined as Log(pressure)/Log(volume) of the cylinder pressure curve during the compression stroke of the current engine cycle for engine Cylinder 14.  The SP will report FB00h...";
CM_ SG_ 2566617854 EngnClndr14ExpnsnGmmRt "Engine Cylinder 14 Expansion Gamma Ratio: The expansion gamma ratio is defined as Log(pressure)/Log(volume) of the cylinder pressure curve during the expansion stroke of the current engine cycle for engine Cylinder 14.  The SP will report FB00h (6425...";
CM_ SG_ 2566617854 EngnClndr15CmprssnGmmRt "Engine Cylinder 15 Compression Gamma Ratio: The compression gamma ratio is defined as Log(pressure)/Log(volume) of the cylinder pressure curve during the compression stroke of the current engine cycle for engine Cylinder 15.  The SP will report FB00h...";
CM_ SG_ 2566617854 EngnClndr15ExpnsnGmmRt "Engine Cylinder 15 Expansion Gamma Ratio: The expansion gamma ratio is defined as Log(pressure)/Log(volume) of the cylinder pressure curve during the expansion stroke of the current engine cycle for engine Cylinder 15.  The SP will report FB00h (6425...";
CM_ SG_ 2566617854 EngnClndr16CmprssnGmmRt "Engine Cylinder 16 Compression Gamma Ratio: The compression gamma ratio is defined as Log(pressure)/Log(volume) of the cylinder pressure curve during the compression stroke of the current engine cycle for engine Cylinder 16.  The SP will report FB00h...";
CM_ SG_ 2566617854 EngnClndr16ExpnsnGmmRt "Engine Cylinder 16 Expansion Gamma Ratio: The expansion gamma ratio is defined as Log(pressure)/Log(volume) of the cylinder pressure curve during the expansion stroke of the current engine cycle for engine Cylinder 16.  The SP will report FB00h (6425...";
CM_ BO_ 2566618110 "Engine Cylinder Pressure Gamma 5";
CM_ SG_ 2566618110 EngnClndr17CmprssnGmmRt "Engine Cylinder 17 Compression Gamma Ratio: The compression gamma ratio is defined as Log(pressure)/Log(volume) of the cylinder pressure curve during the compression stroke of the current engine cycle for engine Cylinder 17.  The SP will report FB00h...";
CM_ SG_ 2566618110 EngnClndr17ExpnsnGmmRt "Engine Cylinder 17 Expansion Gamma Ratio: The expansion gamma ratio is defined as Log(pressure)/Log(volume) of the cylinder pressure curve during the expansion stroke of the current engine cycle for engine Cylinder 17.  The SP will report FB00h (6425...";
CM_ SG_ 2566618110 EngnClndr18CmprssnGmmRt "Engine Cylinder 18 Compression Gamma Ratio: The compression gamma ratio is defined as Log(pressure)/Log(volume) of the cylinder pressure curve during the compression stroke of the current engine cycle for engine Cylinder 18.  The SP will report FB00h...";
CM_ SG_ 2566618110 EngnClndr18ExpnsnGmmRt "Engine Cylinder 18 Expansion Gamma Ratio: The expansion gamma ratio is defined as Log(pressure)/Log(volume) of the cylinder pressure curve during the expansion stroke of the current engine cycle for engine Cylinder 18.  The SP will report FB00h (6425...";
CM_ SG_ 2566618110 EngnClndr19CmprssnGmmRt "Engine Cylinder 19 Compression Gamma Ratio: The compression gamma ratio is defined as Log(pressure)/Log(volume) of the cylinder pressure curve during the compression stroke of the current engine cycle for engine Cylinder 19.  The SP will report FB00h...";
CM_ SG_ 2566618110 EngnClndr19ExpnsnGmmRt "Engine Cylinder 19 Expansion Gamma Ratio: The expansion gamma ratio is defined as Log(pressure)/Log(volume) of the cylinder pressure curve during the expansion stroke of the current engine cycle for engine Cylinder 19.  The SP will report FB00h (6425...";
CM_ SG_ 2566618110 EngnClndr20CmprssnGmmRt "Engine Cylinder 20 Compression Gamma Ratio: The compression gamma ratio is defined as Log(pressure)/Log(volume) of the cylinder pressure curve during the compression stroke of the current engine cycle for engine Cylinder 20.  The SP will report FB00h...";
CM_ SG_ 2566618110 EngnClndr20ExpnsnGmmRt "Engine Cylinder 20 Expansion Gamma Ratio: The expansion gamma ratio is defined as Log(pressure)/Log(volume) of the cylinder pressure curve during the expansion stroke of the current engine cycle for engine Cylinder 20.  The SP will report FB00h (6425...";
CM_ BO_ 2566618622 "Electrified Accessory Generator Coolant Pump Status 1";
CM_ SG_ 2566618622 GnrtrClntPmpCntrllrSttsRsnCd "Generator Coolant Pump Controller Status Reason Code: Provides the reason code describing the unique failure of the Generator Coolant Pump system or component.If a detailed reason code is not used by the supporting application, or this reason code is...";
CM_ SG_ 2566618622 GnrtrClntPmpCntrllrCmmndStts "Generator Coolant Pump Controller Command Status: Indicates the source of the speed command to the Generator Coolant Pump system or component.00b is communicated when the controller is self-controlled (e.g. based on a temperature sensor).01b is commu...";
CM_ SG_ 2566618622 GeneratorCoolantPumpMotorSpeed "Generator Coolant Pump Motor Speed: Motor Speed of the Generator Coolant Pump.  This parameter is used with SPN 9833 (Generator Coolant Pump Motor Speed Status)";
CM_ SG_ 2566618622 GnrtrClntPmpCntrlTmprtr "Generator Coolant Pump Control Temperature: A temperature measured and reported by the device.  It may be used for direct or remote (e.g. by another controller) control of the pump.  For example, this may be the temperature of the fluid flowing throu...";
CM_ SG_ 2566618622 GeneratorCoolantPumpPower "Generator Coolant Pump Power: Calculated electrical power consumed by the Generator Coolant Pump.";
CM_ SG_ 2566618622 GnrtrClntPmpSrvIndtr "Generator Coolant Pump Service Indicator: Indicates that service is required for the Generator Coolant Pump system or component.  An active indication may convey a need for component replacement or periodic service.  The Generator Coolant Pump Contro...";
CM_ SG_ 2566618622 GnrtrClntPmpOprtngStts "Generator Coolant Pump Operating Status: Indicates the operating status of the Generator Coolant Pump system or component.  This parameter is used to inform other devices that this system or component is no longer performing to its operational capaci...";
CM_ SG_ 2566618622 GnrtrClntPmpMtrSpdStts "Generator Coolant Pump Motor Speed Status: Enable and direction status of the Generator Coolant Pump system or component.  This parameter is used with SPN 9836 (Generator Coolant Pump Motor Speed).00b = Accessory Motor Off01b = Accessory Motor On - N...";
CM_ BO_ 2566618878 "Electrified Accessory Generator Coolant Fan Status 1";
CM_ SG_ 2566618878 GnrtrClntFnCntrllrSttsRsnCd "Generator Coolant Fan Controller Status Reason Code: Provides the reason code describing the unique failure of this Generator Coolant Fan Motor system or component.If a detailed reason code is not used by the supporting application, or this reason co...";
CM_ SG_ 2566618878 GnrtrClntFnCntrllrCmmndStts "Generator Coolant Fan Controller Command Status: Indicates the source of the speed command to this Generator Coolant Fan system or component.00b is communicated when the controller is self-controlled (e.g. based on a temperature sensor).01b is commun...";
CM_ SG_ 2566618878 GeneratorCoolantFanMotorSpeed "Generator Coolant Fan Motor Speed: Motor Speed of the Generator Coolant Fan.  This parameter is used with SPN 9820 (Generator Coolant Fan Motor Speed Status).";
CM_ SG_ 2566618878 GnrtrClntFnCntrlTmprtr "Generator Coolant Fan Control Temperature: A temperature measured and reported by the device.  It may be used for direct or remote (e.g. by another controller) control of the pump.  For example, this may be the temperature of the fluid flowing throug...";
CM_ SG_ 2566618878 GeneratorCoolantFanPower "Generator Coolant Fan Power: Calculated electrical power consumed by the Generator Coolant Fan.";
CM_ SG_ 2566618878 GnrtrClntFnSrvIndtr "Generator Coolant Fan Service Indicator: Indicates that service is required for the Generator Coolant Fan system or component.  An active indication may convey a need for component replacement or periodic service.  The Generator Coolant Fan Motor Con...";
CM_ SG_ 2566618878 GnrtrClntFnOprtngStts "Generator Coolant Fan Operating Status: Indicates the operating status of the Generator Coolant Fan system or component.  This parameter is used to inform other devices that this system or component is no longer performing to its operational capacity...";
CM_ SG_ 2566618878 GnrtrClntFnMtrSpdStts "Generator Coolant Fan Motor Speed Status: Enable and direction status of this Generator Coolant Fan Motor system or component.  This parameter is used with SPN 9823 (Generator Coolant Fan Motor Speed).00b = Accessory Motor Off01b = Accessory Motor On...";
CM_ BO_ 2566619134 "Well Stimulation Pump System Filter Information";
CM_ SG_ 2566619134 WllStmltnPmpOlFltrDffrntlPrssr "Well Stimulation Pump Oil Filter Differential Pressure: Change in pump gear box oil pressure, measured across the filter, due to the filter and any accumulation of solid or semisolid material on or in the filter. The differential pressure is measured...";
CM_ SG_ 2566619134 WllStmltnPmpOlFltrBpssSwthStts "Well Stimulation Pump Oil Filter Bypass Switch Status: Displays Pump Oil Filter Switch Status00b = Not bypassing01b = Bypassing10b = Error11b = Not available";
CM_ SG_ 2566619134 WllStmltnPmpGrBxOtltOlPrssr "Well Stimulation Pump Gear Box Outlet Oil Pressure: Pump Oil pressure (gage) measured just downstream of oil filter.";
CM_ BO_ 2566619390 "PTO Governor Configuration";
CM_ SG_ 2566619390 MinimumPtoGovernorSetSpeed "Minimum PTO Governor Set Speed: The minimum allowed engine speed (user programmable) in which preprogrammed PTO governor set speeds 1-8 can be set.";
CM_ SG_ 2566619390 MaximumPtoGovernorSetSpeed "Maximum PTO Governor Set Speed: The maximum allowed engine speed (user programmable) in which preprogrammed PTO governor set speeds 1-8 can be set.";
CM_ SG_ 2566619390 PrprgrmmdPtGvrnrStSpd1 "Preprogrammed PTO Governor Set Speed 1: This speed corresponds to the PTO governed speed when PTO Governor State (SPN 976) is equal to Preprogrammed PTO Governor Set Speed 1 (01010b).";
CM_ SG_ 2566619390 PrprgrmmdPtGvrnrStSpd2 "Preprogrammed PTO Governor Set Speed 2: This speed corresponds to the PTO governed speed when PTO Governor State (SPN 976) is equal to Preprogrammed PTO Governor Set Speed 2 (01011b).";
CM_ SG_ 2566619390 PrprgrmmdPtGvrnrStSpd3 "Preprogrammed PTO Governor Set Speed 3: This speed corresponds to the PTO governed speed when PTO Governor State (SPN 976) is equal to Preprogrammed PTO Governor Set Speed 3 (01100b).";
CM_ SG_ 2566619390 PrprgrmmdPtGvrnrStSpd4 "Preprogrammed PTO Governor Set Speed 4: This speed corresponds to the PTO governed speed when PTO Governor State (SPN 976) is equal to Preprogrammed PTO Governor Set Speed 4 (01101b).";
CM_ SG_ 2566619390 PrprgrmmdPtGvrnrStSpd5 "Preprogrammed PTO Governor Set Speed 5: This speed corresponds to the PTO governed speed when PTO Governor State (SPN 976) is equal to Preprogrammed PTO Governor Set Speed 5 (01110b).";
CM_ SG_ 2566619390 PrprgrmmdPtGvrnrStSpd6 "Preprogrammed PTO Governor Set Speed 6: This speed corresponds to the PTO governed speed when PTO Governor State (SPN 976) is equal to Preprogrammed PTO Governor Set Speed 6 (01111b).";
CM_ SG_ 2566619390 PrprgrmmdPtGvrnrStSpd7 "Preprogrammed PTO Governor Set Speed 7: This speed corresponds to the PTO governed speed when PTO Governor State (SPN 976) is equal to Preprogrammed PTO Governor Set Speed 7 (10000b).";
CM_ SG_ 2566619390 PrprgrmmdPtGvrnrStSpd8 "Preprogrammed PTO Governor Set Speed 8: This speed corresponds to the PTO governed speed when PTO Governor State (SPN 976) is equal to Preprogrammed PTO Governor Set Speed 8 (10001b).";
CM_ SG_ 2566619390 PtGvrnrAlrtrOvrrdMxmmSpd "PTO Governor Accelerator Override Maximum Speed: The maximum engine speed allowed while accelerator pedal is overriding the PTO governor.";
CM_ BO_ 2566619646 "On Board Programming 2";
CM_ SG_ 2566619646 OnBrdPrgrmmngInttRqst "On Board Programming Initiate Request: Signal indicating that programming should be initiated. Could come from operator controls or target device. Actual initiation may be subject to, or delayed by, operating conditions or interlocks.00b = On board p...";
CM_ SG_ 2566619646 OnBrdPrgrmmngInttInht "On Board Programming Initiate Inhibit: Indicates that programming is inhibited. Signal should be used by the target to prevent being programmed, or by the operator to decline/cancel programming.00b = Programming is not inhibited01b = Programming is i...";
CM_ SG_ 2566619646 OnBrdPrgrmmngInttEAddrss "On Board Programming Initiate ECU Address: Source address of target device for which on board programming is to be initiated. Source addresses 254 and 255 are not valid.";
CM_ BO_ 2566620670 "Engine Idle Management Information";
CM_ SG_ 2566620670 EngineIdleManagementStatus "Engine Idle Management Status: Indicates the current state or mode of operation by the engine idle manangement system.0000b = Off0001b = Locked0010b = Disabled0011b = Activation conditions not met (Not able to begin or continue due to current engine ...";
CM_ SG_ 2566620670 IdlMngmntPndngEvntTmRmnng "Idle Management Pending Event Time Remaining: Used to indicate the time remaining before the engine will start-up or shutdown as determined by the idle management controller. The time remaining can be used to trigger additional alarms, lamps & displa...";
CM_ SG_ 2566620670 EngnIdlMngmntEngnRstrtRsn "Engine Idle Management Engine Restart Reason: Used to indicate the condition requesting the engine to restart when the idle management system is active.0000b = Operator input request0001b = Low engine coolant temperature0010b = Low SLI battery voltag...";
CM_ SG_ 2566620670 EngnIdlMngmntEngnShtdwnRsn "Engine Idle Management Engine Shutdown Reason: Used to indicate the condition requesting the engine to shutdown when the idle management system is active.When multiple reasons are applicable, it is suggested that precedence be given to states which a...";
CM_ BO_ 2566621438 "Marine Control Information 3";
CM_ SG_ 2566621438 StationThrottlePositionMatch "Station Throttle Position Match: Indicates whether the throttle position at the currently selected station and the throttle lever position at the station where the transfer is occuring is within the correct range to allow the transfer to occur.00b = ...";
CM_ SG_ 2566621438 StationGearPositionMatch "Station Gear Position Match: Indicates whether the gear position at the currently selected station is in neutral and the gear lever position at the station where the transfer is occuring is in neutral in order to allow the transfer to occur.00b = Neu...";
CM_ SG_ 2566621438 OprtrSttnAtvBttnStts "Operator Station Active Button Status: The button used to request a station to become the active station when another station is currently in control.00b = Button not pressed01b = Button pressed10b = Error11b = Not Available";
CM_ SG_ 2566621438 TrollingModeButtonStatus "Trolling Mode Button Status: The button used to change the current type of trolling mode that is selected.00b = Button not pressed01b = Button pressed10b = Error11b = Not Available";
CM_ SG_ 2566621438 EngnThrttlLvrSnhrnztnBttnStts "Engine Throttle Lever Synchronization Button Status: The button that is used to enable or disable syncronization of the engine throttles. When synchronization mode is activated, an operator uses one throttle lever to control the speed of multiple eng...";
CM_ SG_ 2566621438 GearLockoutButtonStatus "Gear Lockout Button Status: This button is used to prevent the transmissions from being shifted into gear. When the button is pressed, the transmissions will be locked in neutral.00b = Button not pressed01b = Button pressed10b = Error11b = Not Availa...";
CM_ SG_ 2566621438 SlowVesselModeButtonStatus "Slow Vessel Mode Button Status: Reports when the slow vessel mode button has been pressed.00b = Button not pressed01b = Button pressed10b = Error11b = Not Available";
CM_ SG_ 2566621438 OperatorStationActiveLampStatus "Operator Station Active Lamp Status: Reports when the operator station active lamp is illuminated.00b = Off01b = On10b = Error11b = Not Available";
CM_ SG_ 2566621438 TrollingModeLampStatus "Trolling Mode Lamp Status: Reports when the trolling mode lamp is illuminated.00b = Off01b = On10b = Error11b = Not Available";
CM_ SG_ 2566621438 EngnThrttlLvrSnhrnztnLmpStts "Engine Throttle Lever Synchronization Lamp Status: Reports when the throttle lever synchronization lamp is illuminated. When synchronization mode is activated, an operator uses one throttle lever to control the speed of multiple engines.00b = Off01b ...";
CM_ SG_ 2566621438 GearLockoutLampStatus "Gear Lockout Lamp Status: Reports when the gear lockout lamp is illuminated.00b = Off01b = On10b = Error11b = Not Available";
CM_ SG_ 2566621438 SlowVesselModeLampStatus "Slow Vessel Mode Lamp Status: Reports when the slow vessel mode lamp is illuminated.00b = Off01b = On10b = Error11b = Not Available";
CM_ SG_ 2566621438 MarineHeavySeaModeEnable "Marine Heavy Sea Mode Enable: Command signal used to indicate that the Marine heavy sea mode is disabled or enabled. Heavy sea mode puts the engine in a control mode to manage heavy sea/ rough water load fluctuations.00b = Marine heavy sea mode is di...";
CM_ BO_ 2566621694 "Engine Fluid Level/Pressure 13";
CM_ SG_ 2566621694 EngineOilPressure2 "Engine Oil Pressure 2: Gage pressure of oil in engine lubrication system as provided by oil pump - second instance.";
CM_ SG_ 2566621694 EngnChrgArClr2OtltPrssr "Engine Charge Air Cooler 2 Outlet Pressure: Measures pressure of air at outlet of second charge air cooler.";
CM_ SG_ 2566621694 EngnChrgArClr1DffrntlPrssr "Engine Charge Air Cooler 1 Differential Pressure: Differential Pressure across the first or only engine charge air cooler.";
CM_ SG_ 2566621694 EngnChrgArClr2DffrntlPrssr "Engine Charge Air Cooler 2 Differential Pressure: Differential Pressure across the second engine charge air cooler.";
CM_ SG_ 2566621694 EngnCrnksBrthrOlSprtrOtltPrssr "Engine Crankcase Breather Oil Separator Outlet Pressure: Indicates the gage pressure of the crankcase breather gases measured at the outlet of crankcase breather oil separator.";
CM_ SG_ 2566621694 EngineOilLevel1State "Engine Oil Level 1 State: First instance of engine oil level switch which indicates if engine oil level is low or normal.See SPN 22723 for the second instance of engine oil level state.00b = Low01b = Normal10b = Error11b = Not available";
CM_ SG_ 2566621694 EngineOilLevel2State "Engine Oil Level 2 State: Second instance of engine oil level switch which indicates if engine oil level is low or normal.See SPN 22722 for the first instance of engine oil level state.00b = Low01b = Normal10b = Error11b = Not available";
CM_ BO_ 2365295358 "High Voltage Energy Storage System Data 11";
CM_ SG_ 2365295358 HvessActualChargeRate "HVESS Actual Charge Rate: This signal represents the actual present charge rate of the High Voltage Energy Storage System (or Pack 1 in systems with only one pack).This parameter provides HVES system level information. If there are multiple packs in ...";
CM_ SG_ 2365295358 HvssBsVltgNgtvTChsssGrndVltg "HVESS Bus Voltage Negative to Chassis Ground Voltage: Voltage difference between the most negative terminal of the HVES battery and chassis measured on the hybrid or EV system bus side (not the battery side) of any HVES contained output contactor.  T...";
CM_ SG_ 2365295358 HvssVltgLvlNgtvTChsssGrndVltg "HVESS Voltage Level Negative to Chassis Ground Voltage: Voltage difference between the most negative terminal of the HVES battery and chassis measured at the battery side of any HVES contained output contactor.  This voltage may be used for system le...";
CM_ SG_ 2365295358 HvssTtlStrdEnrgSrLvl "HVESS Total Stored Energy Source Level: This is the total percentage of the HVES useable capacity, including both online and offline packs. For the capacity of connected packs only, see SPN 7895.   ";
CM_ SG_ 2365295358 HvssPwrMdlEltrnsTmprtr "HVESS Power Module Electronics Temperature: Parameter indicating the temperature of the power module electronics (e.g., DC/DC converter, switch, heatsink) in the HVESS.";
CM_ BO_ 2566622206 "Economy Mode Inactive Hours";
CM_ SG_ 2566622206 EconomyModeTotalHoursInactive "Economy Mode Total Hours Inactive: Total accumulated operating time while economy mode is installed but not in use.";
CM_ SG_ 2566622206 EconomyModeTripHoursInactive "Economy Mode Trip Hours Inactive: Trip operating time accumulated while economy mode is installed but not in use, since last trip reset.";
CM_ BO_ 2566622462 "Economy Mode Estimated Instantaneous Fuel Savings Rate";
CM_ SG_ 2566622462 EnmMdEstmtdInstntnsFlSvngsRt "Economy Mode Estimated Instantaneous Fuel Savings Rate: Estimated instantaneous fuel savings rate while operating in economy mode.  This is in comparison to operating in a non-economy mode.";
CM_ SG_ 2566622462 EMdEsttdIsttsFSvsRtPt "Economy Mode Estimated Instantaneous Fuel Savings Rate Percent: Estimated instantaneous fuel savings rate percentage while operating in economy mode. This value is calculated by dividing Economy Mode Estimated Instantaneous Fuel Savings Percent (SPN ...";
CM_ BO_ 2566622718 "Economy Mode Active Hours";
CM_ SG_ 2566622718 EconomyModeTotalHoursActive "Economy Mode Total Hours Active: Total accumulated operating time in economy mode over the lifetime of the application.";
CM_ SG_ 2566622718 EconomyModeTripHoursActive "Economy Mode Trip Hours Active: Total accumulated operating time in economy mode since the last trip reset.";
CM_ BO_ 2566622974 "Economy Mode Fuel Used";
CM_ SG_ 2566622974 EconomyModeTotalFuelUsed "Economy Mode Total Fuel Used: Total volume of fuel used during economy mode operation over the lifetime of the application.";
CM_ SG_ 2566622974 EconomyModeTripFuelUsed "Economy Mode Trip Fuel Used: Total volume of fuel used during all or part of a journey while operating in economy mode, since the last trip reset.";
CM_ BO_ 2566623230 "Economy Mode Estimated Fuel Savings";
CM_ SG_ 2566623230 EnmMdTtlEstmtdFlSvd "Economy Mode Total Estimated Fuel Saved: Total volume of estimated fuel saved during economy mode of operation over the lifetime of the application. This is in comparison to operating in a non-economy mode.";
CM_ SG_ 2566623230 EnmMdTrpEstmtdFlSvd "Economy Mode Trip Estimated Fuel Saved: Total volume of estimated fuel saved during all or part of a journey while operating in economy mode, since the last trip reset. This is in comparison to operating in a non-economy mode.";
CM_ BO_ 2552823550 "Motor/Generator 1 Inverter Rate Limits Request 1";
CM_ SG_ 2552823550 MtrGnrtr1InvrtrRtLmtsRqst1Cntr "Motor/Generator 1 Inverter Rate Limits Request 1 Counter: The message counter is used to detect situations where the transmitting ECU malfunction repeats the same frame all the time. The receiver of the information may use the counter parameter to de...";
CM_ SG_ 2552823550 MtGt1IvtRtLtsRqstAstSpdRtLt "Motor/Generator 1 Inverter Rate Limits Request Absolute Speed Rate Limit: The maximum rate of change for the absolute motor speed  (i.e. |d(speed)|/dt) in all control modes. This limit shall solely lead to reducing the absolute torque, not increasing...";
CM_ SG_ 2552823550 MtGt1IvtRtLtsRqstAstTqRtLt "Motor/Generator 1 Inverter Rate Limits Request Absolute Torque Rate Limit: The maximum rate of change for the absolute motor torque (i.e. |d(torque)|/dt) in all control modes. Refer to SPN 10170 [Reference Torque] to convert %/sec to Nm/sec. Request ...";
CM_ SG_ 2552823550 MtrGnrtr1InvrtrRtLmtsRqst1Cr "Motor/Generator 1 Inverter Rate Limits Request 1 CRC: The CRC is defined as follows: - Length: 8 bits- Polynomial: x^8+x^5+x^3+x^2+x+1- Initial Value: FFh- Input Data Reflection: Not reflected- Result Data Reflection: Not reflected- XOR value: FFh SA...";
CM_ BO_ 2552889086 "Motor/Generator 2 Inverter Rate Limits Request 1";
CM_ SG_ 2552889086 MtrGnrtr2InvrtrRtLmtsRqst1Cntr "Motor/Generator 2 Inverter Rate Limits Request 1 Counter: The message counter is used to detect situations where the transmitting ECU malfunction repeats the same frame all the time. The receiver of the information may use the counter parameter to de...";
CM_ SG_ 2552889086 MtGt2IvtRtLtsRqstAstSpdRtLt "Motor/Generator 2 Inverter Rate Limits Request Absolute Speed Rate Limit: The maximum rate of change for the absolute motor speed (i.e. |d(speed)|/dt) in all control modes. This limit shall solely lead to reducing the absolute torque, not increasing ...";
CM_ SG_ 2552889086 MtGt2IvtRtLtsRqstAstTqRtLt "Motor/Generator 2 Inverter Rate Limits Request Absolute Torque Rate Limit: The maximum rate of change for the absolute motor torque (i.e. |d(torque)|/dt) in all control modes. Refer to SPN 10236 [Reference Torque] to convert %/sec to Nm/sec. Request ...";
CM_ SG_ 2552889086 MtrGnrtr2InvrtrRtLmtsRqst1Cr "Motor/Generator 2 Inverter Rate Limits Request 1 CRC: The CRC is defined as follows: - Length: 8 bits- Polynomial: x^8+x^5+x^3+x^2+x+1- Initial Value: FFh- Input Data Reflection: Not reflected- Result Data Reflection: Not reflected- XOR value: FFh SA...";
CM_ BO_ 2351628030 "High Voltage Energy Storage Pack 1 Control 1";
CM_ SG_ 2351628030 Hvesp1PowerDownCommand "HVESP1 Power-Down Command: Command to shut down this High Voltage Energy Storage Pack instance.  A normal power-down may involve steps that take some period of time (tests, writing of data, etc.).  However, an emergency power-down should shut down th...";
CM_ SG_ 2351628030 Hvesp1CellBalancingCommand "HVESP1 Cell Balancing Command: Command for this High Voltage Energy Storage Pack instance to perform cell balancing.This parameter is for one of multiple packs in an HVESS.  If there is only one pack in the system, the HVESS parameters should be used...";
CM_ SG_ 2351628030 Hvesp1OperationConsent "HVESP1 Operation Consent: This parameter provides an indication to this High Voltage Energy Storage Pack instance that an external device is ready for this HVES instance to proceed with normal operation.  In applications which support this parameter,...";
CM_ SG_ 2351628030 Hvesp1Control1Counter "HVESP1 Control 1 Counter: The message counter is used to detect situations where the transmitting ECU malfunction repeats the same frame all the time. The receiver of the information may use the counter parameter to detect this situation. The transmi...";
CM_ SG_ 2351628030 Hvesp1Control1Crc "HVESP1 Control 1 CRC: The CRC is defined as follows: - Length: 8 bits- Polynomial: x^8+x^5+x^3+x^2+x+1- Initial Value: FFh- Input Data Reflection: Not reflected- Result Data Reflection: Not reflected- XOR value: FFh SAE makes no claim of the function...";
CM_ SG_ 2351628030 Hvsp1HghVltgBsCnntCmmnd "HVESP1 High-Voltage Bus Connect Command: Command to connect this High Voltage Energy Storage Pack instance to the high-voltage bus.  The emergency contactor closure request may be used in situations where one or more faults in the hybrid or EV powert...";
CM_ SG_ 2351628030 Hvsp1HghVltgBsAtvIsltnTstCmmnd "HVESP1 High-Voltage Bus Active Isolation Test Command: Command for this High Voltage Energy Storage Pack instance to perform an active electrical isolation test on the high voltage bus.An active isolation test might use a generated signal (e.g. an in...";
CM_ SG_ 2351628030 Hvsp1HghVltgBsPssvIsltnTstCmmnd "HVESP1 High-Voltage Bus Passive Isolation Test Command: Command for this High Voltage Energy Storage Pack instance to perform a passive electrical isolation test on the high voltage bus.A passive isolation test uses additional circuitry (e.g. a high ...";
CM_ SG_ 2351628030 Hvsp1EnlIntrnlChrgrCmmnd "HVESP1 Enable Internal Charger Command: When the HVES has an internal charger this parameter will enable it.   External chargers may use the External Energy Source Connection Demand (SPN 7890) and related SPs.This parameter is for one of multiple pac...";
CM_ SG_ 2351628030 Hvsp1HVtBsHSdRsstCtRqst "HVESP1 High-Voltage Bus High Side Resistor Connect Request: This parameter is used to request connection of this HVES instance High-Voltage bus high side resistor in order to perform an isolation test.  See also SPN 11037 (HVESP1 High-Voltage Bus Low...";
CM_ SG_ 2351628030 Hvsp1HghVltgBsLwSdRsstrCnntRqst "HVESP1 High-Voltage Bus Low Side Resistor Connect Request: This parameter is used to request connection of this HVES instance High-Voltage bus low side resistor in order to perform an isolation test.  See also SPN 11036  (HVESP1 High-Voltage Bus High...";
CM_ SG_ 2351628030 Hvsp1ThrmlMngmntMntnnRqst "HVESP1 Thermal Management Maintenance Request: Request to engage Thermal Management Maintenance Mode for this High Voltage Energy Storage System Pack instance.00b = HVESS Thermal Management Maintenance Mode is not requested01b = HVESS Thermal Managem...";
CM_ BO_ 2351693566 "High Voltage Energy Storage Pack 2 Control 1";
CM_ SG_ 2351693566 Hvesp2PowerDownCommand "HVESP2 Power-Down Command: Command to shut down this High Voltage Energy Storage Pack instance.  A normal power-down may involve steps that take some period of time (tests, writing of data, etc.).  However, an emergency power-down should shut down th...";
CM_ SG_ 2351693566 Hvesp2CellBalancingCommand "HVESP2 Cell Balancing Command: Command for this High Voltage Energy Storage Pack instance to perform cell balancing.This parameter is for one of multiple packs in an HVESS.  If there is only one pack in the system, the HVESS parameters should be used...";
CM_ SG_ 2351693566 Hvesp2OperationConsent "HVESP2 Operation Consent: This parameter provides an indication to this High Voltage Energy Storage Pack instance that an external device is ready for this HVES instance to proceed with normal operation.  In applications which support this parameter,...";
CM_ SG_ 2351693566 Hvesp2Control1Counter "HVESP2 Control 1 Counter: The message counter is used to detect situations where the transmitting ECU malfunction repeats the same frame all the time. The receiver of the information may use the counter parameter to detect this situation. The transmi...";
CM_ SG_ 2351693566 Hvesp2Control1Crc "HVESP2 Control 1 CRC: The CRC is defined as follows: - Length: 8 bits- Polynomial: x^8+x^5+x^3+x^2+x+1- Initial Value: FFh- Input Data Reflection: Not reflected- Result Data Reflection: Not reflected- XOR value: FFh SAE makes no claim of the function...";
CM_ SG_ 2351693566 Hvsp2HghVltgBsCnntCmmnd "HVESP2 High-Voltage Bus Connect Command: Command to connect this High Voltage Energy Storage Pack instance to the high-voltage bus.  The emergency contactor closure request may be used in situations where one or more faults in the hybrid or EV powert...";
CM_ SG_ 2351693566 Hvsp2HghVltgBsAtvIsltnTstCmmnd "HVESP2 High-Voltage Bus Active Isolation Test Command: Command for this High Voltage Energy Storage Pack instance to perform an active electrical isolation test on the high voltage bus.An active isolation test might use a generated signal (e.g. an in...";
CM_ SG_ 2351693566 Hvsp2HghVltgBsPssvIsltnTstCmmnd "HVESP2 High-Voltage Bus Passive Isolation Test Command: Command for this High Voltage Energy Storage Pack instance to perform a passive electrical isolation test on the high voltage bus.A passive isolation test uses additional circuitry (e.g. a high ...";
CM_ SG_ 2351693566 Hvsp2EnlIntrnlChrgrCmmnd "HVESP2 Enable Internal Charger Command: When the HVES has an internal charger this parameter will enable it.   External chargers may use the External Energy Source Connection Demand (SPN 7890) and related SPs.This parameter is for one of multiple pac...";
CM_ SG_ 2351693566 Hvsp2HVtBsHSdRsstCtRqst "HVESP2 High-Voltage Bus High Side Resistor Connect Request: This parameter is used to request connection of this HVES instance High-Voltage bus high side resistor in order to perform an isolation test.  See also SPN 11153  (HVESP2 High-Voltage Bus Lo...";
CM_ SG_ 2351693566 Hvsp2HghVltgBsLwSdRsstrCnntRqst "HVESP2 High-Voltage Bus Low Side Resistor Connect Request: This parameter is used to request connection of this HVES instance High-Voltage bus low side resistor in order to perform an isolation test.  See also SPN 11152  (HVESP2 High-Voltage Bus High...";
CM_ SG_ 2351693566 Hvsp2ThrmlMngmntMntnnRqst "HVESP2 Thermal Management Maintenance Request: Request to engage Thermal Management Maintenance Mode for this High Voltage Energy Storage System Pack instance.00b = HVESS Thermal Management Maintenance Mode is not requested01b = HVESS Thermal Managem...";
CM_ BO_ 2351759102 "High Voltage Energy Storage Pack 3 Control 1";
CM_ SG_ 2351759102 Hvesp3PowerDownCommand "HVESP3 Power-Down Command: Command to shut down this High Voltage Energy Storage Pack instance.  A normal power-down may involve steps that take some period of time (tests, writing of data, etc.).  However, an emergency power-down should shut down th...";
CM_ SG_ 2351759102 Hvesp3CellBalancingCommand "HVESP3 Cell Balancing Command: Command for this High Voltage Energy Storage Pack instance to perform cell balancing.This parameter is for one of multiple packs in an HVESS.  If there is only one pack in the system, the HVESS parameters should be used...";
CM_ SG_ 2351759102 Hvesp3OperationConsent "HVESP3 Operation Consent: This parameter provides an indication to this High Voltage Energy Storage Pack instance that an external device is ready for this HVES instance to proceed with normal operation.  In applications which support this parameter,...";
CM_ SG_ 2351759102 Hvesp3Control1Counter "HVESP3 Control 1 Counter: The message counter is used to detect situations where the transmitting ECU malfunction repeats the same frame all the time. The receiver of the information may use the counter parameter to detect this situation. The transmi...";
CM_ SG_ 2351759102 Hvesp3Control1Crc "HVESP3 Control 1 CRC: The CRC is defined as follows: - Length: 8 bits- Polynomial: x^8+x^5+x^3+x^2+x+1- Initial Value: FFh- Input Data Reflection: Not reflected- Result Data Reflection: Not reflected- XOR value: FFh SAE makes no claim of the function...";
CM_ SG_ 2351759102 Hvsp3HghVltgBsCnntCmmnd "HVESP3 High-Voltage Bus Connect Command: Command to connect this High Voltage Energy Storage Pack instance to the high-voltage bus.  The emergency contactor closure request may be used in situations where one or more faults in the hybrid or EV powert...";
CM_ SG_ 2351759102 Hvsp3HghVltgBsAtvIsltnTstCmmnd "HVESP3 High-Voltage Bus Active Isolation Test Command: Command for this High Voltage Energy Storage Pack instance to perform an active electrical isolation test on the high voltage bus.An active isolation test might use a generated signal (e.g. an in...";
CM_ SG_ 2351759102 Hvsp3HghVltgBsPssvIsltnTstCmmnd "HVESP3 High-Voltage Bus Passive Isolation Test Command: Command for this High Voltage Energy Storage Pack instance to perform a passive electrical isolation test on the high voltage bus.A passive isolation test uses additional circuitry (e.g. a high ...";
CM_ SG_ 2351759102 Hvsp3EnlIntrnlChrgrCmmnd "HVESP3 Enable Internal Charger Command: When the HVES has an internal charger this parameter will enable it.   External chargers may use the External Energy Source Connection Demand (SPN 7890) and related SPs.This parameter is for one of multiple pac...";
CM_ SG_ 2351759102 Hvsp3HVtBsHSdRsstCtRqst "HVESP3 High-Voltage Bus High Side Resistor Connect Request: This parameter is used to request connection of this HVES instance High-Voltage bus high side resistor in order to perform an isolation test.  See also SPN 11269  (HVESP3 High-Voltage Bus Lo...";
CM_ SG_ 2351759102 Hvsp3HghVltgBsLwSdRsstrCnntRqst "HVESP3 High-Voltage Bus Low Side Resistor Connect Request: This parameter is used to request connection of this HVES instance High-Voltage bus low side resistor in order to perform an isolation test.  See also SPN 11268  (HVESP3 High-Voltage Bus High...";
CM_ SG_ 2351759102 Hvsp3ThrmlMngmntMntnnRqst "HVESP3 Thermal Management Maintenance Request: Request to engage Thermal Management Maintenance Mode for this High Voltage Energy Storage System Pack instance.00b = HVESS Thermal Management Maintenance Mode is not requested01b = HVESS Thermal Managem...";
BA_DEF_ SG_  "SPN" INT 0 524287;
BA_DEF_ BO_  "VFrameFormat" ENUM  "StandardCAN","ExtendedCAN","reserved","J1939PG";
BA_DEF_DEF_  "SPN" 0;
BA_DEF_DEF_  "VFrameFormat" "J1939PG";
BA_ "SPN" SG_ 2364626430 EngineCylinder17Timing1Pressure 9917;
BA_ "SPN" SG_ 2364626430 EngineCylinder17Timing2Pressure 9918;
BA_ "SPN" SG_ 2364626430 EngineCylinder17Timing3Pressure 9919;
BA_ "SPN" SG_ 2364626430 EngineCylinder17Timing4Pressure 9920;
BA_ "SPN" SG_ 2364626686 EngineCylinder18Timing1Pressure 9921;
BA_ "SPN" SG_ 2364626686 EngineCylinder18Timing2Pressure 9922;
BA_ "SPN" SG_ 2364626686 EngineCylinder18Timing3Pressure 9923;
BA_ "SPN" SG_ 2364626686 EngineCylinder18Timing4Pressure 9924;
BA_ "SPN" SG_ 2364626942 EngineCylinder19Timing1Pressure 9925;
BA_ "SPN" SG_ 2364626942 EngineCylinder19Timing2Pressure 9926;
BA_ "SPN" SG_ 2364626942 EngineCylinder19Timing3Pressure 9927;
BA_ "SPN" SG_ 2364626942 EngineCylinder19Timing4Pressure 9928;
BA_ "SPN" SG_ 2364627198 EngineCylinder20Timing1Pressure 9929;
BA_ "SPN" SG_ 2364627198 EngineCylinder20Timing2Pressure 9930;
BA_ "SPN" SG_ 2364627198 EngineCylinder20Timing3Pressure 9931;
BA_ "SPN" SG_ 2364627198 EngineCylinder20Timing4Pressure 9932;
BA_ "SPN" SG_ 2364627454 EngnClndr1InstntnsCmstnTmngPnt1 9939;
BA_ "SPN" SG_ 2364627454 EngnClndr1InstntnsCmstnTmngPnt2 9940;
BA_ "SPN" SG_ 2364627454 ECd1IsttsSttOCstT 9937;
BA_ "SPN" SG_ 2364627454 ECd1IsttsCtOCstT 9938;
BA_ "SPN" SG_ 2364627710 EngnClndr2InstntnsCmstnTmngPnt1 9943;
BA_ "SPN" SG_ 2364627710 EngnClndr2InstntnsCmstnTmngPnt2 9944;
BA_ "SPN" SG_ 2364627710 ECd2IsttsSttOCstT 9941;
BA_ "SPN" SG_ 2364627710 ECd2IsttsCtOCstT 9942;
BA_ "SPN" SG_ 2364627966 EngnClndr3InstntnsCmstnTmngPnt1 9947;
BA_ "SPN" SG_ 2364627966 EngnClndr3InstntnsCmstnTmngPnt2 9948;
BA_ "SPN" SG_ 2364627966 ECd3IsttsSttOCstT 9945;
BA_ "SPN" SG_ 2364627966 ECd3IsttsCtOCstT 9946;
BA_ "SPN" SG_ 2364628222 EngnClndr4InstntnsCmstnTmngPnt1 9951;
BA_ "SPN" SG_ 2364628222 EngnClndr4InstntnsCmstnTmngPnt2 9952;
BA_ "SPN" SG_ 2364628222 ECd4IsttsSttOCstT 9949;
BA_ "SPN" SG_ 2364628222 ECd4IsttsCtOCstT 9950;
BA_ "SPN" SG_ 2364628478 EngnClndr5InstntnsCmstnTmngPnt1 9955;
BA_ "SPN" SG_ 2364628478 EngnClndr5InstntnsCmstnTmngPnt2 9956;
BA_ "SPN" SG_ 2364628478 ECd5IsttsSttOCstT 9953;
BA_ "SPN" SG_ 2364628478 ECd5IsttsCtOCstT 9954;
BA_ "SPN" SG_ 2364628734 EngnClndr6InstntnsCmstnTmngPnt1 9959;
BA_ "SPN" SG_ 2364628734 EngnClndr6InstntnsCmstnTmngPnt2 9960;
BA_ "SPN" SG_ 2364628734 ECd6IsttsSttOCstT 9957;
BA_ "SPN" SG_ 2364628734 ECd6IsttsCtOCstT 9958;
BA_ "SPN" SG_ 2364628990 EngnClndr7InstntnsCmstnTmngPnt1 9963;
BA_ "SPN" SG_ 2364628990 EngnClndr7InstntnsCmstnTmngPnt2 9964;
BA_ "SPN" SG_ 2364628990 ECd7IsttsSttOCstT 9961;
BA_ "SPN" SG_ 2364628990 ECd7IsttsCtOCstT 9962;
BA_ "SPN" SG_ 2364629246 EngnClndr8InstntnsCmstnTmngPnt1 9967;
BA_ "SPN" SG_ 2364629246 EngnClndr8InstntnsCmstnTmngPnt2 9968;
BA_ "SPN" SG_ 2364629246 ECd8IsttsSttOCstT 9965;
BA_ "SPN" SG_ 2364629246 ECd8IsttsCtOCstT 9966;
BA_ "SPN" SG_ 2364629502 EngnClndr9InstntnsCmstnTmngPnt1 9971;
BA_ "SPN" SG_ 2364629502 EngnClndr9InstntnsCmstnTmngPnt2 9972;
BA_ "SPN" SG_ 2364629502 ECd9IsttsSttOCstT 9969;
BA_ "SPN" SG_ 2364629502 ECd9IsttsCtOCstT 9970;
BA_ "SPN" SG_ 2364629758 ECd10IsttsCstTPt1 9975;
BA_ "SPN" SG_ 2364629758 ECd10IsttsCstTPt2 9976;
BA_ "SPN" SG_ 2364629758 ECd10IsttsSttOCstT 9973;
BA_ "SPN" SG_ 2364629758 ECd10IsttsCtOCstT 9974;
BA_ "SPN" SG_ 2364630014 ECd11IsttsCstTPt1 9979;
BA_ "SPN" SG_ 2364630014 ECd11IsttsCstTPt2 9980;
BA_ "SPN" SG_ 2364630014 ECd11IsttsSttOCstT 9977;
BA_ "SPN" SG_ 2364630014 ECd11IsttsCtOCstT 9978;
BA_ "SPN" SG_ 2364630270 ECd12IsttsCstTPt1 9983;
BA_ "SPN" SG_ 2364630270 ECd12IsttsCstTPt2 9984;
BA_ "SPN" SG_ 2364630270 ECd12IsttsSttOCstT 9981;
BA_ "SPN" SG_ 2364630270 ECd12IsttsCtOCstT 9982;
BA_ "SPN" SG_ 2364630526 ECd13IsttsCstTPt1 9987;
BA_ "SPN" SG_ 2364630526 ECd13IsttsCstTPt2 9988;
BA_ "SPN" SG_ 2364630526 ECd13IsttsSttOCstT 9985;
BA_ "SPN" SG_ 2364630526 ECd13IsttsCtOCstT 9986;
BA_ "SPN" SG_ 2364630782 ECd14IsttsCstTPt1 9991;
BA_ "SPN" SG_ 2364630782 ECd14IsttsCstTPt2 9992;
BA_ "SPN" SG_ 2364630782 ECd14IsttsSttOCstT 9989;
BA_ "SPN" SG_ 2364630782 ECd14IsttsCtOCstT 9990;
BA_ "SPN" SG_ 2364631038 ECd15IsttsCstTPt1 9995;
BA_ "SPN" SG_ 2364631038 ECd15IsttsCstTPt2 9996;
BA_ "SPN" SG_ 2364631038 ECd15IsttsSttOCstT 9993;
BA_ "SPN" SG_ 2364631038 ECd15IsttsCtOCstT 9994;
BA_ "SPN" SG_ 2364631294 ECd16IsttsCstTPt1 9999;
BA_ "SPN" SG_ 2364631294 ECd16IsttsCstTPt2 10000;
BA_ "SPN" SG_ 2364631294 ECd16IsttsSttOCstT 9997;
BA_ "SPN" SG_ 2364631294 ECd16IsttsCtOCstT 9998;
BA_ "SPN" SG_ 2364631550 ECd17IsttsCstTPt1 10003;
BA_ "SPN" SG_ 2364631550 ECd17IsttsCstTPt2 10004;
BA_ "SPN" SG_ 2364631550 ECd17IsttsSttOCstT 10001;
BA_ "SPN" SG_ 2364631550 ECd17IsttsCtOCstT 10002;
BA_ "SPN" SG_ 2364631806 ECd18IsttsCstTPt1 10007;
BA_ "SPN" SG_ 2364631806 ECd18IsttsCstTPt2 10008;
BA_ "SPN" SG_ 2364631806 ECd18IsttsSttOCstT 10005;
BA_ "SPN" SG_ 2364631806 ECd18IsttsCtOCstT 10006;
BA_ "SPN" SG_ 2364632062 ECd19IsttsCstTPt1 10011;
BA_ "SPN" SG_ 2364632062 ECd19IsttsCstTPt2 10012;
BA_ "SPN" SG_ 2364632062 ECd19IsttsSttOCstT 10009;
BA_ "SPN" SG_ 2364632062 ECd19IsttsCtOCstT 10010;
BA_ "SPN" SG_ 2364632318 ECd20IsttsCstTPt1 10015;
BA_ "SPN" SG_ 2364632318 ECd20IsttsCstTPt2 10016;
BA_ "SPN" SG_ 2364632318 ECd20IsttsSttOCstT 10013;
BA_ "SPN" SG_ 2364632318 ECd20IsttsCtOCstT 10014;
BA_ "SPN" SG_ 2364632574 ECd1IsttsPCstPssT 10017;
BA_ "SPN" SG_ 2364632574 ECd1IsttsIdtdMEtvPss 10018;
BA_ "SPN" SG_ 2364632574 EngineCylinder1MisfireRate 1323;
BA_ "SPN" SG_ 2364632574 EngineCylinder1Temperature 10739;
BA_ "SPN" SG_ 2364632574 ECd1IdtdMEtvPssCtOV 10019;
BA_ "SPN" SG_ 2364632830 ECd2IsttsPCstPssT 10020;
BA_ "SPN" SG_ 2364632830 ECd2IsttsIdtdMEtvPss 10021;
BA_ "SPN" SG_ 2364632830 EngineCylinder2MisfireRate 1324;
BA_ "SPN" SG_ 2364632830 EngineCylinder2Temperature 10740;
BA_ "SPN" SG_ 2364632830 ECd2IdtdMEtvPssCtOV 10022;
BA_ "SPN" SG_ 2364633086 ECd3IsttsPCstPssT 10023;
BA_ "SPN" SG_ 2364633086 ECd3IsttsIdtdMEtvPss 10024;
BA_ "SPN" SG_ 2364633086 EngineCylinder3MisfireRate 1325;
BA_ "SPN" SG_ 2364633086 EngineCylinder3Temperature 10741;
BA_ "SPN" SG_ 2364633086 ECd3IdtdMEtvPssCtOV 10025;
BA_ "SPN" SG_ 2364633342 ECd4IsttsPCstPssT 10026;
BA_ "SPN" SG_ 2364633342 ECd4IsttsIdtdMEtvPss 10027;
BA_ "SPN" SG_ 2364633342 EngineCylinder4MisfireRate 1326;
BA_ "SPN" SG_ 2364633342 EngineCylinder4Temperature 10742;
BA_ "SPN" SG_ 2364633342 ECd4IdtdMEtvPssCtOV 10028;
BA_ "SPN" SG_ 2364633598 ECd5IsttsPCstPssT 10029;
BA_ "SPN" SG_ 2364633598 ECd5IsttsIdtdMEtvPss 10030;
BA_ "SPN" SG_ 2364633598 EngineCylinder5MisfireRate 1327;
BA_ "SPN" SG_ 2364633598 EngineCylinder5Temperature 10743;
BA_ "SPN" SG_ 2364633598 ECd5IdtdMEtvPssCtOV 10031;
BA_ "SPN" SG_ 2364633854 ECd6IsttsPCstPssT 10032;
BA_ "SPN" SG_ 2364633854 ECd6IsttsIdtdMEtvPss 10033;
BA_ "SPN" SG_ 2364633854 EngineCylinder6MisfireRate 1328;
BA_ "SPN" SG_ 2364633854 EngineCylinder6Temperature 10744;
BA_ "SPN" SG_ 2364633854 ECd6IdtdMEtvPssCtOV 10034;
BA_ "SPN" SG_ 2364634110 ECd7IsttsPCstPssT 10035;
BA_ "SPN" SG_ 2364634110 ECd7IsttsIdtdMEtvPss 10036;
BA_ "SPN" SG_ 2364634110 EngineCylinder7MisfireRate 1329;
BA_ "SPN" SG_ 2364634110 EngineCylinder7Temperature 10745;
BA_ "SPN" SG_ 2364634110 ECd7IdtdMEtvPssCtOV 10037;
BA_ "SPN" SG_ 2364634366 ECd8IsttsPCstPssT 10038;
BA_ "SPN" SG_ 2364634366 ECd8IsttsIdtdMEtvPss 10039;
BA_ "SPN" SG_ 2364634366 EngineCylinder8MisfireRate 1330;
BA_ "SPN" SG_ 2364634366 EngineCylinder8Temperature 10746;
BA_ "SPN" SG_ 2364634366 ECd8IdtdMEtvPssCtOV 10040;
BA_ "SPN" SG_ 2364634622 ECd9IsttsPCstPssT 10041;
BA_ "SPN" SG_ 2364634622 ECd9IsttsIdtdMEtvPss 10042;
BA_ "SPN" SG_ 2364634622 EngineCylinder9MisfireRate 1331;
BA_ "SPN" SG_ 2364634622 EngineCylinder9Temperature 10747;
BA_ "SPN" SG_ 2364634622 ECd9IdtdMEtvPssCtOV 10043;
BA_ "SPN" SG_ 2364634878 ECd10IsttsPCstPssT 10044;
BA_ "SPN" SG_ 2364634878 ECd10IsttsIdtdMEtvPss 10045;
BA_ "SPN" SG_ 2364634878 EngineCylinder10MisfireRate 1332;
BA_ "SPN" SG_ 2364634878 EngineCylinder10Temperature 10748;
BA_ "SPN" SG_ 2364634878 ECd10IdtdMEtvPssCtOV 10046;
BA_ "SPN" SG_ 2364635134 ECd11IsttsPCstPssT 10047;
BA_ "SPN" SG_ 2364635134 ECd11IsttsIdtdMEtvPss 10048;
BA_ "SPN" SG_ 2364635134 EngineCylinder11MisfireRate 1333;
BA_ "SPN" SG_ 2364635134 EngineCylinder11Temperature 10749;
BA_ "SPN" SG_ 2364635134 ECd11IdtdMEtvPssCtOV 10049;
BA_ "SPN" SG_ 2364635390 ECd12IsttsPCstPssT 10050;
BA_ "SPN" SG_ 2364635390 ECd12IsttsIdtdMEtvPss 10051;
BA_ "SPN" SG_ 2364635390 EngineCylinder12MisfireRate 1334;
BA_ "SPN" SG_ 2364635390 EngineCylinder12Temperature 10750;
BA_ "SPN" SG_ 2364635390 ECd12IdtdMEtvPssCtOV 10052;
BA_ "SPN" SG_ 2364635646 ECd13IsttsPCstPssT 10053;
BA_ "SPN" SG_ 2364635646 ECd13IsttsIdtdMEtvPss 10054;
BA_ "SPN" SG_ 2364635646 EngineCylinder13MisfireRate 1335;
BA_ "SPN" SG_ 2364635646 EngineCylinder13Temperature 10751;
BA_ "SPN" SG_ 2364635646 ECd13IdtdMEtvPssCtOV 10055;
BA_ "SPN" SG_ 2364635902 ECd14IsttsPCstPssT 10056;
BA_ "SPN" SG_ 2364635902 ECd14IsttsIdtdMEtvPss 10057;
BA_ "SPN" SG_ 2364635902 EngineCylinder14MisfireRate 1336;
BA_ "SPN" SG_ 2364635902 EngineCylinder14Temperature 10752;
BA_ "SPN" SG_ 2364635902 ECd14IdtdMEtvPssCtOV 10058;
BA_ "SPN" SG_ 2364636158 ECd15IsttsPCstPssT 10059;
BA_ "SPN" SG_ 2364636158 ECd15IsttsIdtdMEtvPss 10060;
BA_ "SPN" SG_ 2364636158 EngineCylinder15MisfireRate 1337;
BA_ "SPN" SG_ 2364636158 EngineCylinder15Temperature 10753;
BA_ "SPN" SG_ 2364636158 ECd15IdtdMEtvPssCtOV 10061;
BA_ "SPN" SG_ 2364636414 ECd16IsttsPCstPssT 10062;
BA_ "SPN" SG_ 2364636414 ECd16IsttsIdtdMEtvPss 10063;
BA_ "SPN" SG_ 2364636414 EngineCylinder16MisfireRate 1338;
BA_ "SPN" SG_ 2364636414 EngineCylinder16Temperature 10754;
BA_ "SPN" SG_ 2364636414 ECd16IdtdMEtvPssCtOV 10064;
BA_ "SPN" SG_ 2364636670 ECd17IsttsPCstPssT 10065;
BA_ "SPN" SG_ 2364636670 ECd17IsttsIdtdMEtvPss 10066;
BA_ "SPN" SG_ 2364636670 EngineCylinder17MisfireRate 1339;
BA_ "SPN" SG_ 2364636670 EngineCylinder17Temperature 10755;
BA_ "SPN" SG_ 2364636670 ECd17IdtdMEtvPssCtOV 10067;
BA_ "SPN" SG_ 2364636926 ECd18IsttsPCstPssT 10068;
BA_ "SPN" SG_ 2364636926 ECd18IsttsIdtdMEtvPss 10069;
BA_ "SPN" SG_ 2364636926 EngineCylinder18MisfireRate 1340;
BA_ "SPN" SG_ 2364636926 EngineCylinder18Temperature 10756;
BA_ "SPN" SG_ 2364636926 ECd18IdtdMEtvPssCtOV 10070;
BA_ "SPN" SG_ 2364637182 ECd19IsttsPCstPssT 10071;
BA_ "SPN" SG_ 2364637182 ECd19IsttsIdtdMEtvPss 10072;
BA_ "SPN" SG_ 2364637182 EngineCylinder19MisfireRate 1341;
BA_ "SPN" SG_ 2364637182 EngineCylinder19Temperature 10757;
BA_ "SPN" SG_ 2364637182 ECd19IdtdMEtvPssCtOV 10073;
BA_ "SPN" SG_ 2364637438 ECd20IsttsPCstPssT 10074;
BA_ "SPN" SG_ 2364637438 ECd20IsttsIdtdMEtvPss 10075;
BA_ "SPN" SG_ 2364637438 EngineCylinder20MisfireRate 1342;
BA_ "SPN" SG_ 2364637438 EngineCylinder20Temperature 10758;
BA_ "SPN" SG_ 2364637438 ECd20IdtdMEtvPssCtOV 10076;
BA_ "SPN" SG_ 2364637694 MtrGnrtr1InvrtrMdFdk1Cntr 10165;
BA_ "SPN" SG_ 2364637694 MtrGnrtr1InvrtrCntrlLmtsOvrrdMd 10166;
BA_ "SPN" SG_ 2364637694 MtrGnrtr1InvrtrCntrlStpntMd 10167;
BA_ "SPN" SG_ 2364637694 MtrGnrtr1InvrtrMdFdk1Cr 10164;
BA_ "SPN" SG_ 2364637694 MtrGnrtr1InvrtrHvlStts 9103;
BA_ "SPN" SG_ 2565964542 MtrGnrtr1InvrtrLmtsAtvPwrCntr 10183;
BA_ "SPN" SG_ 2565964542 MtrGnrtr1InvrtrLmtsAtvPwrCr 10182;
BA_ "SPN" SG_ 2565964542 MtGt1IvtLtsAtvMPwMx 10184;
BA_ "SPN" SG_ 2565964542 MtGt1IvtLtsAtvMPwM 10185;
BA_ "SPN" SG_ 2565964542 MtGt1IvtLtsAtvDSdPwMx 10186;
BA_ "SPN" SG_ 2565964542 MtGt1IvtLtsAtvDSdPwM 10187;
BA_ "SPN" SG_ 2565964798 MtrGnrtr1InvrtrLmtsAtvMhnlCntr 10195;
BA_ "SPN" SG_ 2565964798 MtrGnrtr1InvrtrLmtsAtvMhnlCr 10194;
BA_ "SPN" SG_ 2565964798 MtrGnrtr1InvrtrLmtsAtvTrqMxmm 10196;
BA_ "SPN" SG_ 2565964798 MtrGnrtr1InvrtrLmtsAtvTrqMnmm 10197;
BA_ "SPN" SG_ 2565964798 MtrGnrtr1InvrtrLmtsAtvSpdMxmm 10198;
BA_ "SPN" SG_ 2565964798 MtrGnrtr1InvrtrLmtsAtvSpdMnmm 10199;
BA_ "SPN" SG_ 2565965054 MtrGnrtr1InvrtrLmtsAtvDSdCr 10210;
BA_ "SPN" SG_ 2565965054 MtrGnrtr1InvrtrLmtsAtvDSdCntr 10211;
BA_ "SPN" SG_ 2565965054 MtGt1IvtLtsAtvDSdVtMx 10212;
BA_ "SPN" SG_ 2565965054 MtGt1IvtLtsAtvDSdVtM 10213;
BA_ "SPN" SG_ 2565965054 MtGt1IvtLtsAtvDSdCtMx 10214;
BA_ "SPN" SG_ 2565965054 MtGt1IvtLtsAtvDSdCtM 10215;
BA_ "SPN" SG_ 2565965310 MtrGnrtr1InvrtrSwthdIgntnVltg 9105;
BA_ "SPN" SG_ 2565965310 MtrGnrtr1InvrtrUnswthdSlVltg 9117;
BA_ "SPN" SG_ 2364638974 MtrGnrtr2InvrtrMdFdk1Cntr 10231;
BA_ "SPN" SG_ 2364638974 MtrGnrtr2InvrtrCntrlLmtsOvrrdMd 10232;
BA_ "SPN" SG_ 2364638974 MtrGnrtr2InvrtrCntrlStpntMd 10233;
BA_ "SPN" SG_ 2364638974 MtrGnrtr2InvrtrMdFdk1Cr 10230;
BA_ "SPN" SG_ 2364638974 MtrGnrtr2InvrtrHvlStts 9104;
BA_ "SPN" SG_ 2565965822 MtrGnrtr2InvrtrLmtsAtvPwrCntr 10249;
BA_ "SPN" SG_ 2565965822 MtrGnrtr2InvrtrLmtsAtvPwrCr 10248;
BA_ "SPN" SG_ 2565965822 MtGt2IvtLtsAtvMPwMx 10250;
BA_ "SPN" SG_ 2565965822 MtGt2IvtLtsAtvMPwM 10251;
BA_ "SPN" SG_ 2565965822 MtGt2IvtLtsAtvDSdPwMx 10252;
BA_ "SPN" SG_ 2565965822 MtGt2IvtLtsAtvDSdPwM 10253;
BA_ "SPN" SG_ 2565966078 MtrGnrtr2InvrtrLmtsAtvMhnlCntr 10261;
BA_ "SPN" SG_ 2565966078 MtrGnrtr2InvrtrLmtsAtvMhnlCr 10260;
BA_ "SPN" SG_ 2565966078 MtrGnrtr2InvrtrLmtsAtvTrqMxmm 10262;
BA_ "SPN" SG_ 2565966078 MtrGnrtr2InvrtrLmtsAtvTrqMnmm 10263;
BA_ "SPN" SG_ 2565966078 MtrGnrtr2InvrtrLmtsAtvSpdMxmm 10264;
BA_ "SPN" SG_ 2565966078 MtrGnrtr2InvrtrLmtsAtvSpdMnmm 10265;
BA_ "SPN" SG_ 2565966334 MtrGnrtr2InvrtrLmtsAtvDSdCr 10276;
BA_ "SPN" SG_ 2565966334 MtrGnrtr2InvrtrLmtsAtvDSdCntr 10277;
BA_ "SPN" SG_ 2565966334 MtGt2IvtLtsAtvDSdVtMx 10278;
BA_ "SPN" SG_ 2565966334 MtGt2IvtLtsAtvDSdVtM 10279;
BA_ "SPN" SG_ 2565966334 MtGt2IvtLtsAtvDSdCtMx 10280;
BA_ "SPN" SG_ 2565966334 MtGt2IvtLtsAtvDSdCtM 10281;
BA_ "SPN" SG_ 2565966590 MtrGnrtr2InvrtrSwthdIgntnVltg 9106;
BA_ "SPN" SG_ 2565966590 MtrGnrtr2InvrtrUnswthdSlVltg 9118;
BA_ "SPN" SG_ 2365287678 MtrGnrtr2InvrtrRfrn1Cntr 10235;
BA_ "SPN" SG_ 2365287678 MtrGnrtr2InvrtrRfrnTrq 10236;
BA_ "SPN" SG_ 2365287678 MtrGnrtr2InvrtrRfrnSpd 10237;
BA_ "SPN" SG_ 2365287678 MtrGnrtr2InvrtrRfrnPwr 10238;
BA_ "SPN" SG_ 2365287678 MtrGnrtr2InvrtrRfrn1Cr 10234;
BA_ "SPN" SG_ 2365287934 MtrGnrtr2InvrtrStts1Cntr 10240;
BA_ "SPN" SG_ 2365287934 MotorGenerator2Speed 9058;
BA_ "SPN" SG_ 2365287934 MtrGnrtr2InvrtrStts1Cr 10239;
BA_ "SPN" SG_ 2365287934 MotorGenerator2Torque 9062;
BA_ "SPN" SG_ 2365287934 MtrGnrtr2InvrtrDSdCrrnt 10241;
BA_ "SPN" SG_ 2365287934 MtrGnrtr2InvrtrDSdVltg 9102;
BA_ "SPN" SG_ 2365288190 MtrGnrtr2InvrtrRfrn2Cntr 10267;
BA_ "SPN" SG_ 2365288190 MtrGnrtr2InvrtrRfrnCrrnt 10268;
BA_ "SPN" SG_ 2365288190 MtrGnrtr2InvrtrRfrnVltg 10269;
BA_ "SPN" SG_ 2365288190 MtrGnrtr2InvrtrRfrn2Cr 10266;
BA_ "SPN" SG_ 2566615038 MtrGnrtr2InvrtrTmprtr1 10282;
BA_ "SPN" SG_ 2566615038 MtrGnrtr2InvrtrTmprtr2 10283;
BA_ "SPN" SG_ 2566615038 MtrGnrtr2InvrtrTmprtr3 10284;
BA_ "SPN" SG_ 2566615038 MtrGnrtr2InvrtrTmprtr4 10285;
BA_ "SPN" SG_ 2566615038 MtrGnrtr2InvrtrTmprtr5 20915;
BA_ "SPN" SG_ 2566615294 MotorGenerator2Temperature1 9060;
BA_ "SPN" SG_ 2566615294 MotorGenerator2Temperature2 10286;
BA_ "SPN" SG_ 2566615294 MotorGenerator2Temperature3 10287;
BA_ "SPN" SG_ 2566615294 MotorGenerator2Temperature4 10288;
BA_ "SPN" SG_ 2566615550 MotorGenerator1Temperature1 9059;
BA_ "SPN" SG_ 2566615550 MotorGenerator1Temperature2 10220;
BA_ "SPN" SG_ 2566615550 MotorGenerator1Temperature3 10221;
BA_ "SPN" SG_ 2566615550 MotorGenerator1Temperature4 10222;
BA_ "SPN" SG_ 2566615806 MtrGnrtr1InvrtrTmprtr1 10216;
BA_ "SPN" SG_ 2566615806 MtrGnrtr1InvrtrTmprtr2 10217;
BA_ "SPN" SG_ 2566615806 MtrGnrtr1InvrtrTmprtr3 10218;
BA_ "SPN" SG_ 2566615806 MtrGnrtr1InvrtrTmprtr4 10219;
BA_ "SPN" SG_ 2566615806 MtrGnrtr1InvrtrTmprtr5 20914;
BA_ "SPN" SG_ 2365289470 MtrGnrtr1InvrtrRfrn2Cntr 10201;
BA_ "SPN" SG_ 2365289470 MtrGnrtr1InvrtrRfrnCrrnt 10202;
BA_ "SPN" SG_ 2365289470 MtrGnrtr1InvrtrRfrnVltg 10203;
BA_ "SPN" SG_ 2365289470 MtrGnrtr1InvrtrRfrn2Cr 10200;
BA_ "SPN" SG_ 2365289726 MtrGnrtr1InvrtrStts1Cntr 10174;
BA_ "SPN" SG_ 2365289726 MotorGenerator1Torque 9061;
BA_ "SPN" SG_ 2365289726 MotorGenerator1Speed 9057;
BA_ "SPN" SG_ 2365289726 MtrGnrtr1InvrtrStts1Cr 10173;
BA_ "SPN" SG_ 2365289726 MtrGnrtr1InvrtrDSdCrrnt 10175;
BA_ "SPN" SG_ 2365289726 MtrGnrtr1InvrtrDSdVltg 9101;
BA_ "SPN" SG_ 2365289982 MtrGnrtr1InvrtrRfrn1Cntr 10169;
BA_ "SPN" SG_ 2365289982 MtrGnrtr1InvrtrRfrnTrq 10170;
BA_ "SPN" SG_ 2365289982 MtrGnrtr1InvrtrRfrnSpd 10171;
BA_ "SPN" SG_ 2365289982 MtrGnrtr1InvrtrRfrnPwr 10172;
BA_ "SPN" SG_ 2365289982 MtrGnrtr1InvrtrRfrn1Cr 10168;
BA_ "SPN" SG_ 2566616830 DetectionLocation1 10133;
BA_ "SPN" SG_ 2566616830 DetectionZone1 10132;
BA_ "SPN" SG_ 2566616830 ZoneAlarmStatus1 10134;
BA_ "SPN" SG_ 2566616830 DetectionLocation2 10136;
BA_ "SPN" SG_ 2566616830 DetectionZone2 10135;
BA_ "SPN" SG_ 2566616830 ZoneAlarmStatus2 10137;
BA_ "SPN" SG_ 2566616830 DetectionLocation3 10139;
BA_ "SPN" SG_ 2566616830 DetectionZone3 10138;
BA_ "SPN" SG_ 2566616830 ZoneAlarmStatus3 10140;
BA_ "SPN" SG_ 2566616830 PersonnelDetectSequenceCounter 10141;
BA_ "SPN" SG_ 2566617086 EngnClndr1CmprssnGmmRt 10077;
BA_ "SPN" SG_ 2566617086 EngnClndr1ExpnsnGmmRt 10078;
BA_ "SPN" SG_ 2566617086 EngnClndr2CmprssnGmmRt 10079;
BA_ "SPN" SG_ 2566617086 EngnClndr2ExpnsnGmmRt 10080;
BA_ "SPN" SG_ 2566617086 EngnClndr3CmprssnGmmRt 10081;
BA_ "SPN" SG_ 2566617086 EngnClndr3ExpnsnGmmRt 10082;
BA_ "SPN" SG_ 2566617086 EngnClndr4CmprssnGmmRt 10083;
BA_ "SPN" SG_ 2566617086 EngnClndr4ExpnsnGmmRt 10084;
BA_ "SPN" SG_ 2566617342 EngnClndr5CmprssnGmmRt 10085;
BA_ "SPN" SG_ 2566617342 EngnClndr5ExpnsnGmmRt 10086;
BA_ "SPN" SG_ 2566617342 EngnClndr6CmprssnGmmRt 10087;
BA_ "SPN" SG_ 2566617342 EngnClndr6ExpnsnGmmRt 10088;
BA_ "SPN" SG_ 2566617342 EngnClndr7CmprssnGmmRt 10089;
BA_ "SPN" SG_ 2566617342 EngnClndr7ExpnsnGmmRt 10090;
BA_ "SPN" SG_ 2566617342 EngnClndr8CmprssnGmmRt 10091;
BA_ "SPN" SG_ 2566617342 EngnClndr8ExpnsnGmmRt 10092;
BA_ "SPN" SG_ 2566617598 EngnClndr9CmprssnGmmRt 10093;
BA_ "SPN" SG_ 2566617598 EngnClndr9ExpnsnGmmRt 10094;
BA_ "SPN" SG_ 2566617598 EngnClndr10CmprssnGmmRt 10095;
BA_ "SPN" SG_ 2566617598 EngnClndr10ExpnsnGmmRt 10096;
BA_ "SPN" SG_ 2566617598 EngnClndr11CmprssnGmmRt 10097;
BA_ "SPN" SG_ 2566617598 EngnClndr11ExpnsnGmmRt 10098;
BA_ "SPN" SG_ 2566617598 EngnClndr12CmprssnGmmRt 10099;
BA_ "SPN" SG_ 2566617598 EngnClndr12ExpnsnGmmRt 10100;
BA_ "SPN" SG_ 2566617854 EngnClndr13CmprssnGmmRt 10101;
BA_ "SPN" SG_ 2566617854 EngnClndr13ExpnsnGmmRt 10102;
BA_ "SPN" SG_ 2566617854 EngnClndr14CmprssnGmmRt 10103;
BA_ "SPN" SG_ 2566617854 EngnClndr14ExpnsnGmmRt 10104;
BA_ "SPN" SG_ 2566617854 EngnClndr15CmprssnGmmRt 10105;
BA_ "SPN" SG_ 2566617854 EngnClndr15ExpnsnGmmRt 10106;
BA_ "SPN" SG_ 2566617854 EngnClndr16CmprssnGmmRt 10107;
BA_ "SPN" SG_ 2566617854 EngnClndr16ExpnsnGmmRt 10108;
BA_ "SPN" SG_ 2566618110 EngnClndr17CmprssnGmmRt 10109;
BA_ "SPN" SG_ 2566618110 EngnClndr17ExpnsnGmmRt 10110;
BA_ "SPN" SG_ 2566618110 EngnClndr18CmprssnGmmRt 10111;
BA_ "SPN" SG_ 2566618110 EngnClndr18ExpnsnGmmRt 10112;
BA_ "SPN" SG_ 2566618110 EngnClndr19CmprssnGmmRt 10113;
BA_ "SPN" SG_ 2566618110 EngnClndr19ExpnsnGmmRt 10114;
BA_ "SPN" SG_ 2566618110 EngnClndr20CmprssnGmmRt 10115;
BA_ "SPN" SG_ 2566618110 EngnClndr20ExpnsnGmmRt 10116;
BA_ "SPN" SG_ 2566618622 GnrtrClntPmpCntrllrSttsRsnCd 9834;
BA_ "SPN" SG_ 2566618622 GnrtrClntPmpCntrllrCmmndStts 9835;
BA_ "SPN" SG_ 2566618622 GeneratorCoolantPumpMotorSpeed 9836;
BA_ "SPN" SG_ 2566618622 GnrtrClntPmpCntrlTmprtr 9837;
BA_ "SPN" SG_ 2566618622 GeneratorCoolantPumpPower 9838;
BA_ "SPN" SG_ 2566618622 GnrtrClntPmpSrvIndtr 9839;
BA_ "SPN" SG_ 2566618622 GnrtrClntPmpOprtngStts 9840;
BA_ "SPN" SG_ 2566618622 GnrtrClntPmpMtrSpdStts 9833;
BA_ "SPN" SG_ 2566618878 GnrtrClntFnCntrllrSttsRsnCd 9821;
BA_ "SPN" SG_ 2566618878 GnrtrClntFnCntrllrCmmndStts 9822;
BA_ "SPN" SG_ 2566618878 GeneratorCoolantFanMotorSpeed 9823;
BA_ "SPN" SG_ 2566618878 GnrtrClntFnCntrlTmprtr 9824;
BA_ "SPN" SG_ 2566618878 GeneratorCoolantFanPower 9825;
BA_ "SPN" SG_ 2566618878 GnrtrClntFnSrvIndtr 9826;
BA_ "SPN" SG_ 2566618878 GnrtrClntFnOprtngStts 9827;
BA_ "SPN" SG_ 2566618878 GnrtrClntFnMtrSpdStts 9820;
BA_ "SPN" SG_ 2566619134 WllStmltnPmpOlFltrDffrntlPrssr 9813;
BA_ "SPN" SG_ 2566619134 WllStmltnPmpOlFltrBpssSwthStts 9815;
BA_ "SPN" SG_ 2566619134 WllStmltnPmpGrBxOtltOlPrssr 9814;
BA_ "SPN" SG_ 2566619390 MinimumPtoGovernorSetSpeed 9786;
BA_ "SPN" SG_ 2566619390 MaximumPtoGovernorSetSpeed 9787;
BA_ "SPN" SG_ 2566619390 PrprgrmmdPtGvrnrStSpd1 9778;
BA_ "SPN" SG_ 2566619390 PrprgrmmdPtGvrnrStSpd2 9779;
BA_ "SPN" SG_ 2566619390 PrprgrmmdPtGvrnrStSpd3 9780;
BA_ "SPN" SG_ 2566619390 PrprgrmmdPtGvrnrStSpd4 9781;
BA_ "SPN" SG_ 2566619390 PrprgrmmdPtGvrnrStSpd5 9782;
BA_ "SPN" SG_ 2566619390 PrprgrmmdPtGvrnrStSpd6 9783;
BA_ "SPN" SG_ 2566619390 PrprgrmmdPtGvrnrStSpd7 9784;
BA_ "SPN" SG_ 2566619390 PrprgrmmdPtGvrnrStSpd8 9785;
BA_ "SPN" SG_ 2566619390 PtGvrnrAlrtrOvrrdMxmmSpd 9788;
BA_ "SPN" SG_ 2566619646 OnBrdPrgrmmngInttRqst 9777;
BA_ "SPN" SG_ 2566619646 OnBrdPrgrmmngInttInht 9761;
BA_ "SPN" SG_ 2566619646 OnBrdPrgrmmngInttEAddrss 9776;
BA_ "SPN" SG_ 2566620670 EngineIdleManagementStatus 9677;
BA_ "SPN" SG_ 2566620670 IdlMngmntPndngEvntTmRmnng 10149;
BA_ "SPN" SG_ 2566620670 EngnIdlMngmntEngnRstrtRsn 9678;
BA_ "SPN" SG_ 2566620670 EngnIdlMngmntEngnShtdwnRsn 9679;
BA_ "SPN" SG_ 2566621438 StationThrottlePositionMatch 9665;
BA_ "SPN" SG_ 2566621438 StationGearPositionMatch 9666;
BA_ "SPN" SG_ 2566621438 OprtrSttnAtvBttnStts 9667;
BA_ "SPN" SG_ 2566621438 TrollingModeButtonStatus 9668;
BA_ "SPN" SG_ 2566621438 EngnThrttlLvrSnhrnztnBttnStts 9669;
BA_ "SPN" SG_ 2566621438 GearLockoutButtonStatus 9670;
BA_ "SPN" SG_ 2566621438 SlowVesselModeButtonStatus 9671;
BA_ "SPN" SG_ 2566621438 OperatorStationActiveLampStatus 9672;
BA_ "SPN" SG_ 2566621438 TrollingModeLampStatus 9673;
BA_ "SPN" SG_ 2566621438 EngnThrttlLvrSnhrnztnLmpStts 9674;
BA_ "SPN" SG_ 2566621438 GearLockoutLampStatus 9675;
BA_ "SPN" SG_ 2566621438 SlowVesselModeLampStatus 9690;
BA_ "SPN" SG_ 2566621438 MarineHeavySeaModeEnable 12303;
BA_ "SPN" SG_ 2566621694 EngineOilPressure2 9653;
BA_ "SPN" SG_ 2566621694 EngnChrgArClr2OtltPrssr 20169;
BA_ "SPN" SG_ 2566621694 EngnChrgArClr1DffrntlPrssr 5926;
BA_ "SPN" SG_ 2566621694 EngnChrgArClr2DffrntlPrssr 20170;
BA_ "SPN" SG_ 2566621694 EngnCrnksBrthrOlSprtrOtltPrssr 21146;
BA_ "SPN" SG_ 2566621694 EngineOilLevel1State 22722;
BA_ "SPN" SG_ 2566621694 EngineOilLevel2State 22723;
BA_ "SPN" SG_ 2365295358 HvessActualChargeRate 13071;
BA_ "SPN" SG_ 2365295358 HvssBsVltgNgtvTChsssGrndVltg 9580;
BA_ "SPN" SG_ 2365295358 HvssVltgLvlNgtvTChsssGrndVltg 9581;
BA_ "SPN" SG_ 2365295358 HvssTtlStrdEnrgSrLvl 22821;
BA_ "SPN" SG_ 2365295358 HvssPwrMdlEltrnsTmprtr 22822;
BA_ "SPN" SG_ 2566622206 EconomyModeTotalHoursInactive 9578;
BA_ "SPN" SG_ 2566622206 EconomyModeTripHoursInactive 9579;
BA_ "SPN" SG_ 2566622462 EnmMdEstmtdInstntnsFlSvngsRt 9576;
BA_ "SPN" SG_ 2566622462 EMdEsttdIsttsFSvsRtPt 9577;
BA_ "SPN" SG_ 2566622718 EconomyModeTotalHoursActive 9574;
BA_ "SPN" SG_ 2566622718 EconomyModeTripHoursActive 9575;
BA_ "SPN" SG_ 2566622974 EconomyModeTotalFuelUsed 9572;
BA_ "SPN" SG_ 2566622974 EconomyModeTripFuelUsed 9573;
BA_ "SPN" SG_ 2566623230 EnmMdTtlEstmtdFlSvd 9570;
BA_ "SPN" SG_ 2566623230 EnmMdTrpEstmtdFlSvd 9571;
BA_ "SPN" SG_ 2552823550 MtrGnrtr1InvrtrRtLmtsRqst1Cntr 10795;
BA_ "SPN" SG_ 2552823550 MtGt1IvtRtLtsRqstAstSpdRtLt 10796;
BA_ "SPN" SG_ 2552823550 MtGt1IvtRtLtsRqstAstTqRtLt 10797;
BA_ "SPN" SG_ 2552823550 MtrGnrtr1InvrtrRtLmtsRqst1Cr 10794;
BA_ "SPN" SG_ 2552889086 MtrGnrtr2InvrtrRtLmtsRqst1Cntr 10833;
BA_ "SPN" SG_ 2552889086 MtGt2IvtRtLtsRqstAstSpdRtLt 10834;
BA_ "SPN" SG_ 2552889086 MtGt2IvtRtLtsRqstAstTqRtLt 10835;
BA_ "SPN" SG_ 2552889086 MtrGnrtr2InvrtrRtLmtsRqst1Cr 10832;
BA_ "SPN" SG_ 2351628030 Hvesp1PowerDownCommand 11030;
BA_ "SPN" SG_ 2351628030 Hvesp1CellBalancingCommand 11033;
BA_ "SPN" SG_ 2351628030 Hvesp1OperationConsent 11035;
BA_ "SPN" SG_ 2351628030 Hvesp1Control1Counter 13029;
BA_ "SPN" SG_ 2351628030 Hvesp1Control1Crc 13030;
BA_ "SPN" SG_ 2351628030 Hvsp1HghVltgBsCnntCmmnd 11029;
BA_ "SPN" SG_ 2351628030 Hvsp1HghVltgBsAtvIsltnTstCmmnd 11031;
BA_ "SPN" SG_ 2351628030 Hvsp1HghVltgBsPssvIsltnTstCmmnd 11032;
BA_ "SPN" SG_ 2351628030 Hvsp1EnlIntrnlChrgrCmmnd 11034;
BA_ "SPN" SG_ 2351628030 Hvsp1HVtBsHSdRsstCtRqst 11036;
BA_ "SPN" SG_ 2351628030 Hvsp1HghVltgBsLwSdRsstrCnntRqst 11037;
BA_ "SPN" SG_ 2351628030 Hvsp1ThrmlMngmntMntnnRqst 20879;
BA_ "SPN" SG_ 2351693566 Hvesp2PowerDownCommand 11146;
BA_ "SPN" SG_ 2351693566 Hvesp2CellBalancingCommand 11149;
BA_ "SPN" SG_ 2351693566 Hvesp2OperationConsent 11151;
BA_ "SPN" SG_ 2351693566 Hvesp2Control1Counter 13031;
BA_ "SPN" SG_ 2351693566 Hvesp2Control1Crc 13032;
BA_ "SPN" SG_ 2351693566 Hvsp2HghVltgBsCnntCmmnd 11145;
BA_ "SPN" SG_ 2351693566 Hvsp2HghVltgBsAtvIsltnTstCmmnd 11147;
BA_ "SPN" SG_ 2351693566 Hvsp2HghVltgBsPssvIsltnTstCmmnd 11148;
BA_ "SPN" SG_ 2351693566 Hvsp2EnlIntrnlChrgrCmmnd 11150;
BA_ "SPN" SG_ 2351693566 Hvsp2HVtBsHSdRsstCtRqst 11152;
BA_ "SPN" SG_ 2351693566 Hvsp2HghVltgBsLwSdRsstrCnntRqst 11153;
BA_ "SPN" SG_ 2351693566 Hvsp2ThrmlMngmntMntnnRqst 20880;
BA_ "SPN" SG_ 2351759102 Hvesp3PowerDownCommand 11262;
BA_ "SPN" SG_ 2351759102 Hvesp3CellBalancingCommand 11265;
BA_ "SPN" SG_ 2351759102 Hvesp3OperationConsent 11267;
BA_ "SPN" SG_ 2351759102 Hvesp3Control1Counter 13033;
BA_ "SPN" SG_ 2351759102 Hvesp3Control1Crc 13034;
BA_ "SPN" SG_ 2351759102 Hvsp3HghVltgBsCnntCmmnd 11261;
BA_ "SPN" SG_ 2351759102 Hvsp3HghVltgBsAtvIsltnTstCmmnd 11263;
BA_ "SPN" SG_ 2351759102 Hvsp3HghVltgBsPssvIsltnTstCmmnd 11264;
BA_ "SPN" SG_ 2351759102 Hvsp3EnlIntrnlChrgrCmmnd 11266;
BA_ "SPN" SG_ 2351759102 Hvsp3HVtBsHSdRsstCtRqst 11268;
BA_ "SPN" SG_ 2351759102 Hvsp3HghVltgBsLwSdRsstrCnntRqst 11269;
BA_ "SPN" SG_ 2351759102 Hvsp3ThrmlMngmntMntnnRqst 20881;
